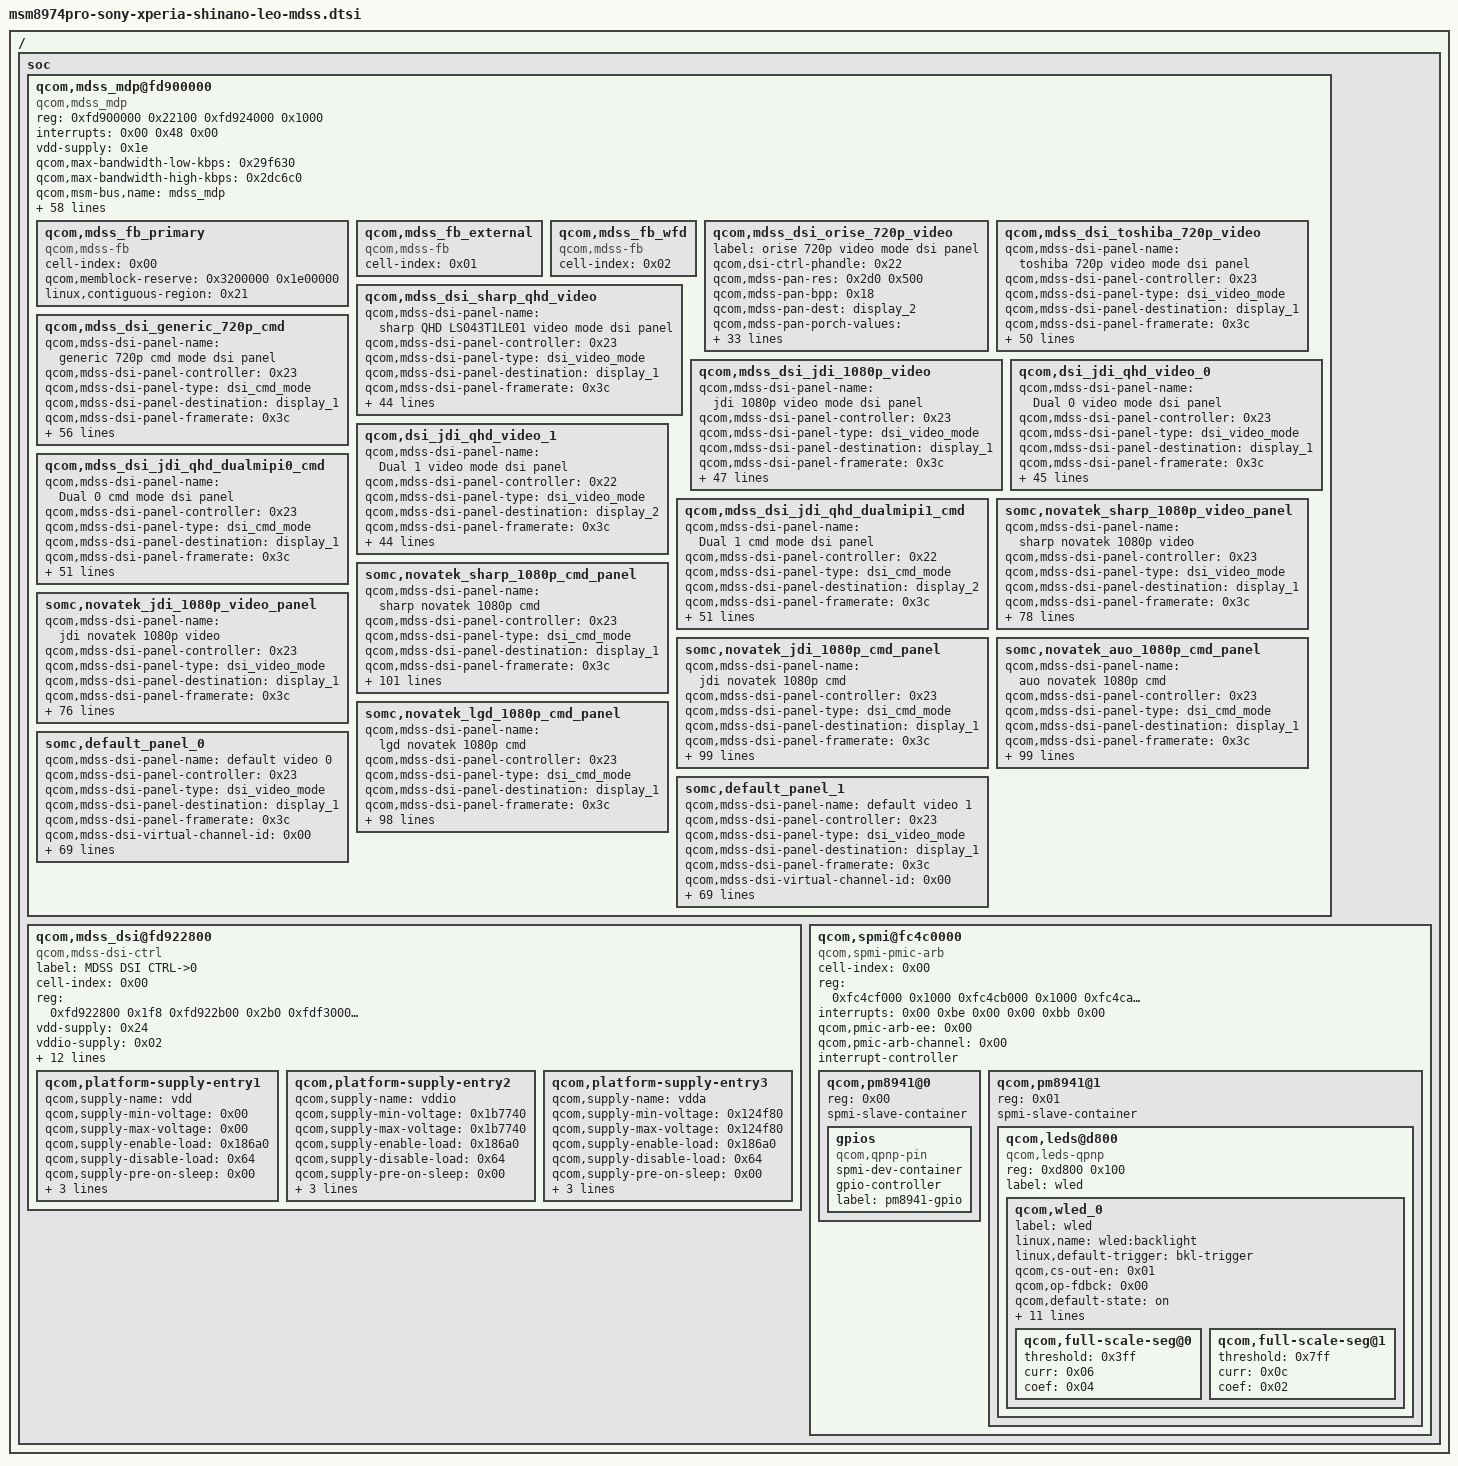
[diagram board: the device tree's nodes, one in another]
/ {
	soc {
		#address-cells = <0x01>;
		#size-cells = <0x01>;
		ranges;

		qcom,mdss_mdp@fd900000 {
			compatible = "qcom,mdss_mdp";
			reg = <0xfd900000 0x22100 0xfd924000 0x1000>;
			reg-names = "mdp_phys\0vbif_phys";
			interrupts = <0x00 0x48 0x00>;
			vdd-supply = <0x1e>;
			qcom,max-bandwidth-low-kbps = <0x29f630>;
			qcom,max-bandwidth-high-kbps = <0x2dc6c0>;
			qcom,msm-bus,name = "mdss_mdp";
			qcom,msm-bus,num-cases = <0x03>;
			qcom,msm-bus,num-paths = <0x01>;
			qcom,msm-bus,vectors-KBps = <0x16 0x200 0x00 0x00 0x16 0x200 0x00 0x61a800 0x16 0x200 0x00 0x61a800>;
			qcom,mdss-ab-factor = <0x02 0x01>;
			qcom,mdss-ib-factor = <0x13 0x0a>;
			qcom,mdss-clk-factor = <0x05 0x04>;
			qcom,mdss-ib-factor-overlap = <0x07 0x04>;
			qcom,max-clk-rate = <0x1312d000>;
			qcom,mdss-pipe-vig-off = <0x1200 0x1600 0x1a00>;
			qcom,mdss-pipe-rgb-off = <0x1e00 0x2200 0x2600>;
			qcom,mdss-pipe-dma-off = <0x2a00 0x2e00>;
			qcom,mdss-pipe-vig-fetch-id = <0x01 0x04 0x07>;
			qcom,mdss-pipe-rgb-fetch-id = <0x10 0x11 0x12>;
			qcom,mdss-pipe-dma-fetch-id = <0x0a 0x0d>;
			qcom,mdss-pipe-vig-xin-id = <0x00 0x04 0x08>;
			qcom,mdss-pipe-rgb-xin-id = <0x01 0x05 0x09>;
			qcom,mdss-pipe-dma-xin-id = <0x02 0x0a>;
			qcom,mdss-pipe-vig-clk-ctrl-offsets = <0x3ac 0x00 0x00 0x3b4 0x00 0x00 0x3bc 0x00 0x00>;
			qcom,mdss-pipe-rgb-clk-ctrl-offsets = <0x3ac 0x04 0x08 0x3b4 0x04 0x08 0x3bc 0x04 0x08>;
			qcom,mdss-pipe-dma-clk-ctrl-offsets = <0x3ac 0x08 0x0c 0x3b4 0x08 0x0c>;
			qcom,mdss-smp-data = <0x16 0x1000>;
			qcom,mdss-ctl-off = <0x600 0x700 0x800 0x900 0xa00>;
			qcom,mdss-mixer-intf-off = <0x3200 0x3600 0x3a00>;
			qcom,mdss-mixer-wb-off = <0x3e00 0x4200>;
			qcom,mdss-dspp-off = <0x4600 0x4a00 0x4e00>;
			qcom,mdss-wb-off = <0x11100 0x11500 0x11900 0x11d00 0x12100>;
			qcom,mdss-intf-off = <0x12500 0x12700 0x12900 0x12b00>;
			qcom,mdss-has-wfd-blk;
			qcom,vbif-settings = <0x04 0x01>;
			qcom,mdp-settings = <0x2e0 0xe9 0x2e4 0x55 0x3ac 0xc0000ccc 0x3b4 0xc0000ccc 0x3bc 0xcccccc 0x4a8 0xcccc0c0 0x4b0 0xccccc0c0 0x4b8 0xccccc000>;
			qcom,mdss-prefill-outstanding-buffer-bytes = <0x400>;
			qcom,mdss-prefill-y-buffer-bytes = <0x1000>;
			qcom,mdss-prefill-scaler-buffer-lines-bilinear = <0x02>;
			qcom,mdss-prefill-scaler-buffer-lines-caf = <0x04>;
			qcom,mdss-prefill-post-scaler-buffer-pixels = <0x00>;
			qcom,mdss-prefill-pingpong-buffer-pixels = <0x1000>;
			qcom,mdss-prefill-fbc-lines = <0x02>;
			qcom,mdss-pingpong-off = <0x12d00 0x12e00 0x12f00>;
			qcom,mdss-has-bwc;
			qcom,mdss-has-decimation;
			qcom,mdss-ad-off = <0x13100 0x13300>;
			vdd-cx-supply = <0x1f>;
			qcom,mdss-pref-prim-intf = "dsi";
			batfet-supply = <0x20>;
			linux,phandle = <0x27>;
			phandle = <0x27>;

			qcom,mdss_fb_primary {
				cell-index = <0x00>;
				compatible = "qcom,mdss-fb";
				qcom,memblock-reserve = <0x3200000 0x1e00000>;
				linux,contiguous-region = <0x21>;
				linux,phandle = <0x26>;
				phandle = <0x26>;
			};

			qcom,mdss_fb_external {
				cell-index = <0x01>;
				compatible = "qcom,mdss-fb";
				linux,phandle = <0x2d>;
				phandle = <0x2d>;
			};

			qcom,mdss_fb_wfd {
				cell-index = <0x02>;
				compatible = "qcom,mdss-fb";
				linux,phandle = <0x2e>;
				phandle = <0x2e>;
			};

			qcom,mdss_dsi_orise_720p_video {
				label = "orise 720p video mode dsi panel";
				qcom,dsi-ctrl-phandle = <0x22>;
				qcom,mdss-pan-res = <0x2d0 0x500>;
				qcom,mdss-pan-bpp = <0x18>;
				qcom,mdss-pan-dest = "display_2";
				qcom,mdss-pan-porch-values = <0x20 0x0c 0x90 0x03 0x04 0x09>;
				qcom,mdss-pan-underflow-clr = <0xff>;
				qcom,mdss-pan-bl-levels = <0x01 0xff>;
				qcom,mdss-pan-dsi-mode = <0x00>;
				qcom,mdss-pan-dsi-h-pulse-mode = <0x00>;
				qcom,mdss-pan-dsi-h-power-stop = <0x00 0x00 0x00>;
				qcom,mdss-pan-dsi-bllp-power-stop = <0x01 0x01>;
				qcom,mdss-pan-dsi-traffic-mode = <0x01>;
				qcom,mdss-pan-dsi-dst-format = <0x03>;
				qcom,mdss-pan-dsi-vc = <0x00>;
				qcom,mdss-pan-dsi-rgb-swap = <0x00>;
				qcom,mdss-pan-dsi-data-lanes = <0x01 0x01 0x01 0x01>;
				qcom,mdss-pan-dsi-dlane-swap = <0x00>;
				qcom,mdss-pan-dsi-t-clk = <0x1b 0x04>;
				qcom,mdss-pan-dsi-stream = <0x00>;
				qcom,mdss-pan-dsi-mdp-tr = <0x00>;
				qcom,mdss-pan-dsi-dma-tr = <0x04>;
				qcom,mdss-pan-dsi-framerate = <0x3c>;
				qcom,panel-phy-regulatorSettings = [03 01 01 00 20 00 01];
				qcom,panel-phy-timingSettings = <0x69291f00 0x5555192a 0x2a030400>;
				qcom,panel-phy-strengthCtrl = [77 06];
				qcom,panel-phy-bistCtrl = [00 00 b1 ff 00 00];
				qcom,panel-phy-laneConfig = [00 c2 45 00 00 00 00 01 75 00 c2 45 00 00 00 00 01 75 00 c2 45 00 00 00 00 01 75 00 c2 45 00 00 00 00 01 75 00 02 45 00 00 00 00 01 97];
				qcom,panel-on-cmds = [05 01 00 00 78 00 02 11 00 05 01 00 00 78 00 02 29 00];
				qcom,on-cmds-dsi-state = "DSI_LP_MODE";
				qcom,panel-off-cmds = [05 01 00 00 32 00 02 28 00 05 01 00 00 78 00 02 10 00];
				qcom,off-cmds-dsi-state = "DSI_LP_MODE";
			};

			qcom,mdss_dsi_toshiba_720p_video {
				qcom,mdss-dsi-panel-name = "toshiba 720p video mode dsi panel";
				qcom,mdss-dsi-panel-controller = <0x23>;
				qcom,mdss-dsi-panel-type = "dsi_video_mode";
				qcom,mdss-dsi-panel-destination = "display_1";
				qcom,mdss-dsi-panel-framerate = <0x3c>;
				qcom,mdss-dsi-virtual-channel-id = <0x00>;
				qcom,mdss-dsi-stream = <0x00>;
				qcom,mdss-dsi-panel-width = <0x2d0>;
				qcom,mdss-dsi-panel-height = <0x500>;
				qcom,mdss-dsi-h-front-porch = <0x90>;
				qcom,mdss-dsi-h-back-porch = <0x20>;
				qcom,mdss-dsi-h-pulse-width = <0x0c>;
				qcom,mdss-dsi-h-sync-skew = <0x00>;
				qcom,mdss-dsi-v-back-porch = <0x03>;
				qcom,mdss-dsi-v-front-porch = <0x09>;
				qcom,mdss-dsi-v-pulse-width = <0x04>;
				qcom,mdss-dsi-h-left-border = <0x00>;
				qcom,mdss-dsi-h-right-border = <0x00>;
				qcom,mdss-dsi-v-top-border = <0x00>;
				qcom,mdss-dsi-v-bottom-border = <0x00>;
				qcom,mdss-dsi-bpp = <0x18>;
				qcom,mdss-dsi-underflow-color = <0xff>;
				qcom,mdss-dsi-border-color = <0x00>;
				qcom,mdss-dsi-on-command = [23 01 00 00 0a 00 02 b0 00 23 01 00 00 0a 00 02 b2 00 23 01 00 00 0a 00 02 b3 0c 23 01 00 00 0a 00 02 b4 02 29 01 00 00 00 00 06 c0 40 02 7f c8 08 29 01 00 00 00 00 10 c1 00 a8 00 00 00 00 00 9d 08 27 00 00 00 00 00 29 01 00 00 00 00 06 c2 00 00 09 00 00 23 01 00 00 0a 00 02 c3 04 29 01 00 00 00 00 04 c4 4d 83 00 29 01 00 00 00 00 0b c6 12 00 08 71 00 00 00 80 00 04 23 01 00 00 0a 00 02 c7 22 29 01 00 00 00 00 05 c8 4c 0c 0c 0c 29 01 00 00 00 00 0e c9 00 40 00 16 32 2e 3a 43 3e 3c 45 79 3f 29 01 00 00 00 00 0e ca 00 46 1a 23 21 1c 25 31 2d 49 5f 7f 3f 29 01 00 00 00 00 0e cb 00 4c 20 3a 42 40 47 4b 42 3e 46 7e 3f 29 01 00 00 00 00 0e cc 00 41 19 21 1d 14 18 1f 1d 25 3f 73 3f 29 01 00 00 00 00 0e cd 23 79 5a 5f 57 4c 51 51 45 3f 4b 7f 3f 29 01 00 00 00 00 0e ce 00 40 14 20 1a 0e 0e 13 08 00 05 46 1c 29 01 00 00 00 00 04 d0 6a 64 01 29 01 00 00 00 00 03 d1 77 d4 23 01 00 00 0a 00 02 d3 33 29 01 00 00 00 00 03 d5 0f 0f 29 01 00 00 00 00 07 d8 34 64 23 25 62 32 29 01 00 00 00 00 0c de 10 7b 11 0a 00 00 00 00 00 00 00 29 01 00 00 00 00 09 fd 04 55 53 00 70 ff 10 73 23 01 00 00 0a 00 02 e2 00 05 01 00 00 78 00 02 11 00 05 01 00 00 32 00 02 29 00];
				qcom,mdss-dsi-off-command = [05 01 00 00 32 00 02 28 00 05 01 00 00 78 00 02 10 00];
				qcom,mdss-dsi-on-command-state = "dsi_lp_mode";
				qcom,mdss-dsi-off-command-state = "dsi_hs_mode";
				qcom,mdss-dsi-h-sync-pulse = <0x00>;
				qcom,mdss-dsi-traffic-mode = "non_burst_sync_event";
				qcom,mdss-dsi-bllp-eof-power-mode;
				qcom,mdss-dsi-bllp-power-mode;
				qcom,mdss-dsi-lane-0-state;
				qcom,mdss-dsi-lane-1-state;
				qcom,mdss-dsi-lane-2-state;
				qcom,mdss-dsi-lane-3-state;
				qcom,mdss-dsi-panel-timings = <0xb0231b00 0x94931e25 0x15030400>;
				qcom,mdss-dsi-t-clk-post = <0x04>;
				qcom,mdss-dsi-t-clk-pre = <0x1b>;
				qcom,mdss-dsi-bl-min-level = <0x01>;
				qcom,mdss-dsi-bl-max-level = <0xfff>;
				qcom,mdss-dsi-dma-trigger = "trigger_sw";
				qcom,mdss-dsi-mdp-trigger = "none";
				qcom,mdss-dsi-bl-pmic-control-type = "bl_ctrl_wled";
				qcom,mdss-dsi-pan-enable-dynamic-fps;
				qcom,mdss-dsi-pan-fps-update = "dfps_immediate_porch_mode";
				qcom,mdss-dsi-min-refresh-rate = <0x2d>;
				qcom,mdss-dsi-reset-sequence = <0x01 0x14 0x00 0xc8 0x01 0x14>;
				qcom,cont-splash-enabled;
			};

			qcom,mdss_dsi_sharp_qhd_video {
				qcom,mdss-dsi-panel-name = "sharp QHD LS043T1LE01 video mode dsi panel";
				qcom,mdss-dsi-panel-controller = <0x23>;
				qcom,mdss-dsi-panel-type = "dsi_video_mode";
				qcom,mdss-dsi-panel-destination = "display_1";
				qcom,mdss-dsi-panel-framerate = <0x3c>;
				qcom,mdss-dsi-virtual-channel-id = <0x00>;
				qcom,mdss-dsi-stream = <0x00>;
				qcom,mdss-dsi-panel-width = <0x21c>;
				qcom,mdss-dsi-panel-height = <0x3c0>;
				qcom,mdss-dsi-h-front-porch = <0x30>;
				qcom,mdss-dsi-h-back-porch = <0x50>;
				qcom,mdss-dsi-h-pulse-width = <0x20>;
				qcom,mdss-dsi-h-sync-skew = <0x00>;
				qcom,mdss-dsi-v-back-porch = <0x0f>;
				qcom,mdss-dsi-v-front-porch = <0x03>;
				qcom,mdss-dsi-v-pulse-width = <0x0a>;
				qcom,mdss-dsi-h-left-border = <0x00>;
				qcom,mdss-dsi-h-right-border = <0x00>;
				qcom,mdss-dsi-v-top-border = <0x00>;
				qcom,mdss-dsi-v-bottom-border = <0x00>;
				qcom,mdss-dsi-bpp = <0x18>;
				qcom,mdss-dsi-color-order = "rgb_swap_bgr";
				qcom,mdss-dsi-underflow-color = <0xff>;
				qcom,mdss-dsi-border-color = <0x00>;
				qcom,mdss-dsi-on-command = [05 01 00 00 32 00 02 01 00 05 01 00 00 0a 00 02 11 00 15 01 00 00 0a 00 02 53 2c 15 01 00 00 0a 00 02 51 ff 05 01 00 00 0a 00 02 29 00 15 01 00 00 0a 00 02 ae 03 15 01 00 00 0a 00 02 3a 77];
				qcom,mdss-dsi-off-command = [05 01 00 00 0a 00 02 28 00 05 01 00 00 78 00 02 10 00];
				qcom,mdss-dsi-on-command-state = "dsi_lp_mode";
				qcom,mdss-dsi-off-command-state = "dsi_hs_mode";
				qcom,mdss-dsi-h-sync-pulse = <0x01>;
				qcom,mdss-dsi-traffic-mode = "non_burst_sync_pulse";
				qcom,mdss-dsi-bllp-eof-power-mode;
				qcom,mdss-dsi-bllp-power-mode;
				qcom,mdss-dsi-lane-0-state;
				qcom,mdss-dsi-lane-1-state;
				qcom,mdss-dsi-panel-timings = <0x461d2000 0x393a2121 0x32030400>;
				qcom,mdss-dsi-t-clk-post = <0x04>;
				qcom,mdss-dsi-t-clk-pre = <0x1c>;
				qcom,mdss-dsi-bl-min-level = <0x01>;
				qcom,mdss-dsi-bl-max-level = <0xfff>;
				qcom,mdss-dsi-dma-trigger = "trigger_sw";
				qcom,mdss-dsi-mdp-trigger = "trigger_sw";
				qcom,mdss-dsi-bl-pmic-control-type = "bl_ctrl_wled";
				qcom,mdss-dsi-reset-sequence = <0x01 0x14 0x00 0xc8 0x01 0x14>;
			};

			qcom,mdss_dsi_generic_720p_cmd {
				qcom,mdss-dsi-panel-name = "generic 720p cmd mode dsi panel";
				qcom,mdss-dsi-panel-controller = <0x23>;
				qcom,mdss-dsi-panel-type = "dsi_cmd_mode";
				qcom,mdss-dsi-panel-destination = "display_1";
				qcom,mdss-dsi-panel-framerate = <0x3c>;
				qcom,mdss-dsi-stream = <0x00>;
				qcom,mdss-dsi-panel-width = <0x300>;
				qcom,mdss-dsi-panel-height = <0x500>;
				qcom,mdss-dsi-h-front-porch = <0x1a>;
				qcom,mdss-dsi-h-back-porch = <0x1a>;
				qcom,mdss-dsi-h-pulse-width = <0x1a>;
				qcom,mdss-dsi-h-sync-skew = <0x00>;
				qcom,mdss-dsi-v-back-porch = <0x02>;
				qcom,mdss-dsi-v-front-porch = <0x02>;
				qcom,mdss-dsi-v-pulse-width = <0x02>;
				qcom,mdss-dsi-h-left-border = <0x00>;
				qcom,mdss-dsi-h-right-border = <0x00>;
				qcom,mdss-dsi-v-top-border = <0x00>;
				qcom,mdss-dsi-v-bottom-border = <0x00>;
				qcom,mdss-dsi-bpp = <0x18>;
				qcom,mdss-dsi-underflow-color = <0xff>;
				qcom,mdss-dsi-border-color = <0x00>;
				qcom,mdss-dsi-on-command = [05 01 00 00 78 00 01 11 15 01 00 00 0a 00 02 36 00 05 01 00 00 0a 00 01 29 15 01 00 00 0a 00 02 53 24 15 01 00 00 0a 00 02 35 00];
				qcom,mdss-dsi-off-command = [05 01 00 00 0a 00 01 34 05 01 00 00 78 00 01 10 05 01 00 00 78 00 01 28 15 01 00 00 0a 00 02 53 00];
				qcom,mdss-dsi-on-command-state = "dsi_lp_mode";
				qcom,mdss-dsi-off-command-state = "dsi_hs_mode";
				qcom,mdss-dsi-h-sync-pulse = <0x00>;
				qcom,mdss-dsi-traffic-mode = "non_burst_sync_event";
				qcom,mdss-dsi-bllp-eof-power-mode;
				qcom,mdss-dsi-bllp-power-mode;
				qcom,mdss-dsi-lane-0-state;
				qcom,mdss-dsi-lane-1-state;
				qcom,mdss-dsi-lane-2-state;
				qcom,mdss-dsi-lane-3-state;
				qcom,mdss-dsi-te-pin-select = <0x01>;
				qcom,mdss-dsi-wr-mem-start = <0x2c>;
				qcom,mdss-dsi-wr-mem-continue = <0x3c>;
				qcom,mdss-dsi-te-dcs-command = <0x01>;
				qcom,mdss-dsi-te-check-enable;
				qcom,mdss-dsi-te-using-te-pin;
				qcom,mdss-dsi-panel-timings = <0x6e261b00 0x35342028 0x17030400>;
				qcom,mdss-dsi-t-clk-post = <0x20>;
				qcom,mdss-dsi-t-clk-pre = <0x2a>;
				qcom,mdss-dsi-bl-min-level = <0x01>;
				qcom,mdss-dsi-bl-max-level = <0xff>;
				qcom,mdss-dsi-bl-pmic-pwm-frequency = <0x64>;
				qcom,mdss-dsi-bl-pmic-bank-select = <0x07>;
				qcom,mdss-dsi-dma-trigger = "trigger_sw";
				qcom,mdss-dsi-mdp-trigger = "none";
				qcom,mdss-dsi-bl-pmic-control-type = "bl_ctrl_pwm";
				qcom,mdss-dsi-reset-sequence = <0x01 0x14 0x00 0xc8 0x01 0x14>;
				qcom,panel-roi-alignment = <0x02 0x02 0x02 0x02 0x00 0x00>;
				qcom,partial-update-enabled;
				qcom,cont-splash-enabled;
			};

			qcom,mdss_dsi_jdi_1080p_video {
				qcom,mdss-dsi-panel-name = "jdi 1080p video mode dsi panel";
				qcom,mdss-dsi-panel-controller = <0x23>;
				qcom,mdss-dsi-panel-type = "dsi_video_mode";
				qcom,mdss-dsi-panel-destination = "display_1";
				qcom,mdss-dsi-panel-framerate = <0x3c>;
				qcom,mdss-dsi-virtual-channel-id = <0x00>;
				qcom,mdss-dsi-stream = <0x00>;
				qcom,mdss-dsi-panel-width = <0x438>;
				qcom,mdss-dsi-panel-height = <0x780>;
				qcom,mdss-dsi-h-front-porch = <0x60>;
				qcom,mdss-dsi-h-back-porch = <0x40>;
				qcom,mdss-dsi-h-pulse-width = <0x10>;
				qcom,mdss-dsi-h-sync-skew = <0x00>;
				qcom,mdss-dsi-v-back-porch = <0x10>;
				qcom,mdss-dsi-v-front-porch = <0x04>;
				qcom,mdss-dsi-v-pulse-width = <0x01>;
				qcom,mdss-dsi-h-left-border = <0x00>;
				qcom,mdss-dsi-h-right-border = <0x00>;
				qcom,mdss-dsi-v-top-border = <0x00>;
				qcom,mdss-dsi-v-bottom-border = <0x00>;
				qcom,mdss-dsi-bpp = <0x18>;
				qcom,mdss-dsi-underflow-color = <0xff>;
				qcom,mdss-dsi-border-color = <0x00>;
				qcom,mdss-dsi-on-command = [15 01 00 00 00 00 02 55 00 15 01 00 00 00 00 02 53 2c 15 01 00 00 00 00 02 35 00 05 01 00 00 78 00 02 29 00 05 01 00 00 78 00 02 11 00];
				qcom,mdss-dsi-off-command = [05 01 00 00 02 00 02 28 00 05 01 00 00 79 00 02 10 00];
				qcom,mdss-dsi-on-command-state = "dsi_lp_mode";
				qcom,mdss-dsi-off-command-state = "dsi_hs_mode";
				qcom,mdss-dsi-h-sync-pulse = <0x00>;
				qcom,mdss-dsi-traffic-mode = "burst_mode";
				qcom,mdss-dsi-bllp-eof-power-mode;
				qcom,mdss-dsi-bllp-power-mode;
				qcom,mdss-dsi-lane-0-state;
				qcom,mdss-dsi-lane-1-state;
				qcom,mdss-dsi-lane-2-state;
				qcom,mdss-dsi-lane-3-state;
				qcom,mdss-dsi-panel-timings = <0xe7362400 0x666a2a3a 0x2d030400>;
				qcom,mdss-dsi-t-clk-post = <0x04>;
				qcom,mdss-dsi-t-clk-pre = <0x1b>;
				qcom,mdss-dsi-bl-min-level = <0x01>;
				qcom,mdss-dsi-bl-max-level = <0xfff>;
				qcom,mdss-dsi-dma-trigger = "trigger_sw";
				qcom,mdss-dsi-mdp-trigger = "none";
				qcom,mdss-dsi-bl-pmic-control-type = "bl_ctrl_wled";
				qcom,mdss-dsi-reset-sequence = <0x01 0x14 0x00 0xc8 0x01 0x14>;
				qcom,mdss-pan-physical-width-dimension = <0x3d>;
				qcom,mdss-pan-physical-height-dimension = <0x6e>;
				qcom,cont-splash-enabled;
			};

			qcom,dsi_jdi_qhd_video_0 {
				qcom,mdss-dsi-panel-name = "Dual 0 video mode dsi panel";
				qcom,mdss-dsi-panel-controller = <0x23>;
				qcom,mdss-dsi-panel-type = "dsi_video_mode";
				qcom,mdss-dsi-panel-destination = "display_1";
				qcom,mdss-dsi-panel-framerate = <0x3c>;
				qcom,mdss-dsi-virtual-channel-id = <0x00>;
				qcom,mdss-dsi-stream = <0x00>;
				qcom,mdss-dsi-panel-width = <0x500>;
				qcom,mdss-dsi-panel-height = <0x5a0>;
				qcom,mdss-dsi-h-front-porch = <0x78>;
				qcom,mdss-dsi-h-back-porch = <0x2c>;
				qcom,mdss-dsi-h-pulse-width = <0x10>;
				qcom,mdss-dsi-h-sync-skew = <0x00>;
				qcom,mdss-dsi-v-back-porch = <0x04>;
				qcom,mdss-dsi-v-front-porch = <0x08>;
				qcom,mdss-dsi-v-pulse-width = <0x04>;
				qcom,mdss-dsi-h-left-border = <0x00>;
				qcom,mdss-dsi-h-right-border = <0x00>;
				qcom,mdss-dsi-v-top-border = <0x00>;
				qcom,mdss-dsi-v-bottom-border = <0x00>;
				qcom,mdss-dsi-bpp = <0x18>;
				qcom,mdss-dsi-underflow-color = <0xff>;
				qcom,mdss-dsi-border-color = <0x00>;
				qcom,mdss-dsi-h-sync-pulse = <0x00>;
				qcom,mdss-dsi-traffic-mode = "non_burst_sync_event";
				qcom,mdss-dsi-bllp-eof-power-mode;
				qcom,mdss-dsi-bllp-power-mode;
				qcom,mdss-dsi-panel-broadcast-mode;
				qcom,mdss-dsi-lane-0-state;
				qcom,mdss-dsi-lane-1-state;
				qcom,mdss-dsi-lane-2-state;
				qcom,mdss-dsi-lane-3-state;
				qcom,mdss-dsi-panel-timings = <0xcd322200 0x60642634 0x29030400>;
				qcom,mdss-dsi-t-clk-post = <0x03>;
				qcom,mdss-dsi-t-clk-pre = <0x27>;
				qcom,mdss-dsi-bl-max-level = <0xfff>;
				qcom,mdss-dsi-dma-trigger = "trigger_sw";
				qcom,mdss-dsi-mdp-trigger = "none";
				qcom,mdss-dsi-bl-pmic-control-type = "bl_ctrl_pwm";
				qcom,mdss-dsi-on-command = [05 01 00 00 0a 00 01 00 15 01 00 00 0a 00 02 3a 77 39 01 00 00 0a 00 05 2a 00 00 04 ff 39 01 00 00 0a 00 05 2b 00 00 05 9f 15 01 00 00 0a 00 02 35 00 39 01 00 00 0a 00 03 44 00 00 15 01 00 00 0a 00 02 51 ff 15 01 00 00 0a 00 02 53 24 15 01 00 00 0a 00 02 55 00 05 01 00 00 78 00 01 11 23 01 00 00 0a 00 02 b0 00 29 01 00 00 0a 00 02 b3 14 29 01 00 00 0a 00 14 ce 7d 40 48 56 67 78 88 98 a7 b5 c3 d1 de e9 f2 fa ff 04 00 23 01 00 00 0a 00 02 b0 03 05 01 00 00 10 00 01 29];
				qcom,mdss-dsi-on-command-state = "dsi_lp_mode";
				qcom,mdss-dsi-off-command = [05 01 00 00 32 00 02 28 00 05 01 00 00 78 00 02 10 00];
				qcom,mdss-dsi-off-command-state = "dsi_hs_mode";
				qcom,mdss-dsi-reset-sequence = <0x01 0x14 0x00 0xc8 0x01 0x14>;
			};

			qcom,dsi_jdi_qhd_video_1 {
				qcom,mdss-dsi-panel-name = "Dual 1 video mode dsi panel";
				qcom,mdss-dsi-panel-controller = <0x22>;
				qcom,mdss-dsi-panel-type = "dsi_video_mode";
				qcom,mdss-dsi-panel-destination = "display_2";
				qcom,mdss-dsi-panel-framerate = <0x3c>;
				qcom,mdss-dsi-virtual-channel-id = <0x00>;
				qcom,mdss-dsi-stream = <0x00>;
				qcom,mdss-dsi-panel-width = <0x500>;
				qcom,mdss-dsi-panel-height = <0x5a0>;
				qcom,mdss-dsi-h-front-porch = <0x78>;
				qcom,mdss-dsi-h-back-porch = <0x2c>;
				qcom,mdss-dsi-h-pulse-width = <0x10>;
				qcom,mdss-dsi-h-sync-skew = <0x00>;
				qcom,mdss-dsi-v-back-porch = <0x04>;
				qcom,mdss-dsi-v-front-porch = <0x08>;
				qcom,mdss-dsi-v-pulse-width = <0x04>;
				qcom,mdss-dsi-h-left-border = <0x00>;
				qcom,mdss-dsi-h-right-border = <0x00>;
				qcom,mdss-dsi-v-top-border = <0x00>;
				qcom,mdss-dsi-v-bottom-border = <0x00>;
				qcom,mdss-dsi-bpp = <0x18>;
				qcom,mdss-dsi-underflow-color = <0xff>;
				qcom,mdss-dsi-border-color = <0x00>;
				qcom,mdss-dsi-h-sync-pulse = <0x00>;
				qcom,mdss-dsi-traffic-mode = "non_burst_sync_event";
				qcom,mdss-dsi-bllp-eof-power-mode;
				qcom,mdss-dsi-bllp-power-mode;
				qcom,mdss-dsi-lane-0-state;
				qcom,mdss-dsi-lane-1-state;
				qcom,mdss-dsi-lane-2-state;
				qcom,mdss-dsi-lane-3-state;
				qcom,mdss-dsi-panel-broadcast-mode;
				qcom,mdss-dsi-panel-timings = <0xcd322200 0x60642634 0x29030400>;
				qcom,mdss-dsi-t-clk-post = <0x03>;
				qcom,mdss-dsi-t-clk-pre = <0x27>;
				qcom,mdss-dsi-bl-min-level = <0x01>;
				qcom,mdss-dsi-bl-max-level = <0xfff>;
				qcom,mdss-dsi-dma-trigger = "trigger_sw";
				qcom,mdss-dsi-mdp-trigger = "none";
				qcom,mdss-dsi-on-command = [05 01 00 00 0a 00 01 00 15 01 00 00 0a 00 02 3a 77 39 01 00 00 0a 00 05 2a 00 00 04 ff 39 01 00 00 0a 00 05 2b 00 00 05 9f 15 01 00 00 0a 00 02 35 00 39 01 00 00 0a 00 03 44 00 00 15 01 00 00 0a 00 02 51 ff 15 01 00 00 0a 00 02 53 24 15 01 00 00 0a 00 02 55 00 05 01 00 00 78 00 01 11 23 01 00 00 0a 00 02 b0 00 29 01 00 00 0a 00 02 b3 14 29 01 00 00 0a 00 14 ce 7d 40 48 56 67 78 88 98 a7 b5 c3 d1 de e9 f2 fa ff 04 00 23 01 00 00 0a 00 02 b0 03 05 01 00 00 10 00 01 29];
				qcom,mdss-dsi-on-command-state = "dsi_lp_mode";
				qcom,mdss-dsi-off-command = [05 01 00 00 32 00 02 28 00 05 01 00 00 78 00 02 10 00];
				qcom,mdss-dsi-off-command-state = "dsi_hs_mode";
				qcom,mdss-dsi-reset-sequence = <0x01 0x14 0x00 0xc8 0x01 0x14>;
			};

			qcom,mdss_dsi_jdi_qhd_dualmipi0_cmd {
				qcom,mdss-dsi-panel-name = "Dual 0 cmd mode dsi panel";
				qcom,mdss-dsi-panel-controller = <0x23>;
				qcom,mdss-dsi-panel-type = "dsi_cmd_mode";
				qcom,mdss-dsi-panel-destination = "display_1";
				qcom,mdss-dsi-panel-framerate = <0x3c>;
				qcom,mdss-dsi-virtual-channel-id = <0x00>;
				qcom,mdss-dsi-stream = <0x00>;
				qcom,mdss-dsi-panel-width = <0x500>;
				qcom,mdss-dsi-panel-height = <0x5a0>;
				qcom,mdss-dsi-h-front-porch = <0x78>;
				qcom,mdss-dsi-h-back-porch = <0x2c>;
				qcom,mdss-dsi-h-pulse-width = <0x10>;
				qcom,mdss-dsi-h-sync-skew = <0x00>;
				qcom,mdss-dsi-v-back-porch = <0x04>;
				qcom,mdss-dsi-v-front-porch = <0x08>;
				qcom,mdss-dsi-v-pulse-width = <0x04>;
				qcom,mdss-dsi-h-left-border = <0x00>;
				qcom,mdss-dsi-h-right-border = <0x00>;
				qcom,mdss-dsi-v-top-border = <0x00>;
				qcom,mdss-dsi-v-bottom-border = <0x00>;
				qcom,mdss-dsi-bpp = <0x18>;
				qcom,mdss-dsi-color-order = "rgb_swap_rgb";
				qcom,mdss-dsi-underflow-color = <0xff>;
				qcom,mdss-dsi-border-color = <0x00>;
				qcom,mdss-dsi-h-sync-pulse = <0x00>;
				qcom,mdss-dsi-traffic-mode = "non_burst_sync_event";
				qcom,mdss-dsi-lane-map = "lane_map_0123";
				qcom,mdss-dsi-bllp-eof-power-mode;
				qcom,mdss-dsi-bllp-power-mode;
				qcom,mdss-dsi-panel-broadcast-mode;
				qcom,mdss-dsi-lane-0-state;
				qcom,mdss-dsi-lane-1-state;
				qcom,mdss-dsi-lane-2-state;
				qcom,mdss-dsi-lane-3-state;
				qcom,mdss-dsi-panel-timings = <0xcd322200 0x60642634 0x29030400>;
				qcom,mdss-dsi-reset-sequence = <0x01 0xc8 0x00 0xc8 0x01 0x14>;
				qcom,mdss-dsi-t-clk-post = <0x03>;
				qcom,mdss-dsi-t-clk-pre = <0x27>;
				qcom,mdss-dsi-bl-max-level = <0xfff>;
				qcom,mdss-dsi-dma-trigger = "trigger_sw";
				qcom,mdss-dsi-mdp-trigger = "none";
				qcom,mdss-dsi-te-pin-select = <0x01>;
				qcom,mdss-dsi-te-v-sync-rd-ptr-irq-line = <0x2c>;
				qcom,mdss-dsi-te-v-sync-continues-lines = <0x3c>;
				qcom,mdss-dsi-te-dcs-command = <0x01>;
				qcom,mdss-dsi-te-check-enable;
				qcom,mdss-dsi-te-using-te-pin;
				qcom,mdss-dsi-on-command = <0x29010000 0x2b0 0x3050100 0xa0001 0x150100 0xa0002 0x3a773901 0xa00 0x52a0000 0x4ff3901 0xa00 0x52b0000 0x59f1501 0xa00 0x2350039 0x100000a 0x34400 0x150100 0xa0002 0x51ff1501 0xa00 0x2532415 0x100000a 0x25500 0x5010000 0x78000111 0x5010000 0x10000129>;
				qcom,mdss-dsi-on-command-state = "dsi_lp_mode";
				qcom,mdss-dsi-off-command = [05 01 00 00 32 00 02 28 00 05 01 00 00 78 00 02 10 00];
				qcom,mdss-dsi-off-command-state = "dsi_hs_mode";
			};

			qcom,mdss_dsi_jdi_qhd_dualmipi1_cmd {
				qcom,mdss-dsi-panel-name = "Dual 1 cmd mode dsi panel";
				qcom,mdss-dsi-panel-controller = <0x22>;
				qcom,mdss-dsi-panel-type = "dsi_cmd_mode";
				qcom,mdss-dsi-panel-destination = "display_2";
				qcom,mdss-dsi-panel-framerate = <0x3c>;
				qcom,mdss-dsi-virtual-channel-id = <0x00>;
				qcom,mdss-dsi-stream = <0x00>;
				qcom,mdss-dsi-panel-width = <0x500>;
				qcom,mdss-dsi-panel-height = <0x5a0>;
				qcom,mdss-dsi-h-front-porch = <0x78>;
				qcom,mdss-dsi-h-back-porch = <0x2c>;
				qcom,mdss-dsi-h-pulse-width = <0x10>;
				qcom,mdss-dsi-h-sync-skew = <0x00>;
				qcom,mdss-dsi-v-back-porch = <0x04>;
				qcom,mdss-dsi-v-front-porch = <0x08>;
				qcom,mdss-dsi-v-pulse-width = <0x04>;
				qcom,mdss-dsi-h-left-border = <0x00>;
				qcom,mdss-dsi-h-right-border = <0x00>;
				qcom,mdss-dsi-v-top-border = <0x00>;
				qcom,mdss-dsi-v-bottom-border = <0x00>;
				qcom,mdss-dsi-bpp = <0x18>;
				qcom,mdss-dsi-color-order = "rgb_swap_rgb";
				qcom,mdss-dsi-underflow-color = <0xff>;
				qcom,mdss-dsi-border-color = <0x00>;
				qcom,mdss-dsi-h-sync-pulse = <0x00>;
				qcom,mdss-dsi-traffic-mode = "non_burst_sync_event";
				qcom,mdss-dsi-lane-map = "lane_map_0123";
				qcom,mdss-dsi-bllp-eof-power-mode;
				qcom,mdss-dsi-bllp-power-mode;
				qcom,mdss-dsi-panel-broadcast-mode;
				qcom,mdss-dsi-lane-0-state;
				qcom,mdss-dsi-lane-1-state;
				qcom,mdss-dsi-lane-2-state;
				qcom,mdss-dsi-lane-3-state;
				qcom,mdss-dsi-panel-timings = <0xcd322200 0x60642634 0x29030400>;
				qcom,mdss-dsi-reset-sequence = <0x01 0xc8 0x00 0xc8 0x01 0x14>;
				qcom,mdss-dsi-t-clk-post = <0x03>;
				qcom,mdss-dsi-t-clk-pre = <0x27>;
				qcom,mdss-dsi-bl-max-level = <0xfff>;
				qcom,mdss-dsi-dma-trigger = "trigger_sw";
				qcom,mdss-dsi-mdp-trigger = "none";
				qcom,mdss-dsi-te-pin-select = <0x01>;
				qcom,mdss-dsi-te-v-sync-rd-ptr-irq-line = <0x2c>;
				qcom,mdss-dsi-te-v-sync-continues-lines = <0x3c>;
				qcom,mdss-dsi-te-dcs-command = <0x01>;
				qcom,mdss-dsi-te-check-enable;
				qcom,mdss-dsi-te-using-te-pin;
				qcom,mdss-dsi-on-command = <0x29010000 0x2b0 0x3050100 0xa0001 0x150100 0xa0002 0x3a773901 0xa00 0x52a0000 0x4ff3901 0xa00 0x52b0000 0x59f1501 0xa00 0x2350039 0x100000a 0x34400 0x150100 0xa0002 0x51ff1501 0xa00 0x2532415 0x100000a 0x25500 0x5010000 0x78000111 0x5010000 0x10000129>;
				qcom,mdss-dsi-on-command-state = "dsi_lp_mode";
				qcom,mdss-dsi-off-command = [05 01 00 00 32 00 02 28 00 05 01 00 00 78 00 02 10 00];
				qcom,mdss-dsi-off-command-state = "dsi_hs_mode";
			};

			somc,novatek_sharp_1080p_video_panel {
				qcom,mdss-dsi-panel-name = "sharp novatek 1080p video";
				qcom,mdss-dsi-panel-controller = <0x23>;
				qcom,mdss-dsi-panel-type = "dsi_video_mode";
				qcom,mdss-dsi-panel-destination = "display_1";
				qcom,mdss-dsi-panel-framerate = <0x3c>;
				qcom,mdss-dsi-virtual-channel-id = <0x00>;
				qcom,mdss-dsi-stream = <0x00>;
				qcom,mdss-dsi-panel-width = <0x438>;
				qcom,mdss-dsi-panel-height = <0x780>;
				qcom,mdss-dsi-h-front-porch = <0x88>;
				qcom,mdss-dsi-h-back-porch = <0x14>;
				qcom,mdss-dsi-h-pulse-width = <0x3c>;
				qcom,mdss-dsi-h-sync-skew = <0x00>;
				qcom,mdss-dsi-v-back-porch = <0x03>;
				qcom,mdss-dsi-v-front-porch = <0x04>;
				qcom,mdss-dsi-v-pulse-width = <0x02>;
				qcom,mdss-dsi-h-left-border = <0x00>;
				qcom,mdss-dsi-h-right-border = <0x00>;
				qcom,mdss-dsi-v-top-border = <0x00>;
				qcom,mdss-dsi-v-bottom-border = <0x00>;
				qcom,mdss-dsi-bpp = <0x18>;
				qcom,mdss-dsi-underflow-color = <0x00>;
				qcom,mdss-dsi-border-color = <0x00>;
				somc,mdss-dsi-init-command = [15 01 00 00 00 00 02 bb 03 39 01 00 00 00 00 06 3b 03 05 04 50 88 15 01 00 00 00 00 02 ff 24 15 01 00 00 00 00 02 fb 01 15 01 00 00 00 00 02 c4 9a 15 01 00 00 00 00 02 ff 10];
				qcom,mdss-dsi-on-command = <0x5010000 0x96000111 0x5010000 0x28000129>;
				qcom,mdss-dsi-off-command = [15 01 00 00 00 00 02 ff 10 05 01 00 00 14 00 01 28 05 01 00 00 50 00 01 10];
				qcom,mdss-dsi-on-command-state = "dsi_lp_mode";
				qcom,mdss-dsi-off-command-state = "dsi_hs_mode";
				qcom,mdss-dsi-h-sync-pulse = <0x01>;
				qcom,mdss-dsi-traffic-mode = "non_burst_sync_event";
				qcom,mdss-dsi-bllp-eof-power-mode;
				qcom,mdss-dsi-bllp-power-mode;
				qcom,mdss-dsi-lane-0-state;
				qcom,mdss-dsi-lane-1-state;
				qcom,mdss-dsi-lane-2-state;
				qcom,mdss-dsi-lane-3-state;
				qcom,mdss-dsi-panel-timings = <0xe6382600 0x686e2a3c 0x2c030400>;
				qcom,mdss-dsi-lp11-init;
				qcom,mdss-dsi-t-clk-post = <0x02>;
				qcom,mdss-dsi-t-clk-pre = <0x2b>;
				qcom,mdss-dsi-bl-min-level = <0x01>;
				qcom,mdss-dsi-bl-max-level = <0xfff>;
				qcom,mdss-brightness-max-level = <0xfff>;
				qcom,mdss-dsi-dma-trigger = "trigger_sw";
				qcom,mdss-dsi-mdp-trigger = "none";
				qcom,mdss-dsi-bl-pmic-control-type = "bl_ctrl_wled";
				qcom,mdss-dsi-pan-enable-dynamic-fps;
				qcom,mdss-dsi-pan-fps-update = "dfps_suspend_resume_mode";
				qcom,cont-splash-enabled;
				qcom,mdss-dsi-tx-eot-append;
				somc,driver-ic = <0x00>;
				somc,dric-gpio = <0x05 0x1a 0x00>;
				somc,touch-reset-gpio = <0x05 0x55 0x00>;
				somc,mul-channel-scaling = <0x03>;
				somc,mdss-phy-size-mm = <0x40 0x72>;
				somc,mdss-dsi-lane-config = [00 c2 ef 00 00 00 00 01 ff 00 c2 ef 00 00 00 00 01 ff 00 c2 ef 00 00 00 00 01 ff 00 c2 ef 00 00 00 00 01 ff 00 02 45 00 00 00 00 01 97];
				somc,mdss-dsi-disp-on-in-hs = <0x01>;
				somc,mdss-dsi-wait-time-before-on-cmd = <0x96>;
				somc,lcd-id = <0x01>;
				somc,lcd-id-adc = <0x347d8 0x3e800>;
				somc,disp-en-on-pre = <0xc8>;
				somc,disp-en-on-post = <0x0a>;
				somc,pw-on-rst-seq = <0x01 0x01 0x00 0x01 0x01 0x14>;
				somc,disp-en-off-post = <0xc8>;
				somc,pw-off-rst-seq = <0x00 0x05>;
				somc,pw-down-period = <0x64>;
				somc,mdss-dsi-pre-uv-command = [23 01 00 00 00 00 02 b0 04];
				somc,mdss-dsi-uv-command = <0x6010000 0x1da 0x6010000 0x1db>;
				somc,mdss-dsi-uv-param-type = <0x04>;
				somc,mdss-dsi-pcc-table-size = <0xe1>;
				somc,mdss-dsi-pcc-table = <0x00 0x01 0x38 0x3b 0x38 0x3b 0x5700 0x7000 0x8000 0x00 0x02 0x34 0x37 0x38 0x3b 0x5900 0x6f00 0x8000 0x00 0x03 0x30 0x33 0x38 0x3b 0x5c00 0x6e00 0x8000 0x00 0x04 0x2c 0x2f 0x38 0x3b 0x5d80 0x6c80 0x8000 0x00 0x05 0x28 0x2b 0x38 0x3b 0x6080 0x6c80 0x8000 0x00 0x06 0x24 0x27 0x38 0x3b 0x6380 0x6c80 0x8000 0x00 0x07 0x20 0x23 0x38 0x3b 0x6700 0x6c00 0x8000 0x00 0x08 0x1c 0x1f 0x38 0x3b 0x6980 0x6b00 0x8000 0x00 0x09 0x18 0x1b 0x38 0x3b 0x6d00 0x6a80 0x8000 0x00 0x0a 0x14 0x17 0x38 0x3b 0x7180 0x6900 0x8000 0x00 0x0b 0x10 0x13 0x38 0x3b 0x7800 0x6800 0x8000 0x00 0x0c 0x0c 0x0f 0x38 0x3b 0x7d00 0x6700 0x8000 0x00 0x0d 0x08 0x0b 0x38 0x3b 0x8000 0x6500 0x7d00 0x00 0x0e 0x04 0x07 0x38 0x3b 0x8000 0x6000 0x7700 0x00 0x0f 0x00 0x03 0x38 0x3b 0x8000 0x5900 0x7000 0x00 0x10 0x38 0x3b 0x34 0x37 0x5900 0x7280 0x8000 0x00 0x11 0x34 0x37 0x34 0x37 0x5b00 0x7100 0x8000 0x00 0x12 0x30 0x33 0x34 0x37 0x5e00 0x7180 0x8000 0x00 0x13 0x2c 0x2f 0x34 0x37 0x6080 0x7180 0x8000 0x00 0x14 0x28 0x2b 0x34 0x37 0x6400 0x7000 0x8000 0x00 0x15 0x24 0x27 0x34 0x37 0x6700 0x7000 0x8000 0x00 0x16 0x20 0x23 0x34 0x37 0x6900 0x6f00 0x8000 0x00 0x17 0x1c 0x1f 0x34 0x37 0x6c00 0x6e80 0x8000 0x00 0x18 0x18 0x1b 0x34 0x37 0x7000 0x6d80 0x8000 0x00 0x19 0x14 0x17 0x34 0x37 0x7580 0x6b80 0x8000 0x00 0x1a 0x10 0x13 0x34 0x37 0x7b00 0x6a80 0x8000 0x00 0x1b 0x0c 0x0f 0x34 0x37 0x8000 0x6a80 0x8000 0x00 0x1c 0x08 0x0b 0x34 0x37 0x8000 0x6600 0x7c00 0x00 0x1d 0x04 0x07 0x34 0x37 0x8000 0x6100 0x7400 0x00 0x1e 0x00 0x03 0x34 0x37 0x8000 0x5b00 0x6e00 0x00 0x1f 0x38 0x3b 0x30 0x33 0x5c80 0x7600 0x8000 0x00 0x20 0x34 0x37 0x30 0x33 0x5e00 0x7500 0x8000 0x00 0x21 0x30 0x33 0x30 0x33 0x6100 0x7480 0x8000 0x00 0x22 0x2c 0x2f 0x30 0x33 0x6400 0x7400 0x8000 0x00 0x23 0x28 0x2b 0x30 0x33 0x6500 0x7300 0x8000 0x00 0x24 0x24 0x27 0x30 0x33 0x6880 0x7400 0x8000 0x00 0x25 0x20 0x23 0x30 0x33 0x6b00 0x7200 0x8000 0x00 0x26 0x1c 0x1f 0x30 0x33 0x6e00 0x6f00 0x8000 0x00 0x27 0x18 0x1b 0x30 0x33 0x7300 0x7080 0x8000 0x00 0x28 0x14 0x17 0x30 0x33 0x7700 0x6d80 0x8000 0x00 0x29 0x10 0x13 0x30 0x33 0x7c00 0x6d80 0x8000 0x00 0x2a 0x0c 0x0f 0x30 0x33 0x8000 0x6c00 0x7e00 0x00 0x2b 0x08 0x0b 0x30 0x33 0x8000 0x6700 0x7a00 0x00 0x2c 0x04 0x07 0x30 0x33 0x8000 0x6100 0x7200 0x00 0x2d 0x00 0x03 0x30 0x33 0x8000 0x5b00 0x6c00 0x00 0x2e 0x38 0x3b 0x2c 0x2f 0x5c00 0x7880 0x8000 0x00 0x2f 0x34 0x37 0x2c 0x2f 0x5f00 0x7700 0x8000 0x00 0x30 0x30 0x33 0x2c 0x2f 0x6100 0x7700 0x8000 0x00 0x31 0x2c 0x2f 0x2c 0x2f 0x6500 0x7680 0x8000 0x00 0x32 0x28 0x2b 0x2c 0x2f 0x6700 0x7600 0x8000 0x00 0x33 0x24 0x27 0x2c 0x2f 0x6a00 0x7500 0x8000 0x00 0x34 0x20 0x23 0x2c 0x2f 0x6e00 0x7500 0x8000 0x00 0x35 0x1c 0x1f 0x2c 0x2f 0x7180 0x7400 0x8000 0x00 0x36 0x18 0x1b 0x2c 0x2f 0x7580 0x7300 0x8000 0x00 0x37 0x14 0x17 0x2c 0x2f 0x7b00 0x7080 0x8000 0x00 0x38 0x10 0x13 0x2c 0x2f 0x8000 0x7080 0x7f00 0x00 0x39 0x0c 0x0f 0x2c 0x2f 0x8000 0x6b00 0x7a00 0x00 0x3a 0x08 0x0b 0x2c 0x2f 0x8000 0x6500 0x7400 0x00 0x3b 0x04 0x07 0x2c 0x2f 0x8000 0x6000 0x6d00 0x00 0x3c 0x00 0x03 0x2c 0x2f 0x8000 0x5a00 0x6800 0x00 0x3d 0x38 0x3b 0x28 0x2b 0x6000 0x7c00 0x8000 0x00 0x3e 0x34 0x37 0x28 0x2b 0x6200 0x7b00 0x8000 0x00 0x3f 0x30 0x33 0x28 0x2b 0x6600 0x7b00 0x8000 0x00 0x40 0x2c 0x2f 0x28 0x2b 0x6900 0x7c00 0x8000 0x00 0x41 0x28 0x2b 0x28 0x2b 0x6b80 0x7900 0x8000 0x00 0x42 0x24 0x27 0x28 0x2b 0x6e00 0x7900 0x8000 0x00 0x43 0x20 0x23 0x28 0x2b 0x7100 0x7780 0x8000 0x00 0x44 0x1c 0x1f 0x28 0x2b 0x7500 0x7700 0x8000 0x00 0x45 0x18 0x1b 0x28 0x2b 0x7a00 0x7600 0x8000 0x00 0x46 0x14 0x17 0x28 0x2b 0x8000 0x7500 0x8000 0x00 0x47 0x10 0x13 0x28 0x2b 0x8000 0x7000 0x7c00 0x00 0x48 0x0c 0x0f 0x28 0x2b 0x8000 0x6b00 0x7800 0x00 0x49 0x08 0x0b 0x28 0x2b 0x8000 0x6600 0x7200 0x00 0x4a 0x04 0x07 0x28 0x2b 0x8000 0x6000 0x6c00 0x00 0x4b 0x00 0x03 0x28 0x2b 0x8000 0x5900 0x6500 0x00 0x4c 0x38 0x3b 0x24 0x27 0x6200 0x8000 0x8000 0x00 0x4d 0x34 0x37 0x24 0x27 0x6500 0x7f00 0x8000 0x00 0x4e 0x30 0x33 0x24 0x27 0x6800 0x7f00 0x8000 0x00 0x4f 0x2c 0x2f 0x24 0x27 0x6b00 0x7e00 0x8000 0x00 0x50 0x28 0x2b 0x24 0x27 0x6e00 0x7c80 0x8000 0x00 0x51 0x24 0x27 0x24 0x27 0x7200 0x7d00 0x8000 0x00 0x52 0x20 0x23 0x24 0x27 0x7500 0x7a00 0x8000 0x00 0x53 0x1c 0x1f 0x24 0x27 0x7900 0x7a00 0x8000 0x00 0x54 0x18 0x1b 0x24 0x27 0x7e00 0x7a00 0x8000 0x00 0x55 0x14 0x17 0x24 0x27 0x8000 0x7300 0x7c00 0x00 0x56 0x10 0x13 0x24 0x27 0x8000 0x6e00 0x7800 0x00 0x57 0x0c 0x0f 0x24 0x27 0x8000 0x6900 0x7300 0x00 0x58 0x08 0x0b 0x24 0x27 0x8000 0x6400 0x6d00 0x00 0x59 0x04 0x07 0x24 0x27 0x8000 0x5e00 0x6800 0x00 0x5a 0x00 0x03 0x24 0x27 0x8000 0x5900 0x6300 0x00 0x5b 0x38 0x3b 0x20 0x23 0x6200 0x8000 0x7d00 0x00 0x5c 0x34 0x37 0x20 0x23 0x6600 0x8000 0x7e00 0x00 0x5d 0x30 0x33 0x20 0x23 0x6a00 0x8000 0x7f00 0x00 0x5e 0x2c 0x2f 0x20 0x23 0x6d00 0x8000 0x7f00 0x00 0x5f 0x28 0x2b 0x20 0x23 0x7100 0x8000 0x8000 0x00 0x60 0x24 0x27 0x20 0x23 0x7400 0x7f00 0x8000 0x00 0x61 0x20 0x23 0x20 0x23 0x7700 0x7e80 0x8000 0x00 0x62 0x1c 0x1f 0x20 0x23 0x7b00 0x7d00 0x8000 0x00 0x63 0x18 0x1b 0x20 0x23 0x7f00 0x7c00 0x8000 0x00 0x64 0x14 0x17 0x20 0x23 0x8000 0x7500 0x7b00 0x00 0x65 0x10 0x13 0x20 0x23 0x8000 0x7000 0x7600 0x00 0x66 0x0c 0x0f 0x20 0x23 0x8000 0x6a00 0x7100 0x00 0x67 0x08 0x0b 0x20 0x23 0x8000 0x6400 0x6b00 0x00 0x68 0x04 0x07 0x20 0x23 0x8000 0x5e00 0x6600 0x00 0x69 0x00 0x03 0x20 0x23 0x8000 0x5800 0x6000 0x00 0x6a 0x38 0x3b 0x1c 0x1f 0x6300 0x8000 0x7a00 0x00 0x6b 0x34 0x37 0x1c 0x1f 0x6600 0x8000 0x7b00 0x00 0x6c 0x30 0x33 0x1c 0x1f 0x6a00 0x8000 0x7c00 0x00 0x6d 0x2c 0x2f 0x1c 0x1f 0x6e00 0x8000 0x7d00 0x00 0x6e 0x28 0x2b 0x1c 0x1f 0x7200 0x8000 0x7e00 0x00 0x6f 0x24 0x27 0x1c 0x1f 0x7600 0x8000 0x7e00 0x00 0x70 0x20 0x23 0x1c 0x1f 0x7a00 0x8000 0x7f00 0x00 0x71 0x18 0x1b 0x1c 0x1f 0x8000 0x7c00 0x7c00 0x00 0x72 0x14 0x17 0x1c 0x1f 0x8000 0x7400 0x7780 0x00 0x73 0x10 0x13 0x1c 0x1f 0x8000 0x6f00 0x7300 0x00 0x74 0x0c 0x0f 0x1c 0x1f 0x8000 0x6900 0x6e00 0x00 0x75 0x08 0x0b 0x1c 0x1f 0x8000 0x6300 0x6800 0x00 0x76 0x04 0x07 0x1c 0x1f 0x8000 0x5d00 0x6280 0x00 0x77 0x00 0x03 0x1c 0x1f 0x8000 0x5800 0x5d00 0x00 0x78 0x38 0x3b 0x18 0x1b 0x6300 0x8000 0x7800 0x00 0x79 0x34 0x37 0x18 0x1b 0x6700 0x8000 0x7900 0x00 0x7a 0x30 0x33 0x18 0x1b 0x6a00 0x8000 0x7900 0x00 0x7b 0x2c 0x2f 0x18 0x1b 0x6e00 0x8000 0x7b00 0x00 0x7c 0x28 0x2b 0x18 0x1b 0x7180 0x8000 0x7c00 0x00 0x7d 0x24 0x27 0x18 0x1b 0x7500 0x8000 0x7b00 0x00 0x7e 0x20 0x23 0x18 0x1b 0x7a00 0x8000 0x7c80 0x00 0x7f 0x1c 0x1f 0x18 0x1b 0x8000 0x8000 0x7e00 0x00 0x80 0x18 0x1b 0x18 0x1b 0x8000 0x7a00 0x7900 0x00 0x81 0x14 0x17 0x18 0x1b 0x8000 0x7400 0x7500 0x00 0x82 0x10 0x13 0x18 0x1b 0x8000 0x6e00 0x6f00 0x00 0x83 0x0c 0x0f 0x18 0x1b 0x8000 0x6900 0x6b00 0x00 0x84 0x08 0x0b 0x18 0x1b 0x8000 0x6200 0x6500 0x00 0x85 0x04 0x07 0x18 0x1b 0x8000 0x5d00 0x6000 0x00 0x86 0x00 0x03 0x18 0x1b 0x8000 0x5700 0x5b00 0x00 0x87 0x38 0x3b 0x14 0x17 0x6300 0x8000 0x7580 0x00 0x88 0x34 0x37 0x14 0x17 0x6700 0x8000 0x7680 0x00 0x89 0x30 0x33 0x14 0x17 0x6a00 0x8000 0x7780 0x00 0x8a 0x2c 0x2f 0x14 0x17 0x6d00 0x8000 0x7800 0x00 0x8b 0x28 0x2b 0x14 0x17 0x7100 0x8000 0x7800 0x00 0x8c 0x24 0x27 0x14 0x17 0x7500 0x8000 0x7980 0x00 0x8d 0x20 0x23 0x14 0x17 0x7a00 0x8000 0x7a00 0x00 0x8e 0x1c 0x1f 0x14 0x17 0x7f00 0x8000 0x7a80 0x00 0x8f 0x18 0x1b 0x14 0x17 0x8000 0x7b00 0x7700 0x00 0x90 0x14 0x17 0x14 0x17 0x8000 0x7300 0x7100 0x00 0x91 0x10 0x13 0x14 0x17 0x8000 0x6d00 0x6d00 0x00 0x92 0x0c 0x0f 0x14 0x17 0x8000 0x6800 0x6900 0x00 0x93 0x08 0x0b 0x14 0x17 0x8000 0x6200 0x6300 0x00 0x94 0x04 0x07 0x14 0x17 0x8000 0x5c00 0x5d00 0x00 0x95 0x00 0x03 0x14 0x17 0x8000 0x5600 0x5900 0x00 0x96 0x38 0x3b 0x10 0x13 0x6300 0x8000 0x7300 0x00 0x97 0x34 0x37 0x10 0x13 0x6600 0x8000 0x7400 0x00 0x98 0x30 0x33 0x10 0x13 0x6a00 0x8000 0x7500 0x00 0x99 0x2c 0x2f 0x10 0x13 0x6e00 0x8000 0x7600 0x00 0x9a 0x28 0x2b 0x10 0x13 0x7100 0x8000 0x7600 0x00 0x9b 0x24 0x27 0x10 0x13 0x7500 0x8000 0x7700 0x00 0x9c 0x20 0x23 0x10 0x13 0x7980 0x8000 0x7800 0x00 0x9d 0x1c 0x1f 0x10 0x13 0x7f00 0x8000 0x7800 0x00 0x9e 0x18 0x1b 0x10 0x13 0x8000 0x7b00 0x7500 0x00 0x9f 0x14 0x17 0x10 0x13 0x8000 0x7300 0x6f00 0x00 0xa0 0x10 0x13 0x10 0x13 0x8000 0x6d00 0x6b00 0x00 0xa1 0x0c 0x0f 0x10 0x13 0x8000 0x6800 0x6600 0x00 0xa2 0x08 0x0b 0x10 0x13 0x8000 0x6200 0x6000 0x00 0xa3 0x04 0x07 0x10 0x13 0x8000 0x5b00 0x5b00 0x00 0xa4 0x00 0x03 0x10 0x13 0x8000 0x5600 0x5700 0x00 0xa5 0x38 0x3b 0x0c 0x0f 0x6200 0x8000 0x7000 0x00 0xa6 0x34 0x37 0x0c 0x0f 0x6700 0x8000 0x7100 0x00 0xa7 0x30 0x33 0x0c 0x0f 0x6a00 0x8000 0x7200 0x00 0xa8 0x2c 0x2f 0x0c 0x0f 0x6d00 0x8000 0x7300 0x00 0xa9 0x28 0x2b 0x0c 0x0f 0x7100 0x8000 0x7400 0x00 0xaa 0x24 0x27 0x0c 0x0f 0x7500 0x8000 0x7480 0x00 0xab 0x20 0x23 0x0c 0x0f 0x7900 0x8000 0x7500 0x00 0xac 0x1c 0x1f 0x0c 0x0f 0x7f00 0x8000 0x7600 0x00 0xad 0x18 0x1b 0x0c 0x0f 0x8000 0x7b00 0x7200 0x00 0xae 0x14 0x17 0x0c 0x0f 0x8000 0x7300 0x6d00 0x00 0xaf 0x10 0x13 0x0c 0x0f 0x8000 0x6d00 0x6800 0x00 0xb0 0x0c 0x0f 0x0c 0x0f 0x8000 0x6800 0x6400 0x00 0xb1 0x08 0x0b 0x0c 0x0f 0x8000 0x6100 0x5d00 0x00 0xb2 0x04 0x07 0x0c 0x0f 0x8000 0x5b00 0x5900 0x00 0xb3 0x00 0x03 0x0c 0x0f 0x8000 0x5600 0x5480 0x00 0xb4 0x38 0x3b 0x08 0x0b 0x6200 0x8000 0x6e00 0x00 0xb5 0x34 0x37 0x08 0x0b 0x6600 0x8000 0x6e00 0x00 0xb6 0x30 0x33 0x08 0x0b 0x6900 0x8000 0x6f00 0x00 0xb7 0x2c 0x2f 0x08 0x0b 0x6d00 0x8000 0x7000 0x00 0xb8 0x28 0x2b 0x08 0x0b 0x7100 0x8000 0x7200 0x00 0xb9 0x24 0x27 0x08 0x0b 0x7500 0x8000 0x7200 0x00 0xba 0x20 0x23 0x08 0x0b 0x7a00 0x8000 0x7200 0x00 0xbb 0x1c 0x1f 0x08 0x0b 0x7f00 0x8000 0x7300 0x00 0xbc 0x18 0x1b 0x08 0x0b 0x8000 0x7b00 0x7000 0x00 0xbd 0x14 0x17 0x08 0x0b 0x8000 0x7200 0x6a00 0x00 0xbe 0x10 0x13 0x08 0x0b 0x8000 0x6c00 0x6500 0x00 0xbf 0x0c 0x0f 0x08 0x0b 0x8000 0x6600 0x6000 0x00 0xc0 0x08 0x0b 0x08 0x0b 0x8000 0x6000 0x5b00 0x00 0xc1 0x04 0x07 0x08 0x0b 0x8000 0x5b00 0x5700 0x00 0xc2 0x00 0x03 0x08 0x0b 0x8000 0x5500 0x5100 0x00 0xc3 0x38 0x3b 0x04 0x07 0x6200 0x8000 0x6b00 0x00 0xc4 0x34 0x37 0x04 0x07 0x6500 0x8000 0x6c00 0x00 0xc5 0x30 0x33 0x04 0x07 0x6800 0x8000 0x6d80 0x00 0xc6 0x2c 0x2f 0x04 0x07 0x6c00 0x8000 0x6e00 0x00 0xc7 0x28 0x2b 0x04 0x07 0x7000 0x8000 0x6e00 0x00 0xc8 0x24 0x27 0x04 0x07 0x7400 0x8000 0x6f00 0x00 0xc9 0x20 0x23 0x04 0x07 0x7800 0x8000 0x7000 0x00 0xca 0x1c 0x1f 0x04 0x07 0x7e00 0x8000 0x7000 0x00 0xcb 0x18 0x1b 0x04 0x07 0x8000 0x7a80 0x6b80 0x00 0xcc 0x14 0x17 0x04 0x07 0x8000 0x7400 0x6780 0x00 0xcd 0x10 0x13 0x04 0x07 0x8000 0x6e00 0x6380 0x00 0xce 0x0c 0x0f 0x04 0x07 0x8000 0x6700 0x5e00 0x00 0xcf 0x08 0x0b 0x04 0x07 0x8000 0x6180 0x5980 0x00 0xd0 0x04 0x07 0x04 0x07 0x8000 0x5b00 0x5500 0x00 0xd1 0x00 0x03 0x04 0x07 0x8000 0x5500 0x5100 0x00 0xd2 0x38 0x3b 0x00 0x03 0x6100 0x8000 0x6900 0x00 0xd3 0x34 0x37 0x00 0x03 0x6400 0x8000 0x6a00 0x00 0xd4 0x30 0x33 0x00 0x03 0x6800 0x8000 0x6b00 0x00 0xd5 0x2c 0x2f 0x00 0x03 0x6c00 0x8000 0x6b80 0x00 0xd6 0x28 0x2b 0x00 0x03 0x6f00 0x8000 0x6c00 0x00 0xd7 0x24 0x27 0x00 0x03 0x7300 0x8000 0x6d00 0x00 0xd8 0x20 0x23 0x00 0x03 0x7900 0x8000 0x6d00 0x00 0xd9 0x1c 0x1f 0x00 0x03 0x7f00 0x8000 0x6e00 0x00 0xda 0x18 0x1b 0x00 0x03 0x8000 0x7b00 0x6a80 0x00 0xdb 0x14 0x17 0x00 0x03 0x8000 0x7400 0x6580 0x00 0xdc 0x10 0x13 0x00 0x03 0x8000 0x6d00 0x6180 0x00 0xdd 0x0c 0x0f 0x00 0x03 0x8000 0x6900 0x5e00 0x00 0xde 0x08 0x0b 0x00 0x03 0x8000 0x6200 0x5800 0x00 0xdf 0x04 0x07 0x00 0x03 0x8000 0x5a00 0x5200 0x00 0xe0 0x00 0x03 0x00 0x03 0x8000 0x5400 0x4d00 0xff 0x00 0x00 0x3b 0x00 0x3b 0x8000 0x8000 0x8000>;
			};

			somc,novatek_sharp_1080p_cmd_panel {
				qcom,mdss-dsi-panel-name = "sharp novatek 1080p cmd";
				qcom,mdss-dsi-panel-controller = <0x23>;
				qcom,mdss-dsi-panel-type = "dsi_cmd_mode";
				qcom,mdss-dsi-panel-destination = "display_1";
				qcom,mdss-dsi-panel-framerate = <0x3c>;
				qcom,mdss-dsi-virtual-channel-id = <0x00>;
				qcom,mdss-dsi-stream = <0x00>;
				qcom,mdss-dsi-panel-width = <0x438>;
				qcom,mdss-dsi-panel-height = <0x780>;
				qcom,mdss-dsi-h-front-porch = <0x38>;
				qcom,mdss-dsi-h-back-porch = <0x08>;
				qcom,mdss-dsi-h-pulse-width = <0x08>;
				qcom,mdss-dsi-h-sync-skew = <0x00>;
				qcom,mdss-dsi-v-back-porch = <0x08>;
				qcom,mdss-dsi-v-front-porch = <0xe9>;
				qcom,mdss-dsi-v-pulse-width = <0x02>;
				qcom,mdss-dsi-h-left-border = <0x00>;
				qcom,mdss-dsi-h-right-border = <0x00>;
				qcom,mdss-dsi-v-top-border = <0x00>;
				qcom,mdss-dsi-v-bottom-border = <0x00>;
				qcom,mdss-dsi-bpp = <0x18>;
				qcom,mdss-dsi-underflow-color = <0x00>;
				qcom,mdss-dsi-border-color = <0x00>;
				somc,mdss-dsi-init-command = [15 01 00 00 00 00 02 bb 10 15 01 00 00 00 00 02 ff 24 15 01 00 00 00 00 02 fb 01 15 01 00 00 00 00 02 c4 9a 15 01 00 00 00 00 02 85 05 15 01 00 00 00 00 02 93 02 15 01 00 00 00 00 02 94 08 15 01 00 00 00 00 02 92 95 15 01 00 00 00 00 02 ff 10 15 01 00 00 00 00 02 ff 20 15 01 00 00 00 00 02 fb 01 15 01 00 00 00 00 02 58 82 15 01 00 00 00 00 02 59 02 15 01 00 00 00 00 02 5a 02 15 01 00 00 00 00 02 5b 02 15 01 00 00 00 00 02 5c 83 15 01 00 00 00 00 02 5d 83 15 01 00 00 00 00 02 5e 03 15 01 00 00 00 00 02 5f 03 15 01 00 00 00 00 02 6d 55 15 01 00 00 00 00 02 ff 10 15 01 00 00 00 00 02 ff 24 15 01 00 00 00 00 02 fb 01 15 01 00 00 00 00 02 c4 02 15 01 00 00 00 00 02 ff 10 15 01 00 00 00 00 02 35 00 39 01 00 00 00 00 03 44 03 00 15 01 00 00 00 00 02 ff e0 15 01 00 00 00 00 02 fb 01 15 01 00 00 00 00 02 b5 86 15 01 00 00 00 00 02 b6 77 15 01 00 00 00 00 02 b8 ad 15 01 00 00 00 00 02 ff 20 15 01 00 00 00 00 02 fb 01 15 01 00 00 00 00 02 10 04 15 01 00 00 00 00 02 ff 10 05 01 00 00 1e 00 01 11];
				qcom,mdss-dsi-on-command = <0x5010000 0x28000129>;
				qcom,mdss-dsi-off-command = [15 01 00 00 00 00 02 ff 10 05 01 00 00 14 00 01 28 05 01 00 00 50 00 01 10];
				qcom,mdss-dsi-on-command-state = "dsi_hs_mode";
				qcom,mdss-dsi-off-command-state = "dsi_hs_mode";
				qcom,mdss-dsi-h-sync-pulse = <0x01>;
				qcom,mdss-dsi-traffic-mode = "non_burst_sync_event";
				qcom,mdss-dsi-bllp-eof-power-mode;
				qcom,mdss-dsi-bllp-power-mode;
				qcom,mdss-dsi-lane-0-state;
				qcom,mdss-dsi-lane-1-state;
				qcom,mdss-dsi-lane-2-state;
				qcom,mdss-dsi-lane-3-state;
				qcom,mdss-dsi-te-pin-select = <0x01>;
				qcom,mdss-dsi-wr-mem-start = <0x2c>;
				qcom,mdss-dsi-wr-mem-continue = <0x3c>;
				qcom,mdss-dsi-te-dcs-command = <0x01>;
				qcom,mdss-dsi-te-check-enable;
				qcom,mdss-dsi-te-using-te-pin;
				qcom,mdss-dsi-panel-timings = <0xe6382600 0x686e2a3c 0x2c030400>;
				qcom,mdss-dsi-lp11-init;
				qcom,mdss-dsi-t-clk-post = <0x21>;
				qcom,mdss-dsi-t-clk-pre = <0x2b>;
				qcom,mdss-dsi-bl-min-level = <0x01>;
				qcom,mdss-dsi-bl-max-level = <0xfff>;
				qcom,mdss-brightness-max-level = <0xfff>;
				qcom,mdss-dsi-dma-trigger = "trigger_sw";
				qcom,mdss-dsi-mdp-trigger = "none";
				qcom,mdss-dsi-bl-pmic-control-type = "bl_ctrl_wled";
				qcom,mdss-dsi-pan-enable-dynamic-fps;
				qcom,mdss-dsi-pan-fps-update = "dfps_suspend_resume_mode";
				qcom,cont-splash-enabled;
				qcom,mdss-dsi-tx-eot-append;
				somc,driver-ic = <0x00>;
				somc,dric-gpio = <0x05 0x1a 0x00>;
				somc,touch-reset-gpio = <0x05 0x55 0x00>;
				somc,mul-channel-scaling = <0x03>;
				somc,mdss-phy-size-mm = <0x40 0x72>;
				somc,mdss-dsi-lane-config = [00 c2 ef 00 00 00 00 01 ff 00 c2 ef 00 00 00 00 01 ff 00 c2 ef 00 00 00 00 01 ff 00 c2 ef 00 00 00 00 01 ff 00 02 45 00 00 00 00 01 97];
				somc,mdss-dsi-disp-on-in-hs = <0x00>;
				somc,mdss-dsi-wait-time-before-on-cmd = <0x96>;
				somc,lcd-id = <0x01>;
				somc,lcd-id-adc = <0x00 0xdea8>;
				somc,disp-en-on-pre = <0x0a>;
				somc,disp-en-on-post = <0x14>;
				somc,pw-on-rst-seq = <0x01 0x01 0x00 0x01 0x01 0x14>;
				somc,disp-en-off-post = <0xc8>;
				somc,pw-off-rst-seq = <0x00 0x05>;
				somc,pw-down-period = <0x64>;
				somc,mdss-dsi-pre-uv-command = [23 01 00 00 00 00 02 b0 04];
				somc,mdss-dsi-uv-command = <0x6010000 0x1da 0x6010000 0x1db>;
				somc,mdss-dsi-uv-param-type = <0x04>;
				somc,mdss-dsi-pcc-table-size = <0xe1>;
				somc,mdss-dsi-pcc-table = <0x00 0x01 0x38 0x3b 0x38 0x3b 0x5700 0x7000 0x8000 0x00 0x02 0x34 0x37 0x38 0x3b 0x5900 0x6f00 0x8000 0x00 0x03 0x30 0x33 0x38 0x3b 0x5c00 0x6e00 0x8000 0x00 0x04 0x2c 0x2f 0x38 0x3b 0x5d80 0x6c80 0x8000 0x00 0x05 0x28 0x2b 0x38 0x3b 0x6080 0x6c80 0x8000 0x00 0x06 0x24 0x27 0x38 0x3b 0x6380 0x6c80 0x8000 0x00 0x07 0x20 0x23 0x38 0x3b 0x6700 0x6c00 0x8000 0x00 0x08 0x1c 0x1f 0x38 0x3b 0x6980 0x6b00 0x8000 0x00 0x09 0x18 0x1b 0x38 0x3b 0x6d00 0x6a80 0x8000 0x00 0x0a 0x14 0x17 0x38 0x3b 0x7180 0x6900 0x8000 0x00 0x0b 0x10 0x13 0x38 0x3b 0x7800 0x6800 0x8000 0x00 0x0c 0x0c 0x0f 0x38 0x3b 0x7d00 0x6700 0x8000 0x00 0x0d 0x08 0x0b 0x38 0x3b 0x8000 0x6500 0x7d00 0x00 0x0e 0x04 0x07 0x38 0x3b 0x8000 0x6000 0x7700 0x00 0x0f 0x00 0x03 0x38 0x3b 0x8000 0x5900 0x7000 0x00 0x10 0x38 0x3b 0x34 0x37 0x5900 0x7280 0x8000 0x00 0x11 0x34 0x37 0x34 0x37 0x5b00 0x7100 0x8000 0x00 0x12 0x30 0x33 0x34 0x37 0x5e00 0x7180 0x8000 0x00 0x13 0x2c 0x2f 0x34 0x37 0x6080 0x7180 0x8000 0x00 0x14 0x28 0x2b 0x34 0x37 0x6400 0x7000 0x8000 0x00 0x15 0x24 0x27 0x34 0x37 0x6700 0x7000 0x8000 0x00 0x16 0x20 0x23 0x34 0x37 0x6900 0x6f00 0x8000 0x00 0x17 0x1c 0x1f 0x34 0x37 0x6c00 0x6e80 0x8000 0x00 0x18 0x18 0x1b 0x34 0x37 0x7000 0x6d80 0x8000 0x00 0x19 0x14 0x17 0x34 0x37 0x7580 0x6b80 0x8000 0x00 0x1a 0x10 0x13 0x34 0x37 0x7b00 0x6a80 0x8000 0x00 0x1b 0x0c 0x0f 0x34 0x37 0x8000 0x6a80 0x8000 0x00 0x1c 0x08 0x0b 0x34 0x37 0x8000 0x6600 0x7c00 0x00 0x1d 0x04 0x07 0x34 0x37 0x8000 0x6100 0x7400 0x00 0x1e 0x00 0x03 0x34 0x37 0x8000 0x5b00 0x6e00 0x00 0x1f 0x38 0x3b 0x30 0x33 0x5c80 0x7600 0x8000 0x00 0x20 0x34 0x37 0x30 0x33 0x5e00 0x7500 0x8000 0x00 0x21 0x30 0x33 0x30 0x33 0x6100 0x7480 0x8000 0x00 0x22 0x2c 0x2f 0x30 0x33 0x6400 0x7400 0x8000 0x00 0x23 0x28 0x2b 0x30 0x33 0x6500 0x7300 0x8000 0x00 0x24 0x24 0x27 0x30 0x33 0x6880 0x7400 0x8000 0x00 0x25 0x20 0x23 0x30 0x33 0x6b00 0x7200 0x8000 0x00 0x26 0x1c 0x1f 0x30 0x33 0x6e00 0x6f00 0x8000 0x00 0x27 0x18 0x1b 0x30 0x33 0x7300 0x7080 0x8000 0x00 0x28 0x14 0x17 0x30 0x33 0x7700 0x6d80 0x8000 0x00 0x29 0x10 0x13 0x30 0x33 0x7c00 0x6d80 0x8000 0x00 0x2a 0x0c 0x0f 0x30 0x33 0x8000 0x6c00 0x7e00 0x00 0x2b 0x08 0x0b 0x30 0x33 0x8000 0x6700 0x7a00 0x00 0x2c 0x04 0x07 0x30 0x33 0x8000 0x6100 0x7200 0x00 0x2d 0x00 0x03 0x30 0x33 0x8000 0x5b00 0x6c00 0x00 0x2e 0x38 0x3b 0x2c 0x2f 0x5c00 0x7880 0x8000 0x00 0x2f 0x34 0x37 0x2c 0x2f 0x5f00 0x7700 0x8000 0x00 0x30 0x30 0x33 0x2c 0x2f 0x6100 0x7700 0x8000 0x00 0x31 0x2c 0x2f 0x2c 0x2f 0x6500 0x7680 0x8000 0x00 0x32 0x28 0x2b 0x2c 0x2f 0x6700 0x7600 0x8000 0x00 0x33 0x24 0x27 0x2c 0x2f 0x6a00 0x7500 0x8000 0x00 0x34 0x20 0x23 0x2c 0x2f 0x6e00 0x7500 0x8000 0x00 0x35 0x1c 0x1f 0x2c 0x2f 0x7180 0x7400 0x8000 0x00 0x36 0x18 0x1b 0x2c 0x2f 0x7580 0x7300 0x8000 0x00 0x37 0x14 0x17 0x2c 0x2f 0x7b00 0x7080 0x8000 0x00 0x38 0x10 0x13 0x2c 0x2f 0x8000 0x7080 0x7f00 0x00 0x39 0x0c 0x0f 0x2c 0x2f 0x8000 0x6b00 0x7a00 0x00 0x3a 0x08 0x0b 0x2c 0x2f 0x8000 0x6500 0x7400 0x00 0x3b 0x04 0x07 0x2c 0x2f 0x8000 0x6000 0x6d00 0x00 0x3c 0x00 0x03 0x2c 0x2f 0x8000 0x5a00 0x6800 0x00 0x3d 0x38 0x3b 0x28 0x2b 0x6000 0x7c00 0x8000 0x00 0x3e 0x34 0x37 0x28 0x2b 0x6200 0x7b00 0x8000 0x00 0x3f 0x30 0x33 0x28 0x2b 0x6600 0x7b00 0x8000 0x00 0x40 0x2c 0x2f 0x28 0x2b 0x6900 0x7c00 0x8000 0x00 0x41 0x28 0x2b 0x28 0x2b 0x6b80 0x7900 0x8000 0x00 0x42 0x24 0x27 0x28 0x2b 0x6e00 0x7900 0x8000 0x00 0x43 0x20 0x23 0x28 0x2b 0x7100 0x7780 0x8000 0x00 0x44 0x1c 0x1f 0x28 0x2b 0x7500 0x7700 0x8000 0x00 0x45 0x18 0x1b 0x28 0x2b 0x7a00 0x7600 0x8000 0x00 0x46 0x14 0x17 0x28 0x2b 0x8000 0x7500 0x8000 0x00 0x47 0x10 0x13 0x28 0x2b 0x8000 0x7000 0x7c00 0x00 0x48 0x0c 0x0f 0x28 0x2b 0x8000 0x6b00 0x7800 0x00 0x49 0x08 0x0b 0x28 0x2b 0x8000 0x6600 0x7200 0x00 0x4a 0x04 0x07 0x28 0x2b 0x8000 0x6000 0x6c00 0x00 0x4b 0x00 0x03 0x28 0x2b 0x8000 0x5900 0x6500 0x00 0x4c 0x38 0x3b 0x24 0x27 0x6200 0x8000 0x8000 0x00 0x4d 0x34 0x37 0x24 0x27 0x6500 0x7f00 0x8000 0x00 0x4e 0x30 0x33 0x24 0x27 0x6800 0x7f00 0x8000 0x00 0x4f 0x2c 0x2f 0x24 0x27 0x6b00 0x7e00 0x8000 0x00 0x50 0x28 0x2b 0x24 0x27 0x6e00 0x7c80 0x8000 0x00 0x51 0x24 0x27 0x24 0x27 0x7200 0x7d00 0x8000 0x00 0x52 0x20 0x23 0x24 0x27 0x7500 0x7a00 0x8000 0x00 0x53 0x1c 0x1f 0x24 0x27 0x7900 0x7a00 0x8000 0x00 0x54 0x18 0x1b 0x24 0x27 0x7e00 0x7a00 0x8000 0x00 0x55 0x14 0x17 0x24 0x27 0x8000 0x7300 0x7c00 0x00 0x56 0x10 0x13 0x24 0x27 0x8000 0x6e00 0x7800 0x00 0x57 0x0c 0x0f 0x24 0x27 0x8000 0x6900 0x7300 0x00 0x58 0x08 0x0b 0x24 0x27 0x8000 0x6400 0x6d00 0x00 0x59 0x04 0x07 0x24 0x27 0x8000 0x5e00 0x6800 0x00 0x5a 0x00 0x03 0x24 0x27 0x8000 0x5900 0x6300 0x00 0x5b 0x38 0x3b 0x20 0x23 0x6200 0x8000 0x7d00 0x00 0x5c 0x34 0x37 0x20 0x23 0x6600 0x8000 0x7e00 0x00 0x5d 0x30 0x33 0x20 0x23 0x6a00 0x8000 0x7f00 0x00 0x5e 0x2c 0x2f 0x20 0x23 0x6d00 0x8000 0x7f00 0x00 0x5f 0x28 0x2b 0x20 0x23 0x7100 0x8000 0x8000 0x00 0x60 0x24 0x27 0x20 0x23 0x7400 0x7f00 0x8000 0x00 0x61 0x20 0x23 0x20 0x23 0x7700 0x7e80 0x8000 0x00 0x62 0x1c 0x1f 0x20 0x23 0x7b00 0x7d00 0x8000 0x00 0x63 0x18 0x1b 0x20 0x23 0x7f00 0x7c00 0x8000 0x00 0x64 0x14 0x17 0x20 0x23 0x8000 0x7500 0x7b00 0x00 0x65 0x10 0x13 0x20 0x23 0x8000 0x7000 0x7600 0x00 0x66 0x0c 0x0f 0x20 0x23 0x8000 0x6a00 0x7100 0x00 0x67 0x08 0x0b 0x20 0x23 0x8000 0x6400 0x6b00 0x00 0x68 0x04 0x07 0x20 0x23 0x8000 0x5e00 0x6600 0x00 0x69 0x00 0x03 0x20 0x23 0x8000 0x5800 0x6000 0x00 0x6a 0x38 0x3b 0x1c 0x1f 0x6300 0x8000 0x7a00 0x00 0x6b 0x34 0x37 0x1c 0x1f 0x6600 0x8000 0x7b00 0x00 0x6c 0x30 0x33 0x1c 0x1f 0x6a00 0x8000 0x7c00 0x00 0x6d 0x2c 0x2f 0x1c 0x1f 0x6e00 0x8000 0x7d00 0x00 0x6e 0x28 0x2b 0x1c 0x1f 0x7200 0x8000 0x7e00 0x00 0x6f 0x24 0x27 0x1c 0x1f 0x7600 0x8000 0x7e00 0x00 0x70 0x20 0x23 0x1c 0x1f 0x7a00 0x8000 0x7f00 0x00 0x71 0x18 0x1b 0x1c 0x1f 0x8000 0x7c00 0x7c00 0x00 0x72 0x14 0x17 0x1c 0x1f 0x8000 0x7400 0x7780 0x00 0x73 0x10 0x13 0x1c 0x1f 0x8000 0x6f00 0x7300 0x00 0x74 0x0c 0x0f 0x1c 0x1f 0x8000 0x6900 0x6e00 0x00 0x75 0x08 0x0b 0x1c 0x1f 0x8000 0x6300 0x6800 0x00 0x76 0x04 0x07 0x1c 0x1f 0x8000 0x5d00 0x6280 0x00 0x77 0x00 0x03 0x1c 0x1f 0x8000 0x5800 0x5d00 0x00 0x78 0x38 0x3b 0x18 0x1b 0x6300 0x8000 0x7800 0x00 0x79 0x34 0x37 0x18 0x1b 0x6700 0x8000 0x7900 0x00 0x7a 0x30 0x33 0x18 0x1b 0x6a00 0x8000 0x7900 0x00 0x7b 0x2c 0x2f 0x18 0x1b 0x6e00 0x8000 0x7b00 0x00 0x7c 0x28 0x2b 0x18 0x1b 0x7180 0x8000 0x7c00 0x00 0x7d 0x24 0x27 0x18 0x1b 0x7500 0x8000 0x7b00 0x00 0x7e 0x20 0x23 0x18 0x1b 0x7a00 0x8000 0x7c80 0x00 0x7f 0x1c 0x1f 0x18 0x1b 0x8000 0x8000 0x7e00 0x00 0x80 0x18 0x1b 0x18 0x1b 0x8000 0x7a00 0x7900 0x00 0x81 0x14 0x17 0x18 0x1b 0x8000 0x7400 0x7500 0x00 0x82 0x10 0x13 0x18 0x1b 0x8000 0x6e00 0x6f00 0x00 0x83 0x0c 0x0f 0x18 0x1b 0x8000 0x6900 0x6b00 0x00 0x84 0x08 0x0b 0x18 0x1b 0x8000 0x6200 0x6500 0x00 0x85 0x04 0x07 0x18 0x1b 0x8000 0x5d00 0x6000 0x00 0x86 0x00 0x03 0x18 0x1b 0x8000 0x5700 0x5b00 0x00 0x87 0x38 0x3b 0x14 0x17 0x6300 0x8000 0x7580 0x00 0x88 0x34 0x37 0x14 0x17 0x6700 0x8000 0x7680 0x00 0x89 0x30 0x33 0x14 0x17 0x6a00 0x8000 0x7780 0x00 0x8a 0x2c 0x2f 0x14 0x17 0x6d00 0x8000 0x7800 0x00 0x8b 0x28 0x2b 0x14 0x17 0x7100 0x8000 0x7800 0x00 0x8c 0x24 0x27 0x14 0x17 0x7500 0x8000 0x7980 0x00 0x8d 0x20 0x23 0x14 0x17 0x7a00 0x8000 0x7a00 0x00 0x8e 0x1c 0x1f 0x14 0x17 0x7f00 0x8000 0x7a80 0x00 0x8f 0x18 0x1b 0x14 0x17 0x8000 0x7b00 0x7700 0x00 0x90 0x14 0x17 0x14 0x17 0x8000 0x7300 0x7100 0x00 0x91 0x10 0x13 0x14 0x17 0x8000 0x6d00 0x6d00 0x00 0x92 0x0c 0x0f 0x14 0x17 0x8000 0x6800 0x6900 0x00 0x93 0x08 0x0b 0x14 0x17 0x8000 0x6200 0x6300 0x00 0x94 0x04 0x07 0x14 0x17 0x8000 0x5c00 0x5d00 0x00 0x95 0x00 0x03 0x14 0x17 0x8000 0x5600 0x5900 0x00 0x96 0x38 0x3b 0x10 0x13 0x6300 0x8000 0x7300 0x00 0x97 0x34 0x37 0x10 0x13 0x6600 0x8000 0x7400 0x00 0x98 0x30 0x33 0x10 0x13 0x6a00 0x8000 0x7500 0x00 0x99 0x2c 0x2f 0x10 0x13 0x6e00 0x8000 0x7600 0x00 0x9a 0x28 0x2b 0x10 0x13 0x7100 0x8000 0x7600 0x00 0x9b 0x24 0x27 0x10 0x13 0x7500 0x8000 0x7700 0x00 0x9c 0x20 0x23 0x10 0x13 0x7980 0x8000 0x7800 0x00 0x9d 0x1c 0x1f 0x10 0x13 0x7f00 0x8000 0x7800 0x00 0x9e 0x18 0x1b 0x10 0x13 0x8000 0x7b00 0x7500 0x00 0x9f 0x14 0x17 0x10 0x13 0x8000 0x7300 0x6f00 0x00 0xa0 0x10 0x13 0x10 0x13 0x8000 0x6d00 0x6b00 0x00 0xa1 0x0c 0x0f 0x10 0x13 0x8000 0x6800 0x6600 0x00 0xa2 0x08 0x0b 0x10 0x13 0x8000 0x6200 0x6000 0x00 0xa3 0x04 0x07 0x10 0x13 0x8000 0x5b00 0x5b00 0x00 0xa4 0x00 0x03 0x10 0x13 0x8000 0x5600 0x5700 0x00 0xa5 0x38 0x3b 0x0c 0x0f 0x6200 0x8000 0x7000 0x00 0xa6 0x34 0x37 0x0c 0x0f 0x6700 0x8000 0x7100 0x00 0xa7 0x30 0x33 0x0c 0x0f 0x6a00 0x8000 0x7200 0x00 0xa8 0x2c 0x2f 0x0c 0x0f 0x6d00 0x8000 0x7300 0x00 0xa9 0x28 0x2b 0x0c 0x0f 0x7100 0x8000 0x7400 0x00 0xaa 0x24 0x27 0x0c 0x0f 0x7500 0x8000 0x7480 0x00 0xab 0x20 0x23 0x0c 0x0f 0x7900 0x8000 0x7500 0x00 0xac 0x1c 0x1f 0x0c 0x0f 0x7f00 0x8000 0x7600 0x00 0xad 0x18 0x1b 0x0c 0x0f 0x8000 0x7b00 0x7200 0x00 0xae 0x14 0x17 0x0c 0x0f 0x8000 0x7300 0x6d00 0x00 0xaf 0x10 0x13 0x0c 0x0f 0x8000 0x6d00 0x6800 0x00 0xb0 0x0c 0x0f 0x0c 0x0f 0x8000 0x6800 0x6400 0x00 0xb1 0x08 0x0b 0x0c 0x0f 0x8000 0x6100 0x5d00 0x00 0xb2 0x04 0x07 0x0c 0x0f 0x8000 0x5b00 0x5900 0x00 0xb3 0x00 0x03 0x0c 0x0f 0x8000 0x5600 0x5480 0x00 0xb4 0x38 0x3b 0x08 0x0b 0x6200 0x8000 0x6e00 0x00 0xb5 0x34 0x37 0x08 0x0b 0x6600 0x8000 0x6e00 0x00 0xb6 0x30 0x33 0x08 0x0b 0x6900 0x8000 0x6f00 0x00 0xb7 0x2c 0x2f 0x08 0x0b 0x6d00 0x8000 0x7000 0x00 0xb8 0x28 0x2b 0x08 0x0b 0x7100 0x8000 0x7200 0x00 0xb9 0x24 0x27 0x08 0x0b 0x7500 0x8000 0x7200 0x00 0xba 0x20 0x23 0x08 0x0b 0x7a00 0x8000 0x7200 0x00 0xbb 0x1c 0x1f 0x08 0x0b 0x7f00 0x8000 0x7300 0x00 0xbc 0x18 0x1b 0x08 0x0b 0x8000 0x7b00 0x7000 0x00 0xbd 0x14 0x17 0x08 0x0b 0x8000 0x7200 0x6a00 0x00 0xbe 0x10 0x13 0x08 0x0b 0x8000 0x6c00 0x6500 0x00 0xbf 0x0c 0x0f 0x08 0x0b 0x8000 0x6600 0x6000 0x00 0xc0 0x08 0x0b 0x08 0x0b 0x8000 0x6000 0x5b00 0x00 0xc1 0x04 0x07 0x08 0x0b 0x8000 0x5b00 0x5700 0x00 0xc2 0x00 0x03 0x08 0x0b 0x8000 0x5500 0x5100 0x00 0xc3 0x38 0x3b 0x04 0x07 0x6200 0x8000 0x6b00 0x00 0xc4 0x34 0x37 0x04 0x07 0x6500 0x8000 0x6c00 0x00 0xc5 0x30 0x33 0x04 0x07 0x6800 0x8000 0x6d80 0x00 0xc6 0x2c 0x2f 0x04 0x07 0x6c00 0x8000 0x6e00 0x00 0xc7 0x28 0x2b 0x04 0x07 0x7000 0x8000 0x6e00 0x00 0xc8 0x24 0x27 0x04 0x07 0x7400 0x8000 0x6f00 0x00 0xc9 0x20 0x23 0x04 0x07 0x7800 0x8000 0x7000 0x00 0xca 0x1c 0x1f 0x04 0x07 0x7e00 0x8000 0x7000 0x00 0xcb 0x18 0x1b 0x04 0x07 0x8000 0x7a80 0x6b80 0x00 0xcc 0x14 0x17 0x04 0x07 0x8000 0x7400 0x6780 0x00 0xcd 0x10 0x13 0x04 0x07 0x8000 0x6e00 0x6380 0x00 0xce 0x0c 0x0f 0x04 0x07 0x8000 0x6700 0x5e00 0x00 0xcf 0x08 0x0b 0x04 0x07 0x8000 0x6180 0x5980 0x00 0xd0 0x04 0x07 0x04 0x07 0x8000 0x5b00 0x5500 0x00 0xd1 0x00 0x03 0x04 0x07 0x8000 0x5500 0x5100 0x00 0xd2 0x38 0x3b 0x00 0x03 0x6100 0x8000 0x6900 0x00 0xd3 0x34 0x37 0x00 0x03 0x6400 0x8000 0x6a00 0x00 0xd4 0x30 0x33 0x00 0x03 0x6800 0x8000 0x6b00 0x00 0xd5 0x2c 0x2f 0x00 0x03 0x6c00 0x8000 0x6b80 0x00 0xd6 0x28 0x2b 0x00 0x03 0x6f00 0x8000 0x6c00 0x00 0xd7 0x24 0x27 0x00 0x03 0x7300 0x8000 0x6d00 0x00 0xd8 0x20 0x23 0x00 0x03 0x7900 0x8000 0x6d00 0x00 0xd9 0x1c 0x1f 0x00 0x03 0x7f00 0x8000 0x6e00 0x00 0xda 0x18 0x1b 0x00 0x03 0x8000 0x7b00 0x6a80 0x00 0xdb 0x14 0x17 0x00 0x03 0x8000 0x7400 0x6580 0x00 0xdc 0x10 0x13 0x00 0x03 0x8000 0x6d00 0x6180 0x00 0xdd 0x0c 0x0f 0x00 0x03 0x8000 0x6900 0x5e00 0x00 0xde 0x08 0x0b 0x00 0x03 0x8000 0x6200 0x5800 0x00 0xdf 0x04 0x07 0x00 0x03 0x8000 0x5a00 0x5200 0x00 0xe0 0x00 0x03 0x00 0x03 0x8000 0x5400 0x4d00 0xff 0x00 0x00 0x3b 0x00 0x3b 0x8000 0x8000 0x8000>;
				somc,change-fps-command = [15 01 00 00 00 00 02 ff 24 15 01 00 00 00 00 02 92 95 15 01 00 00 00 00 02 ff 10 39 01 00 00 00 00 03 44 03 00];
				somc,change-fps-default = <0x95>;
				somc,display-clock = <0x1086f50>;
				somc,driver-ic-vbp = <0x08>;
				somc,driver-ic-vfp = <0x02>;
				somc,change-fps-cmds-num = <0x01>;
				somc,change-fps-payload-num = <0x01>;
				somc,change-wait-update = <0x01>;
				somc,change-wait-on = <0x28 0x3c>;
				somc,change-wait-off = <0x50 0x5a>;
				somc,change-wait-cmds-num = <0x00 0x02>;
				somc,fps-threshold = <0xb928>;
				somc,te-c-update = <0x01>;
				somc,te-c-mode-60fps = <0x03 0x00>;
				somc,te-c-mode-45fps = <0x04 0xff>;
				somc,te-c-cmds-num = <0x03>;
				somc,te-c-payload-num = <0x01>;
			};

			somc,novatek_jdi_1080p_video_panel {
				qcom,mdss-dsi-panel-name = "jdi novatek 1080p video";
				qcom,mdss-dsi-panel-controller = <0x23>;
				qcom,mdss-dsi-panel-type = "dsi_video_mode";
				qcom,mdss-dsi-panel-destination = "display_1";
				qcom,mdss-dsi-panel-framerate = <0x3c>;
				qcom,mdss-dsi-virtual-channel-id = <0x00>;
				qcom,mdss-dsi-stream = <0x00>;
				qcom,mdss-dsi-panel-width = <0x438>;
				qcom,mdss-dsi-panel-height = <0x780>;
				qcom,mdss-dsi-h-front-porch = <0x70>;
				qcom,mdss-dsi-h-back-porch = <0x4c>;
				qcom,mdss-dsi-h-pulse-width = <0x04>;
				qcom,mdss-dsi-h-sync-skew = <0x00>;
				qcom,mdss-dsi-v-back-porch = <0x04>;
				qcom,mdss-dsi-v-front-porch = <0x08>;
				qcom,mdss-dsi-v-pulse-width = <0x04>;
				qcom,mdss-dsi-h-left-border = <0x00>;
				qcom,mdss-dsi-h-right-border = <0x00>;
				qcom,mdss-dsi-v-top-border = <0x00>;
				qcom,mdss-dsi-v-bottom-border = <0x00>;
				qcom,mdss-dsi-bpp = <0x18>;
				qcom,mdss-dsi-underflow-color = <0x00>;
				qcom,mdss-dsi-border-color = <0x00>;
				somc,mdss-dsi-init-command = [23 01 00 00 00 00 02 ff 10 05 01 00 00 14 00 01 01 15 01 00 00 00 00 02 bb 03 15 01 00 00 00 00 02 35 00 39 01 00 00 00 00 05 2a 00 00 04 37 39 01 00 00 00 00 05 2b 00 00 07 7f 39 01 00 00 00 00 04 3b 03 08 08];
				qcom,mdss-dsi-on-command = <0x5010000 0x64000111 0x5010000 0x28000129>;
				qcom,mdss-dsi-off-command = <0x5010000 0x14000128 0x5010000 0x50000110>;
				qcom,mdss-dsi-on-command-state = "dsi_lp_mode";
				qcom,mdss-dsi-off-command-state = "dsi_hs_mode";
				qcom,mdss-dsi-h-sync-pulse = <0x01>;
				qcom,mdss-dsi-traffic-mode = "non_burst_sync_event";
				qcom,mdss-dsi-bllp-eof-power-mode;
				qcom,mdss-dsi-bllp-power-mode;
				qcom,mdss-dsi-lane-0-state;
				qcom,mdss-dsi-lane-1-state;
				qcom,mdss-dsi-lane-2-state;
				qcom,mdss-dsi-lane-3-state;
				qcom,mdss-dsi-panel-timings = <0xe6382600 0x686c2a3a 0x2c030400>;
				qcom,mdss-dsi-lp11-init;
				qcom,mdss-dsi-t-clk-post = <0x02>;
				qcom,mdss-dsi-t-clk-pre = <0x2b>;
				qcom,mdss-dsi-bl-min-level = <0x01>;
				qcom,mdss-dsi-bl-max-level = <0xfff>;
				qcom,mdss-brightness-max-level = <0xfff>;
				qcom,mdss-dsi-dma-trigger = "trigger_sw";
				qcom,mdss-dsi-mdp-trigger = "none";
				qcom,mdss-dsi-bl-pmic-control-type = "bl_ctrl_wled";
				qcom,mdss-dsi-pan-enable-dynamic-fps;
				qcom,mdss-dsi-pan-fps-update = "dfps_suspend_resume_mode";
				qcom,cont-splash-enabled;
				qcom,mdss-dsi-tx-eot-append;
				somc,driver-ic = <0x00>;
				somc,dric-gpio = <0x05 0x1a 0x00>;
				somc,touch-reset-gpio = <0x05 0x55 0x00>;
				somc,mul-channel-scaling = <0x03>;
				somc,mdss-phy-size-mm = <0x40 0x72>;
				somc,mdss-dsi-lane-config = [00 c2 ef 00 00 00 00 01 ff 00 c2 ef 00 00 00 00 01 ff 00 c2 ef 00 00 00 00 01 ff 00 c2 ef 00 00 00 00 01 ff 00 02 45 00 00 00 00 01 97];
				somc,mdss-dsi-disp-on-in-hs = <0x01>;
				somc,mdss-dsi-wait-time-before-on-cmd = <0x96>;
				somc,lcd-id = <0x01>;
				somc,lcd-id-adc = <0xc38e8 0xdfe08>;
				somc,disp-en-on-post = <0x0a>;
				somc,pw-on-rst-seq = <0x01 0x0f>;
				somc,disp-en-off-post = <0xc8>;
				somc,pw-off-rst-seq = <0x00 0x00>;
				somc,pw-down-period = <0x64>;
				somc,mdss-dsi-pre-uv-command = [23 01 00 00 00 00 02 b0 04];
				somc,mdss-dsi-uv-command = <0x6010000 0x1da 0x6010000 0x1db>;
				somc,mdss-dsi-uv-param-type = <0x04>;
				somc,mdss-dsi-pcc-table-size = <0xe1>;
				somc,mdss-dsi-pcc-table = <0x00 0x01 0x38 0x3b 0x38 0x3b 0x5700 0x7000 0x8000 0x00 0x02 0x34 0x37 0x38 0x3b 0x5900 0x6f00 0x8000 0x00 0x03 0x30 0x33 0x38 0x3b 0x5c00 0x6e00 0x8000 0x00 0x04 0x2c 0x2f 0x38 0x3b 0x5d80 0x6c80 0x8000 0x00 0x05 0x28 0x2b 0x38 0x3b 0x6080 0x6c80 0x8000 0x00 0x06 0x24 0x27 0x38 0x3b 0x6380 0x6c80 0x8000 0x00 0x07 0x20 0x23 0x38 0x3b 0x6700 0x6c00 0x8000 0x00 0x08 0x1c 0x1f 0x38 0x3b 0x6980 0x6b00 0x8000 0x00 0x09 0x18 0x1b 0x38 0x3b 0x6d00 0x6a80 0x8000 0x00 0x0a 0x14 0x17 0x38 0x3b 0x7180 0x6900 0x8000 0x00 0x0b 0x10 0x13 0x38 0x3b 0x7800 0x6800 0x8000 0x00 0x0c 0x0c 0x0f 0x38 0x3b 0x7d00 0x6700 0x8000 0x00 0x0d 0x08 0x0b 0x38 0x3b 0x8000 0x6500 0x7d00 0x00 0x0e 0x04 0x07 0x38 0x3b 0x8000 0x6000 0x7700 0x00 0x0f 0x00 0x03 0x38 0x3b 0x8000 0x5900 0x7000 0x00 0x10 0x38 0x3b 0x34 0x37 0x5900 0x7280 0x8000 0x00 0x11 0x34 0x37 0x34 0x37 0x5b00 0x7100 0x8000 0x00 0x12 0x30 0x33 0x34 0x37 0x5e00 0x7180 0x8000 0x00 0x13 0x2c 0x2f 0x34 0x37 0x6080 0x7180 0x8000 0x00 0x14 0x28 0x2b 0x34 0x37 0x6400 0x7000 0x8000 0x00 0x15 0x24 0x27 0x34 0x37 0x6700 0x7000 0x8000 0x00 0x16 0x20 0x23 0x34 0x37 0x6900 0x6f00 0x8000 0x00 0x17 0x1c 0x1f 0x34 0x37 0x6c00 0x6e80 0x8000 0x00 0x18 0x18 0x1b 0x34 0x37 0x7000 0x6d80 0x8000 0x00 0x19 0x14 0x17 0x34 0x37 0x7580 0x6b80 0x8000 0x00 0x1a 0x10 0x13 0x34 0x37 0x7b00 0x6a80 0x8000 0x00 0x1b 0x0c 0x0f 0x34 0x37 0x8000 0x6a80 0x8000 0x00 0x1c 0x08 0x0b 0x34 0x37 0x8000 0x6600 0x7c00 0x00 0x1d 0x04 0x07 0x34 0x37 0x8000 0x6100 0x7400 0x00 0x1e 0x00 0x03 0x34 0x37 0x8000 0x5b00 0x6e00 0x00 0x1f 0x38 0x3b 0x30 0x33 0x5c80 0x7600 0x8000 0x00 0x20 0x34 0x37 0x30 0x33 0x5e00 0x7500 0x8000 0x00 0x21 0x30 0x33 0x30 0x33 0x6100 0x7480 0x8000 0x00 0x22 0x2c 0x2f 0x30 0x33 0x6400 0x7400 0x8000 0x00 0x23 0x28 0x2b 0x30 0x33 0x6500 0x7300 0x8000 0x00 0x24 0x24 0x27 0x30 0x33 0x6880 0x7400 0x8000 0x00 0x25 0x20 0x23 0x30 0x33 0x6b00 0x7200 0x8000 0x00 0x26 0x1c 0x1f 0x30 0x33 0x6e00 0x6f00 0x8000 0x00 0x27 0x18 0x1b 0x30 0x33 0x7300 0x7080 0x8000 0x00 0x28 0x14 0x17 0x30 0x33 0x7700 0x6d80 0x8000 0x00 0x29 0x10 0x13 0x30 0x33 0x7c00 0x6d80 0x8000 0x00 0x2a 0x0c 0x0f 0x30 0x33 0x8000 0x6c00 0x7e00 0x00 0x2b 0x08 0x0b 0x30 0x33 0x8000 0x6700 0x7a00 0x00 0x2c 0x04 0x07 0x30 0x33 0x8000 0x6100 0x7200 0x00 0x2d 0x00 0x03 0x30 0x33 0x8000 0x5b00 0x6c00 0x00 0x2e 0x38 0x3b 0x2c 0x2f 0x5c00 0x7880 0x8000 0x00 0x2f 0x34 0x37 0x2c 0x2f 0x5f00 0x7700 0x8000 0x00 0x30 0x30 0x33 0x2c 0x2f 0x6100 0x7700 0x8000 0x00 0x31 0x2c 0x2f 0x2c 0x2f 0x6500 0x7680 0x8000 0x00 0x32 0x28 0x2b 0x2c 0x2f 0x6700 0x7600 0x8000 0x00 0x33 0x24 0x27 0x2c 0x2f 0x6a00 0x7500 0x8000 0x00 0x34 0x20 0x23 0x2c 0x2f 0x6e00 0x7500 0x8000 0x00 0x35 0x1c 0x1f 0x2c 0x2f 0x7180 0x7400 0x8000 0x00 0x36 0x18 0x1b 0x2c 0x2f 0x7580 0x7300 0x8000 0x00 0x37 0x14 0x17 0x2c 0x2f 0x7b00 0x7080 0x8000 0x00 0x38 0x10 0x13 0x2c 0x2f 0x8000 0x7080 0x7f00 0x00 0x39 0x0c 0x0f 0x2c 0x2f 0x8000 0x6b00 0x7a00 0x00 0x3a 0x08 0x0b 0x2c 0x2f 0x8000 0x6500 0x7400 0x00 0x3b 0x04 0x07 0x2c 0x2f 0x8000 0x6000 0x6d00 0x00 0x3c 0x00 0x03 0x2c 0x2f 0x8000 0x5a00 0x6800 0x00 0x3d 0x38 0x3b 0x28 0x2b 0x6000 0x7c00 0x8000 0x00 0x3e 0x34 0x37 0x28 0x2b 0x6200 0x7b00 0x8000 0x00 0x3f 0x30 0x33 0x28 0x2b 0x6600 0x7b00 0x8000 0x00 0x40 0x2c 0x2f 0x28 0x2b 0x6900 0x7c00 0x8000 0x00 0x41 0x28 0x2b 0x28 0x2b 0x6b80 0x7900 0x8000 0x00 0x42 0x24 0x27 0x28 0x2b 0x6e00 0x7900 0x8000 0x00 0x43 0x20 0x23 0x28 0x2b 0x7100 0x7780 0x8000 0x00 0x44 0x1c 0x1f 0x28 0x2b 0x7500 0x7700 0x8000 0x00 0x45 0x18 0x1b 0x28 0x2b 0x7a00 0x7600 0x8000 0x00 0x46 0x14 0x17 0x28 0x2b 0x8000 0x7500 0x8000 0x00 0x47 0x10 0x13 0x28 0x2b 0x8000 0x7000 0x7c00 0x00 0x48 0x0c 0x0f 0x28 0x2b 0x8000 0x6b00 0x7800 0x00 0x49 0x08 0x0b 0x28 0x2b 0x8000 0x6600 0x7200 0x00 0x4a 0x04 0x07 0x28 0x2b 0x8000 0x6000 0x6c00 0x00 0x4b 0x00 0x03 0x28 0x2b 0x8000 0x5900 0x6500 0x00 0x4c 0x38 0x3b 0x24 0x27 0x6200 0x8000 0x8000 0x00 0x4d 0x34 0x37 0x24 0x27 0x6500 0x7f00 0x8000 0x00 0x4e 0x30 0x33 0x24 0x27 0x6800 0x7f00 0x8000 0x00 0x4f 0x2c 0x2f 0x24 0x27 0x6b00 0x7e00 0x8000 0x00 0x50 0x28 0x2b 0x24 0x27 0x6e00 0x7c80 0x8000 0x00 0x51 0x24 0x27 0x24 0x27 0x7200 0x7d00 0x8000 0x00 0x52 0x20 0x23 0x24 0x27 0x7500 0x7a00 0x8000 0x00 0x53 0x1c 0x1f 0x24 0x27 0x7900 0x7a00 0x8000 0x00 0x54 0x18 0x1b 0x24 0x27 0x7e00 0x7a00 0x8000 0x00 0x55 0x14 0x17 0x24 0x27 0x8000 0x7300 0x7c00 0x00 0x56 0x10 0x13 0x24 0x27 0x8000 0x6e00 0x7800 0x00 0x57 0x0c 0x0f 0x24 0x27 0x8000 0x6900 0x7300 0x00 0x58 0x08 0x0b 0x24 0x27 0x8000 0x6400 0x6d00 0x00 0x59 0x04 0x07 0x24 0x27 0x8000 0x5e00 0x6800 0x00 0x5a 0x00 0x03 0x24 0x27 0x8000 0x5900 0x6300 0x00 0x5b 0x38 0x3b 0x20 0x23 0x6200 0x8000 0x7d00 0x00 0x5c 0x34 0x37 0x20 0x23 0x6600 0x8000 0x7e00 0x00 0x5d 0x30 0x33 0x20 0x23 0x6a00 0x8000 0x7f00 0x00 0x5e 0x2c 0x2f 0x20 0x23 0x6d00 0x8000 0x7f00 0x00 0x5f 0x28 0x2b 0x20 0x23 0x7100 0x8000 0x8000 0x00 0x60 0x24 0x27 0x20 0x23 0x7400 0x7f00 0x8000 0x00 0x61 0x20 0x23 0x20 0x23 0x7700 0x7e80 0x8000 0x00 0x62 0x1c 0x1f 0x20 0x23 0x7b00 0x7d00 0x8000 0x00 0x63 0x18 0x1b 0x20 0x23 0x7f00 0x7c00 0x8000 0x00 0x64 0x14 0x17 0x20 0x23 0x8000 0x7500 0x7b00 0x00 0x65 0x10 0x13 0x20 0x23 0x8000 0x7000 0x7600 0x00 0x66 0x0c 0x0f 0x20 0x23 0x8000 0x6a00 0x7100 0x00 0x67 0x08 0x0b 0x20 0x23 0x8000 0x6400 0x6b00 0x00 0x68 0x04 0x07 0x20 0x23 0x8000 0x5e00 0x6600 0x00 0x69 0x00 0x03 0x20 0x23 0x8000 0x5800 0x6000 0x00 0x6a 0x38 0x3b 0x1c 0x1f 0x6300 0x8000 0x7a00 0x00 0x6b 0x34 0x37 0x1c 0x1f 0x6600 0x8000 0x7b00 0x00 0x6c 0x30 0x33 0x1c 0x1f 0x6a00 0x8000 0x7c00 0x00 0x6d 0x2c 0x2f 0x1c 0x1f 0x6e00 0x8000 0x7d00 0x00 0x6e 0x28 0x2b 0x1c 0x1f 0x7200 0x8000 0x7e00 0x00 0x6f 0x24 0x27 0x1c 0x1f 0x7600 0x8000 0x7e00 0x00 0x70 0x20 0x23 0x1c 0x1f 0x7a00 0x8000 0x7f00 0x00 0x71 0x18 0x1b 0x1c 0x1f 0x8000 0x7c00 0x7c00 0x00 0x72 0x14 0x17 0x1c 0x1f 0x8000 0x7400 0x7780 0x00 0x73 0x10 0x13 0x1c 0x1f 0x8000 0x6f00 0x7300 0x00 0x74 0x0c 0x0f 0x1c 0x1f 0x8000 0x6900 0x6e00 0x00 0x75 0x08 0x0b 0x1c 0x1f 0x8000 0x6300 0x6800 0x00 0x76 0x04 0x07 0x1c 0x1f 0x8000 0x5d00 0x6280 0x00 0x77 0x00 0x03 0x1c 0x1f 0x8000 0x5800 0x5d00 0x00 0x78 0x38 0x3b 0x18 0x1b 0x6300 0x8000 0x7800 0x00 0x79 0x34 0x37 0x18 0x1b 0x6700 0x8000 0x7900 0x00 0x7a 0x30 0x33 0x18 0x1b 0x6a00 0x8000 0x7900 0x00 0x7b 0x2c 0x2f 0x18 0x1b 0x6e00 0x8000 0x7b00 0x00 0x7c 0x28 0x2b 0x18 0x1b 0x7180 0x8000 0x7c00 0x00 0x7d 0x24 0x27 0x18 0x1b 0x7500 0x8000 0x7b00 0x00 0x7e 0x20 0x23 0x18 0x1b 0x7a00 0x8000 0x7c80 0x00 0x7f 0x1c 0x1f 0x18 0x1b 0x8000 0x8000 0x7e00 0x00 0x80 0x18 0x1b 0x18 0x1b 0x8000 0x7a00 0x7900 0x00 0x81 0x14 0x17 0x18 0x1b 0x8000 0x7400 0x7500 0x00 0x82 0x10 0x13 0x18 0x1b 0x8000 0x6e00 0x6f00 0x00 0x83 0x0c 0x0f 0x18 0x1b 0x8000 0x6900 0x6b00 0x00 0x84 0x08 0x0b 0x18 0x1b 0x8000 0x6200 0x6500 0x00 0x85 0x04 0x07 0x18 0x1b 0x8000 0x5d00 0x6000 0x00 0x86 0x00 0x03 0x18 0x1b 0x8000 0x5700 0x5b00 0x00 0x87 0x38 0x3b 0x14 0x17 0x6300 0x8000 0x7580 0x00 0x88 0x34 0x37 0x14 0x17 0x6700 0x8000 0x7680 0x00 0x89 0x30 0x33 0x14 0x17 0x6a00 0x8000 0x7780 0x00 0x8a 0x2c 0x2f 0x14 0x17 0x6d00 0x8000 0x7800 0x00 0x8b 0x28 0x2b 0x14 0x17 0x7100 0x8000 0x7800 0x00 0x8c 0x24 0x27 0x14 0x17 0x7500 0x8000 0x7980 0x00 0x8d 0x20 0x23 0x14 0x17 0x7a00 0x8000 0x7a00 0x00 0x8e 0x1c 0x1f 0x14 0x17 0x7f00 0x8000 0x7a80 0x00 0x8f 0x18 0x1b 0x14 0x17 0x8000 0x7b00 0x7700 0x00 0x90 0x14 0x17 0x14 0x17 0x8000 0x7300 0x7100 0x00 0x91 0x10 0x13 0x14 0x17 0x8000 0x6d00 0x6d00 0x00 0x92 0x0c 0x0f 0x14 0x17 0x8000 0x6800 0x6900 0x00 0x93 0x08 0x0b 0x14 0x17 0x8000 0x6200 0x6300 0x00 0x94 0x04 0x07 0x14 0x17 0x8000 0x5c00 0x5d00 0x00 0x95 0x00 0x03 0x14 0x17 0x8000 0x5600 0x5900 0x00 0x96 0x38 0x3b 0x10 0x13 0x6300 0x8000 0x7300 0x00 0x97 0x34 0x37 0x10 0x13 0x6600 0x8000 0x7400 0x00 0x98 0x30 0x33 0x10 0x13 0x6a00 0x8000 0x7500 0x00 0x99 0x2c 0x2f 0x10 0x13 0x6e00 0x8000 0x7600 0x00 0x9a 0x28 0x2b 0x10 0x13 0x7100 0x8000 0x7600 0x00 0x9b 0x24 0x27 0x10 0x13 0x7500 0x8000 0x7700 0x00 0x9c 0x20 0x23 0x10 0x13 0x7980 0x8000 0x7800 0x00 0x9d 0x1c 0x1f 0x10 0x13 0x7f00 0x8000 0x7800 0x00 0x9e 0x18 0x1b 0x10 0x13 0x8000 0x7b00 0x7500 0x00 0x9f 0x14 0x17 0x10 0x13 0x8000 0x7300 0x6f00 0x00 0xa0 0x10 0x13 0x10 0x13 0x8000 0x6d00 0x6b00 0x00 0xa1 0x0c 0x0f 0x10 0x13 0x8000 0x6800 0x6600 0x00 0xa2 0x08 0x0b 0x10 0x13 0x8000 0x6200 0x6000 0x00 0xa3 0x04 0x07 0x10 0x13 0x8000 0x5b00 0x5b00 0x00 0xa4 0x00 0x03 0x10 0x13 0x8000 0x5600 0x5700 0x00 0xa5 0x38 0x3b 0x0c 0x0f 0x6200 0x8000 0x7000 0x00 0xa6 0x34 0x37 0x0c 0x0f 0x6700 0x8000 0x7100 0x00 0xa7 0x30 0x33 0x0c 0x0f 0x6a00 0x8000 0x7200 0x00 0xa8 0x2c 0x2f 0x0c 0x0f 0x6d00 0x8000 0x7300 0x00 0xa9 0x28 0x2b 0x0c 0x0f 0x7100 0x8000 0x7400 0x00 0xaa 0x24 0x27 0x0c 0x0f 0x7500 0x8000 0x7480 0x00 0xab 0x20 0x23 0x0c 0x0f 0x7900 0x8000 0x7500 0x00 0xac 0x1c 0x1f 0x0c 0x0f 0x7f00 0x8000 0x7600 0x00 0xad 0x18 0x1b 0x0c 0x0f 0x8000 0x7b00 0x7200 0x00 0xae 0x14 0x17 0x0c 0x0f 0x8000 0x7300 0x6d00 0x00 0xaf 0x10 0x13 0x0c 0x0f 0x8000 0x6d00 0x6800 0x00 0xb0 0x0c 0x0f 0x0c 0x0f 0x8000 0x6800 0x6400 0x00 0xb1 0x08 0x0b 0x0c 0x0f 0x8000 0x6100 0x5d00 0x00 0xb2 0x04 0x07 0x0c 0x0f 0x8000 0x5b00 0x5900 0x00 0xb3 0x00 0x03 0x0c 0x0f 0x8000 0x5600 0x5480 0x00 0xb4 0x38 0x3b 0x08 0x0b 0x6200 0x8000 0x6e00 0x00 0xb5 0x34 0x37 0x08 0x0b 0x6600 0x8000 0x6e00 0x00 0xb6 0x30 0x33 0x08 0x0b 0x6900 0x8000 0x6f00 0x00 0xb7 0x2c 0x2f 0x08 0x0b 0x6d00 0x8000 0x7000 0x00 0xb8 0x28 0x2b 0x08 0x0b 0x7100 0x8000 0x7200 0x00 0xb9 0x24 0x27 0x08 0x0b 0x7500 0x8000 0x7200 0x00 0xba 0x20 0x23 0x08 0x0b 0x7a00 0x8000 0x7200 0x00 0xbb 0x1c 0x1f 0x08 0x0b 0x7f00 0x8000 0x7300 0x00 0xbc 0x18 0x1b 0x08 0x0b 0x8000 0x7b00 0x7000 0x00 0xbd 0x14 0x17 0x08 0x0b 0x8000 0x7200 0x6a00 0x00 0xbe 0x10 0x13 0x08 0x0b 0x8000 0x6c00 0x6500 0x00 0xbf 0x0c 0x0f 0x08 0x0b 0x8000 0x6600 0x6000 0x00 0xc0 0x08 0x0b 0x08 0x0b 0x8000 0x6000 0x5b00 0x00 0xc1 0x04 0x07 0x08 0x0b 0x8000 0x5b00 0x5700 0x00 0xc2 0x00 0x03 0x08 0x0b 0x8000 0x5500 0x5100 0x00 0xc3 0x38 0x3b 0x04 0x07 0x6200 0x8000 0x6b00 0x00 0xc4 0x34 0x37 0x04 0x07 0x6500 0x8000 0x6c00 0x00 0xc5 0x30 0x33 0x04 0x07 0x6800 0x8000 0x6d80 0x00 0xc6 0x2c 0x2f 0x04 0x07 0x6c00 0x8000 0x6e00 0x00 0xc7 0x28 0x2b 0x04 0x07 0x7000 0x8000 0x6e00 0x00 0xc8 0x24 0x27 0x04 0x07 0x7400 0x8000 0x6f00 0x00 0xc9 0x20 0x23 0x04 0x07 0x7800 0x8000 0x7000 0x00 0xca 0x1c 0x1f 0x04 0x07 0x7e00 0x8000 0x7000 0x00 0xcb 0x18 0x1b 0x04 0x07 0x8000 0x7a80 0x6b80 0x00 0xcc 0x14 0x17 0x04 0x07 0x8000 0x7400 0x6780 0x00 0xcd 0x10 0x13 0x04 0x07 0x8000 0x6e00 0x6380 0x00 0xce 0x0c 0x0f 0x04 0x07 0x8000 0x6700 0x5e00 0x00 0xcf 0x08 0x0b 0x04 0x07 0x8000 0x6180 0x5980 0x00 0xd0 0x04 0x07 0x04 0x07 0x8000 0x5b00 0x5500 0x00 0xd1 0x00 0x03 0x04 0x07 0x8000 0x5500 0x5100 0x00 0xd2 0x38 0x3b 0x00 0x03 0x6100 0x8000 0x6900 0x00 0xd3 0x34 0x37 0x00 0x03 0x6400 0x8000 0x6a00 0x00 0xd4 0x30 0x33 0x00 0x03 0x6800 0x8000 0x6b00 0x00 0xd5 0x2c 0x2f 0x00 0x03 0x6c00 0x8000 0x6b80 0x00 0xd6 0x28 0x2b 0x00 0x03 0x6f00 0x8000 0x6c00 0x00 0xd7 0x24 0x27 0x00 0x03 0x7300 0x8000 0x6d00 0x00 0xd8 0x20 0x23 0x00 0x03 0x7900 0x8000 0x6d00 0x00 0xd9 0x1c 0x1f 0x00 0x03 0x7f00 0x8000 0x6e00 0x00 0xda 0x18 0x1b 0x00 0x03 0x8000 0x7b00 0x6a80 0x00 0xdb 0x14 0x17 0x00 0x03 0x8000 0x7400 0x6580 0x00 0xdc 0x10 0x13 0x00 0x03 0x8000 0x6d00 0x6180 0x00 0xdd 0x0c 0x0f 0x00 0x03 0x8000 0x6900 0x5e00 0x00 0xde 0x08 0x0b 0x00 0x03 0x8000 0x6200 0x5800 0x00 0xdf 0x04 0x07 0x00 0x03 0x8000 0x5a00 0x5200 0x00 0xe0 0x00 0x03 0x00 0x03 0x8000 0x5400 0x4d00 0xff 0x00 0x00 0x3b 0x00 0x3b 0x8000 0x8000 0x8000>;
			};

			somc,novatek_jdi_1080p_cmd_panel {
				qcom,mdss-dsi-panel-name = "jdi novatek 1080p cmd";
				qcom,mdss-dsi-panel-controller = <0x23>;
				qcom,mdss-dsi-panel-type = "dsi_cmd_mode";
				qcom,mdss-dsi-panel-destination = "display_1";
				qcom,mdss-dsi-panel-framerate = <0x3c>;
				qcom,mdss-dsi-virtual-channel-id = <0x00>;
				qcom,mdss-dsi-stream = <0x00>;
				qcom,mdss-dsi-panel-width = <0x438>;
				qcom,mdss-dsi-panel-height = <0x780>;
				qcom,mdss-dsi-h-front-porch = <0x38>;
				qcom,mdss-dsi-h-back-porch = <0x08>;
				qcom,mdss-dsi-h-pulse-width = <0x08>;
				qcom,mdss-dsi-h-sync-skew = <0x00>;
				qcom,mdss-dsi-v-back-porch = <0x08>;
				qcom,mdss-dsi-v-front-porch = <0xe9>;
				qcom,mdss-dsi-v-pulse-width = <0x02>;
				qcom,mdss-dsi-h-left-border = <0x00>;
				qcom,mdss-dsi-h-right-border = <0x00>;
				qcom,mdss-dsi-v-top-border = <0x00>;
				qcom,mdss-dsi-v-bottom-border = <0x00>;
				qcom,mdss-dsi-bpp = <0x18>;
				qcom,mdss-dsi-underflow-color = <0x00>;
				qcom,mdss-dsi-border-color = <0x00>;
				somc,mdss-dsi-init-command = <0x23010000 0x2ff 0x10050100 0x140001 0x1230100 0x02 0xff102301 0x00 0x2fb0115 0x1000000 0x2bb10 0x15010000 0x235 0x150100 0x02 0x44032301 0x00 0x2ffe023 0x1000000 0x2b586 0x23010000 0x2b6 0x77230100 0x02 0xb8ad2301 0x00 0x2fb0123 0x1000000 0x2ff20 0x23010000 0x210 0x4230100 0x02 0xfb012301 0x00 0x2ff2423 0x1000000 0x29295 0x23010000 0x2fb 0x1230100 0x02 0xc4202301 0x00 0x2ff1023 0x1000000 0x2fb01 0x5010000 0x64000111>;
				qcom,mdss-dsi-on-command = <0x5010000 0x129>;
				qcom,mdss-dsi-off-command = [15 01 00 00 00 00 02 ff 10 05 01 00 00 14 00 01 28 05 01 00 00 50 00 01 10];
				qcom,mdss-dsi-on-command-state = "dsi_hs_mode";
				qcom,mdss-dsi-off-command-state = "dsi_hs_mode";
				qcom,mdss-dsi-h-sync-pulse = <0x01>;
				qcom,mdss-dsi-traffic-mode = "non_burst_sync_event";
				qcom,mdss-dsi-bllp-eof-power-mode;
				qcom,mdss-dsi-bllp-power-mode;
				qcom,mdss-dsi-lane-0-state;
				qcom,mdss-dsi-lane-1-state;
				qcom,mdss-dsi-lane-2-state;
				qcom,mdss-dsi-lane-3-state;
				qcom,mdss-dsi-te-pin-select = <0x01>;
				qcom,mdss-dsi-wr-mem-start = <0x2c>;
				qcom,mdss-dsi-wr-mem-continue = <0x3c>;
				qcom,mdss-dsi-te-dcs-command = <0x01>;
				qcom,mdss-dsi-te-check-enable;
				qcom,mdss-dsi-te-using-te-pin;
				qcom,mdss-dsi-panel-timings = <0xe6382600 0x686e2a3c 0x2c030400>;
				qcom,mdss-dsi-lp11-init;
				qcom,mdss-dsi-t-clk-post = <0x21>;
				qcom,mdss-dsi-t-clk-pre = <0x2b>;
				qcom,mdss-dsi-bl-min-level = <0x01>;
				qcom,mdss-dsi-bl-max-level = <0xfff>;
				qcom,mdss-brightness-max-level = <0xfff>;
				qcom,mdss-dsi-dma-trigger = "trigger_sw";
				qcom,mdss-dsi-mdp-trigger = "none";
				qcom,mdss-dsi-bl-pmic-control-type = "bl_ctrl_wled";
				qcom,mdss-dsi-pan-enable-dynamic-fps;
				qcom,mdss-dsi-pan-fps-update = "dfps_suspend_resume_mode";
				qcom,cont-splash-enabled;
				qcom,mdss-dsi-tx-eot-append;
				somc,driver-ic = <0x00>;
				somc,dric-gpio = <0x05 0x1a 0x00>;
				somc,touch-reset-gpio = <0x05 0x55 0x00>;
				somc,mul-channel-scaling = <0x03>;
				somc,mdss-phy-size-mm = <0x40 0x72>;
				somc,mdss-dsi-lane-config = [00 c2 ef 00 00 00 00 01 ff 00 c2 ef 00 00 00 00 01 ff 00 c2 ef 00 00 00 00 01 ff 00 c2 ef 00 00 00 00 01 ff 00 02 45 00 00 00 00 01 97];
				somc,mdss-dsi-disp-on-in-hs = <0x00>;
				somc,mdss-dsi-wait-time-before-on-cmd = <0x96>;
				somc,lcd-id = <0x01>;
				somc,lcd-id-adc = <0x89f08 0x9f6c8>;
				somc,disp-en-on-post = <0x14>;
				somc,pw-on-rst-seq = <0x01 0x0f>;
				somc,disp-en-off-post = <0x46>;
				somc,pw-off-rst-seq = <0x00 0x00>;
				somc,pw-down-period = <0x64>;
				somc,mdss-dsi-pre-uv-command = [23 01 00 00 00 00 02 b0 04];
				somc,mdss-dsi-uv-command = <0x6010000 0x1da 0x6010000 0x1db>;
				somc,mdss-dsi-uv-param-type = <0x04>;
				somc,mdss-dsi-pcc-table-size = <0xe1>;
				somc,mdss-dsi-pcc-table = <0x00 0x01 0x38 0x3b 0x38 0x3b 0x5700 0x7000 0x8000 0x00 0x02 0x34 0x37 0x38 0x3b 0x5900 0x6f00 0x8000 0x00 0x03 0x30 0x33 0x38 0x3b 0x5c00 0x6e00 0x8000 0x00 0x04 0x2c 0x2f 0x38 0x3b 0x5d80 0x6c80 0x8000 0x00 0x05 0x28 0x2b 0x38 0x3b 0x6080 0x6c80 0x8000 0x00 0x06 0x24 0x27 0x38 0x3b 0x6380 0x6c80 0x8000 0x00 0x07 0x20 0x23 0x38 0x3b 0x6700 0x6c00 0x8000 0x00 0x08 0x1c 0x1f 0x38 0x3b 0x6980 0x6b00 0x8000 0x00 0x09 0x18 0x1b 0x38 0x3b 0x6d00 0x6a80 0x8000 0x00 0x0a 0x14 0x17 0x38 0x3b 0x7180 0x6900 0x8000 0x00 0x0b 0x10 0x13 0x38 0x3b 0x7800 0x6800 0x8000 0x00 0x0c 0x0c 0x0f 0x38 0x3b 0x7d00 0x6700 0x8000 0x00 0x0d 0x08 0x0b 0x38 0x3b 0x8000 0x6500 0x7d00 0x00 0x0e 0x04 0x07 0x38 0x3b 0x8000 0x6000 0x7700 0x00 0x0f 0x00 0x03 0x38 0x3b 0x8000 0x5900 0x7000 0x00 0x10 0x38 0x3b 0x34 0x37 0x5900 0x7280 0x8000 0x00 0x11 0x34 0x37 0x34 0x37 0x5b00 0x7100 0x8000 0x00 0x12 0x30 0x33 0x34 0x37 0x5e00 0x7180 0x8000 0x00 0x13 0x2c 0x2f 0x34 0x37 0x6080 0x7180 0x8000 0x00 0x14 0x28 0x2b 0x34 0x37 0x6400 0x7000 0x8000 0x00 0x15 0x24 0x27 0x34 0x37 0x6700 0x7000 0x8000 0x00 0x16 0x20 0x23 0x34 0x37 0x6900 0x6f00 0x8000 0x00 0x17 0x1c 0x1f 0x34 0x37 0x6c00 0x6e80 0x8000 0x00 0x18 0x18 0x1b 0x34 0x37 0x7000 0x6d80 0x8000 0x00 0x19 0x14 0x17 0x34 0x37 0x7580 0x6b80 0x8000 0x00 0x1a 0x10 0x13 0x34 0x37 0x7b00 0x6a80 0x8000 0x00 0x1b 0x0c 0x0f 0x34 0x37 0x8000 0x6a80 0x8000 0x00 0x1c 0x08 0x0b 0x34 0x37 0x8000 0x6600 0x7c00 0x00 0x1d 0x04 0x07 0x34 0x37 0x8000 0x6100 0x7400 0x00 0x1e 0x00 0x03 0x34 0x37 0x8000 0x5b00 0x6e00 0x00 0x1f 0x38 0x3b 0x30 0x33 0x5c80 0x7600 0x8000 0x00 0x20 0x34 0x37 0x30 0x33 0x5e00 0x7500 0x8000 0x00 0x21 0x30 0x33 0x30 0x33 0x6100 0x7480 0x8000 0x00 0x22 0x2c 0x2f 0x30 0x33 0x6400 0x7400 0x8000 0x00 0x23 0x28 0x2b 0x30 0x33 0x6500 0x7300 0x8000 0x00 0x24 0x24 0x27 0x30 0x33 0x6880 0x7400 0x8000 0x00 0x25 0x20 0x23 0x30 0x33 0x6b00 0x7200 0x8000 0x00 0x26 0x1c 0x1f 0x30 0x33 0x6e00 0x6f00 0x8000 0x00 0x27 0x18 0x1b 0x30 0x33 0x7300 0x7080 0x8000 0x00 0x28 0x14 0x17 0x30 0x33 0x7700 0x6d80 0x8000 0x00 0x29 0x10 0x13 0x30 0x33 0x7c00 0x6d80 0x8000 0x00 0x2a 0x0c 0x0f 0x30 0x33 0x8000 0x6c00 0x7e00 0x00 0x2b 0x08 0x0b 0x30 0x33 0x8000 0x6700 0x7a00 0x00 0x2c 0x04 0x07 0x30 0x33 0x8000 0x6100 0x7200 0x00 0x2d 0x00 0x03 0x30 0x33 0x8000 0x5b00 0x6c00 0x00 0x2e 0x38 0x3b 0x2c 0x2f 0x5c00 0x7880 0x8000 0x00 0x2f 0x34 0x37 0x2c 0x2f 0x5f00 0x7700 0x8000 0x00 0x30 0x30 0x33 0x2c 0x2f 0x6100 0x7700 0x8000 0x00 0x31 0x2c 0x2f 0x2c 0x2f 0x6500 0x7680 0x8000 0x00 0x32 0x28 0x2b 0x2c 0x2f 0x6700 0x7600 0x8000 0x00 0x33 0x24 0x27 0x2c 0x2f 0x6a00 0x7500 0x8000 0x00 0x34 0x20 0x23 0x2c 0x2f 0x6e00 0x7500 0x8000 0x00 0x35 0x1c 0x1f 0x2c 0x2f 0x7180 0x7400 0x8000 0x00 0x36 0x18 0x1b 0x2c 0x2f 0x7580 0x7300 0x8000 0x00 0x37 0x14 0x17 0x2c 0x2f 0x7b00 0x7080 0x8000 0x00 0x38 0x10 0x13 0x2c 0x2f 0x8000 0x7080 0x7f00 0x00 0x39 0x0c 0x0f 0x2c 0x2f 0x8000 0x6b00 0x7a00 0x00 0x3a 0x08 0x0b 0x2c 0x2f 0x8000 0x6500 0x7400 0x00 0x3b 0x04 0x07 0x2c 0x2f 0x8000 0x6000 0x6d00 0x00 0x3c 0x00 0x03 0x2c 0x2f 0x8000 0x5a00 0x6800 0x00 0x3d 0x38 0x3b 0x28 0x2b 0x6000 0x7c00 0x8000 0x00 0x3e 0x34 0x37 0x28 0x2b 0x6200 0x7b00 0x8000 0x00 0x3f 0x30 0x33 0x28 0x2b 0x6600 0x7b00 0x8000 0x00 0x40 0x2c 0x2f 0x28 0x2b 0x6900 0x7c00 0x8000 0x00 0x41 0x28 0x2b 0x28 0x2b 0x6b80 0x7900 0x8000 0x00 0x42 0x24 0x27 0x28 0x2b 0x6e00 0x7900 0x8000 0x00 0x43 0x20 0x23 0x28 0x2b 0x7100 0x7780 0x8000 0x00 0x44 0x1c 0x1f 0x28 0x2b 0x7500 0x7700 0x8000 0x00 0x45 0x18 0x1b 0x28 0x2b 0x7a00 0x7600 0x8000 0x00 0x46 0x14 0x17 0x28 0x2b 0x8000 0x7500 0x8000 0x00 0x47 0x10 0x13 0x28 0x2b 0x8000 0x7000 0x7c00 0x00 0x48 0x0c 0x0f 0x28 0x2b 0x8000 0x6b00 0x7800 0x00 0x49 0x08 0x0b 0x28 0x2b 0x8000 0x6600 0x7200 0x00 0x4a 0x04 0x07 0x28 0x2b 0x8000 0x6000 0x6c00 0x00 0x4b 0x00 0x03 0x28 0x2b 0x8000 0x5900 0x6500 0x00 0x4c 0x38 0x3b 0x24 0x27 0x6200 0x8000 0x8000 0x00 0x4d 0x34 0x37 0x24 0x27 0x6500 0x7f00 0x8000 0x00 0x4e 0x30 0x33 0x24 0x27 0x6800 0x7f00 0x8000 0x00 0x4f 0x2c 0x2f 0x24 0x27 0x6b00 0x7e00 0x8000 0x00 0x50 0x28 0x2b 0x24 0x27 0x6e00 0x7c80 0x8000 0x00 0x51 0x24 0x27 0x24 0x27 0x7200 0x7d00 0x8000 0x00 0x52 0x20 0x23 0x24 0x27 0x7500 0x7a00 0x8000 0x00 0x53 0x1c 0x1f 0x24 0x27 0x7900 0x7a00 0x8000 0x00 0x54 0x18 0x1b 0x24 0x27 0x7e00 0x7a00 0x8000 0x00 0x55 0x14 0x17 0x24 0x27 0x8000 0x7300 0x7c00 0x00 0x56 0x10 0x13 0x24 0x27 0x8000 0x6e00 0x7800 0x00 0x57 0x0c 0x0f 0x24 0x27 0x8000 0x6900 0x7300 0x00 0x58 0x08 0x0b 0x24 0x27 0x8000 0x6400 0x6d00 0x00 0x59 0x04 0x07 0x24 0x27 0x8000 0x5e00 0x6800 0x00 0x5a 0x00 0x03 0x24 0x27 0x8000 0x5900 0x6300 0x00 0x5b 0x38 0x3b 0x20 0x23 0x6200 0x8000 0x7d00 0x00 0x5c 0x34 0x37 0x20 0x23 0x6600 0x8000 0x7e00 0x00 0x5d 0x30 0x33 0x20 0x23 0x6a00 0x8000 0x7f00 0x00 0x5e 0x2c 0x2f 0x20 0x23 0x6d00 0x8000 0x7f00 0x00 0x5f 0x28 0x2b 0x20 0x23 0x7100 0x8000 0x8000 0x00 0x60 0x24 0x27 0x20 0x23 0x7400 0x7f00 0x8000 0x00 0x61 0x20 0x23 0x20 0x23 0x7700 0x7e80 0x8000 0x00 0x62 0x1c 0x1f 0x20 0x23 0x7b00 0x7d00 0x8000 0x00 0x63 0x18 0x1b 0x20 0x23 0x7f00 0x7c00 0x8000 0x00 0x64 0x14 0x17 0x20 0x23 0x8000 0x7500 0x7b00 0x00 0x65 0x10 0x13 0x20 0x23 0x8000 0x7000 0x7600 0x00 0x66 0x0c 0x0f 0x20 0x23 0x8000 0x6a00 0x7100 0x00 0x67 0x08 0x0b 0x20 0x23 0x8000 0x6400 0x6b00 0x00 0x68 0x04 0x07 0x20 0x23 0x8000 0x5e00 0x6600 0x00 0x69 0x00 0x03 0x20 0x23 0x8000 0x5800 0x6000 0x00 0x6a 0x38 0x3b 0x1c 0x1f 0x6300 0x8000 0x7a00 0x00 0x6b 0x34 0x37 0x1c 0x1f 0x6600 0x8000 0x7b00 0x00 0x6c 0x30 0x33 0x1c 0x1f 0x6a00 0x8000 0x7c00 0x00 0x6d 0x2c 0x2f 0x1c 0x1f 0x6e00 0x8000 0x7d00 0x00 0x6e 0x28 0x2b 0x1c 0x1f 0x7200 0x8000 0x7e00 0x00 0x6f 0x24 0x27 0x1c 0x1f 0x7600 0x8000 0x7e00 0x00 0x70 0x20 0x23 0x1c 0x1f 0x7a00 0x8000 0x7f00 0x00 0x71 0x18 0x1b 0x1c 0x1f 0x8000 0x7c00 0x7c00 0x00 0x72 0x14 0x17 0x1c 0x1f 0x8000 0x7400 0x7780 0x00 0x73 0x10 0x13 0x1c 0x1f 0x8000 0x6f00 0x7300 0x00 0x74 0x0c 0x0f 0x1c 0x1f 0x8000 0x6900 0x6e00 0x00 0x75 0x08 0x0b 0x1c 0x1f 0x8000 0x6300 0x6800 0x00 0x76 0x04 0x07 0x1c 0x1f 0x8000 0x5d00 0x6280 0x00 0x77 0x00 0x03 0x1c 0x1f 0x8000 0x5800 0x5d00 0x00 0x78 0x38 0x3b 0x18 0x1b 0x6300 0x8000 0x7800 0x00 0x79 0x34 0x37 0x18 0x1b 0x6700 0x8000 0x7900 0x00 0x7a 0x30 0x33 0x18 0x1b 0x6a00 0x8000 0x7900 0x00 0x7b 0x2c 0x2f 0x18 0x1b 0x6e00 0x8000 0x7b00 0x00 0x7c 0x28 0x2b 0x18 0x1b 0x7180 0x8000 0x7c00 0x00 0x7d 0x24 0x27 0x18 0x1b 0x7500 0x8000 0x7b00 0x00 0x7e 0x20 0x23 0x18 0x1b 0x7a00 0x8000 0x7c80 0x00 0x7f 0x1c 0x1f 0x18 0x1b 0x8000 0x8000 0x7e00 0x00 0x80 0x18 0x1b 0x18 0x1b 0x8000 0x7a00 0x7900 0x00 0x81 0x14 0x17 0x18 0x1b 0x8000 0x7400 0x7500 0x00 0x82 0x10 0x13 0x18 0x1b 0x8000 0x6e00 0x6f00 0x00 0x83 0x0c 0x0f 0x18 0x1b 0x8000 0x6900 0x6b00 0x00 0x84 0x08 0x0b 0x18 0x1b 0x8000 0x6200 0x6500 0x00 0x85 0x04 0x07 0x18 0x1b 0x8000 0x5d00 0x6000 0x00 0x86 0x00 0x03 0x18 0x1b 0x8000 0x5700 0x5b00 0x00 0x87 0x38 0x3b 0x14 0x17 0x6300 0x8000 0x7580 0x00 0x88 0x34 0x37 0x14 0x17 0x6700 0x8000 0x7680 0x00 0x89 0x30 0x33 0x14 0x17 0x6a00 0x8000 0x7780 0x00 0x8a 0x2c 0x2f 0x14 0x17 0x6d00 0x8000 0x7800 0x00 0x8b 0x28 0x2b 0x14 0x17 0x7100 0x8000 0x7800 0x00 0x8c 0x24 0x27 0x14 0x17 0x7500 0x8000 0x7980 0x00 0x8d 0x20 0x23 0x14 0x17 0x7a00 0x8000 0x7a00 0x00 0x8e 0x1c 0x1f 0x14 0x17 0x7f00 0x8000 0x7a80 0x00 0x8f 0x18 0x1b 0x14 0x17 0x8000 0x7b00 0x7700 0x00 0x90 0x14 0x17 0x14 0x17 0x8000 0x7300 0x7100 0x00 0x91 0x10 0x13 0x14 0x17 0x8000 0x6d00 0x6d00 0x00 0x92 0x0c 0x0f 0x14 0x17 0x8000 0x6800 0x6900 0x00 0x93 0x08 0x0b 0x14 0x17 0x8000 0x6200 0x6300 0x00 0x94 0x04 0x07 0x14 0x17 0x8000 0x5c00 0x5d00 0x00 0x95 0x00 0x03 0x14 0x17 0x8000 0x5600 0x5900 0x00 0x96 0x38 0x3b 0x10 0x13 0x6300 0x8000 0x7300 0x00 0x97 0x34 0x37 0x10 0x13 0x6600 0x8000 0x7400 0x00 0x98 0x30 0x33 0x10 0x13 0x6a00 0x8000 0x7500 0x00 0x99 0x2c 0x2f 0x10 0x13 0x6e00 0x8000 0x7600 0x00 0x9a 0x28 0x2b 0x10 0x13 0x7100 0x8000 0x7600 0x00 0x9b 0x24 0x27 0x10 0x13 0x7500 0x8000 0x7700 0x00 0x9c 0x20 0x23 0x10 0x13 0x7980 0x8000 0x7800 0x00 0x9d 0x1c 0x1f 0x10 0x13 0x7f00 0x8000 0x7800 0x00 0x9e 0x18 0x1b 0x10 0x13 0x8000 0x7b00 0x7500 0x00 0x9f 0x14 0x17 0x10 0x13 0x8000 0x7300 0x6f00 0x00 0xa0 0x10 0x13 0x10 0x13 0x8000 0x6d00 0x6b00 0x00 0xa1 0x0c 0x0f 0x10 0x13 0x8000 0x6800 0x6600 0x00 0xa2 0x08 0x0b 0x10 0x13 0x8000 0x6200 0x6000 0x00 0xa3 0x04 0x07 0x10 0x13 0x8000 0x5b00 0x5b00 0x00 0xa4 0x00 0x03 0x10 0x13 0x8000 0x5600 0x5700 0x00 0xa5 0x38 0x3b 0x0c 0x0f 0x6200 0x8000 0x7000 0x00 0xa6 0x34 0x37 0x0c 0x0f 0x6700 0x8000 0x7100 0x00 0xa7 0x30 0x33 0x0c 0x0f 0x6a00 0x8000 0x7200 0x00 0xa8 0x2c 0x2f 0x0c 0x0f 0x6d00 0x8000 0x7300 0x00 0xa9 0x28 0x2b 0x0c 0x0f 0x7100 0x8000 0x7400 0x00 0xaa 0x24 0x27 0x0c 0x0f 0x7500 0x8000 0x7480 0x00 0xab 0x20 0x23 0x0c 0x0f 0x7900 0x8000 0x7500 0x00 0xac 0x1c 0x1f 0x0c 0x0f 0x7f00 0x8000 0x7600 0x00 0xad 0x18 0x1b 0x0c 0x0f 0x8000 0x7b00 0x7200 0x00 0xae 0x14 0x17 0x0c 0x0f 0x8000 0x7300 0x6d00 0x00 0xaf 0x10 0x13 0x0c 0x0f 0x8000 0x6d00 0x6800 0x00 0xb0 0x0c 0x0f 0x0c 0x0f 0x8000 0x6800 0x6400 0x00 0xb1 0x08 0x0b 0x0c 0x0f 0x8000 0x6100 0x5d00 0x00 0xb2 0x04 0x07 0x0c 0x0f 0x8000 0x5b00 0x5900 0x00 0xb3 0x00 0x03 0x0c 0x0f 0x8000 0x5600 0x5480 0x00 0xb4 0x38 0x3b 0x08 0x0b 0x6200 0x8000 0x6e00 0x00 0xb5 0x34 0x37 0x08 0x0b 0x6600 0x8000 0x6e00 0x00 0xb6 0x30 0x33 0x08 0x0b 0x6900 0x8000 0x6f00 0x00 0xb7 0x2c 0x2f 0x08 0x0b 0x6d00 0x8000 0x7000 0x00 0xb8 0x28 0x2b 0x08 0x0b 0x7100 0x8000 0x7200 0x00 0xb9 0x24 0x27 0x08 0x0b 0x7500 0x8000 0x7200 0x00 0xba 0x20 0x23 0x08 0x0b 0x7a00 0x8000 0x7200 0x00 0xbb 0x1c 0x1f 0x08 0x0b 0x7f00 0x8000 0x7300 0x00 0xbc 0x18 0x1b 0x08 0x0b 0x8000 0x7b00 0x7000 0x00 0xbd 0x14 0x17 0x08 0x0b 0x8000 0x7200 0x6a00 0x00 0xbe 0x10 0x13 0x08 0x0b 0x8000 0x6c00 0x6500 0x00 0xbf 0x0c 0x0f 0x08 0x0b 0x8000 0x6600 0x6000 0x00 0xc0 0x08 0x0b 0x08 0x0b 0x8000 0x6000 0x5b00 0x00 0xc1 0x04 0x07 0x08 0x0b 0x8000 0x5b00 0x5700 0x00 0xc2 0x00 0x03 0x08 0x0b 0x8000 0x5500 0x5100 0x00 0xc3 0x38 0x3b 0x04 0x07 0x6200 0x8000 0x6b00 0x00 0xc4 0x34 0x37 0x04 0x07 0x6500 0x8000 0x6c00 0x00 0xc5 0x30 0x33 0x04 0x07 0x6800 0x8000 0x6d80 0x00 0xc6 0x2c 0x2f 0x04 0x07 0x6c00 0x8000 0x6e00 0x00 0xc7 0x28 0x2b 0x04 0x07 0x7000 0x8000 0x6e00 0x00 0xc8 0x24 0x27 0x04 0x07 0x7400 0x8000 0x6f00 0x00 0xc9 0x20 0x23 0x04 0x07 0x7800 0x8000 0x7000 0x00 0xca 0x1c 0x1f 0x04 0x07 0x7e00 0x8000 0x7000 0x00 0xcb 0x18 0x1b 0x04 0x07 0x8000 0x7a80 0x6b80 0x00 0xcc 0x14 0x17 0x04 0x07 0x8000 0x7400 0x6780 0x00 0xcd 0x10 0x13 0x04 0x07 0x8000 0x6e00 0x6380 0x00 0xce 0x0c 0x0f 0x04 0x07 0x8000 0x6700 0x5e00 0x00 0xcf 0x08 0x0b 0x04 0x07 0x8000 0x6180 0x5980 0x00 0xd0 0x04 0x07 0x04 0x07 0x8000 0x5b00 0x5500 0x00 0xd1 0x00 0x03 0x04 0x07 0x8000 0x5500 0x5100 0x00 0xd2 0x38 0x3b 0x00 0x03 0x6100 0x8000 0x6900 0x00 0xd3 0x34 0x37 0x00 0x03 0x6400 0x8000 0x6a00 0x00 0xd4 0x30 0x33 0x00 0x03 0x6800 0x8000 0x6b00 0x00 0xd5 0x2c 0x2f 0x00 0x03 0x6c00 0x8000 0x6b80 0x00 0xd6 0x28 0x2b 0x00 0x03 0x6f00 0x8000 0x6c00 0x00 0xd7 0x24 0x27 0x00 0x03 0x7300 0x8000 0x6d00 0x00 0xd8 0x20 0x23 0x00 0x03 0x7900 0x8000 0x6d00 0x00 0xd9 0x1c 0x1f 0x00 0x03 0x7f00 0x8000 0x6e00 0x00 0xda 0x18 0x1b 0x00 0x03 0x8000 0x7b00 0x6a80 0x00 0xdb 0x14 0x17 0x00 0x03 0x8000 0x7400 0x6580 0x00 0xdc 0x10 0x13 0x00 0x03 0x8000 0x6d00 0x6180 0x00 0xdd 0x0c 0x0f 0x00 0x03 0x8000 0x6900 0x5e00 0x00 0xde 0x08 0x0b 0x00 0x03 0x8000 0x6200 0x5800 0x00 0xdf 0x04 0x07 0x00 0x03 0x8000 0x5a00 0x5200 0x00 0xe0 0x00 0x03 0x00 0x03 0x8000 0x5400 0x4d00 0xff 0x00 0x00 0x3b 0x00 0x3b 0x8000 0x8000 0x8000>;
				somc,change-fps-command = <0x15010000 0x2ff 0x24150100 0x02 0x92951501 0x00 0x2ff1015 0x1000000 0x24403>;
				somc,change-fps-default = <0x95>;
				somc,display-clock = <0x1086f50>;
				somc,driver-ic-vbp = <0x08>;
				somc,driver-ic-vfp = <0x08>;
				somc,change-fps-cmds-num = <0x01>;
				somc,change-fps-payload-num = <0x01>;
				somc,change-wait-update = <0x00>;
				somc,change-wait-on = <0x00 0x00>;
				somc,change-wait-off = <0x00 0x00>;
				somc,change-wait-cmds-num = <0x00 0x00>;
				somc,fps-threshold = <0xb928>;
				somc,te-c-update = <0x01>;
				somc,te-c-mode-60fps = <0x03 0x00>;
				somc,te-c-mode-45fps = <0x05 0x00>;
				somc,te-c-cmds-num = <0x03>;
				somc,te-c-payload-num = <0x01>;
			};

			somc,novatek_auo_1080p_cmd_panel {
				qcom,mdss-dsi-panel-name = "auo novatek 1080p cmd";
				qcom,mdss-dsi-panel-controller = <0x23>;
				qcom,mdss-dsi-panel-type = "dsi_cmd_mode";
				qcom,mdss-dsi-panel-destination = "display_1";
				qcom,mdss-dsi-panel-framerate = <0x3c>;
				qcom,mdss-dsi-virtual-channel-id = <0x00>;
				qcom,mdss-dsi-stream = <0x00>;
				qcom,mdss-dsi-panel-width = <0x438>;
				qcom,mdss-dsi-panel-height = <0x780>;
				qcom,mdss-dsi-h-front-porch = <0x38>;
				qcom,mdss-dsi-h-back-porch = <0x08>;
				qcom,mdss-dsi-h-pulse-width = <0x08>;
				qcom,mdss-dsi-h-sync-skew = <0x00>;
				qcom,mdss-dsi-v-back-porch = <0x08>;
				qcom,mdss-dsi-v-front-porch = <0xe9>;
				qcom,mdss-dsi-v-pulse-width = <0x02>;
				qcom,mdss-dsi-h-left-border = <0x00>;
				qcom,mdss-dsi-h-right-border = <0x00>;
				qcom,mdss-dsi-v-top-border = <0x00>;
				qcom,mdss-dsi-v-bottom-border = <0x00>;
				qcom,mdss-dsi-bpp = <0x18>;
				qcom,mdss-dsi-underflow-color = <0x00>;
				qcom,mdss-dsi-border-color = <0x00>;
				somc,mdss-dsi-init-command = [15 01 00 00 00 00 02 ff e0 15 01 00 00 00 00 02 fb 01 15 01 00 00 00 00 02 b5 86 15 01 00 00 00 00 02 b6 77 15 01 00 00 00 00 02 b8 ad 15 01 00 00 00 00 02 ff 20 15 01 00 00 00 00 02 fb 01 15 01 00 00 00 00 02 10 04 15 01 00 00 00 00 02 ff 24 15 01 00 00 00 00 02 fb 01 15 01 00 00 00 00 02 c6 00 15 01 00 00 00 00 02 c5 32 15 01 00 00 00 00 02 92 92 15 01 00 00 00 00 02 ff 10 15 01 00 00 00 00 02 35 00 39 01 00 00 00 00 03 44 03 00 39 01 00 00 00 00 04 3b 03 30 06 15 01 00 00 01 00 02 bb 10 05 01 00 00 1e 00 01 11];
				qcom,mdss-dsi-on-command = <0x5010000 0x28000129>;
				qcom,mdss-dsi-off-command = [15 01 00 00 00 00 02 ff 10 05 01 00 00 00 00 01 28 05 01 00 00 64 00 01 10];
				qcom,mdss-dsi-on-command-state = "dsi_hs_mode";
				qcom,mdss-dsi-off-command-state = "dsi_hs_mode";
				qcom,mdss-dsi-h-sync-pulse = <0x01>;
				qcom,mdss-dsi-traffic-mode = "non_burst_sync_event";
				qcom,mdss-dsi-bllp-eof-power-mode;
				qcom,mdss-dsi-bllp-power-mode;
				qcom,mdss-dsi-lane-0-state;
				qcom,mdss-dsi-lane-1-state;
				qcom,mdss-dsi-lane-2-state;
				qcom,mdss-dsi-lane-3-state;
				qcom,mdss-dsi-te-pin-select = <0x01>;
				qcom,mdss-dsi-wr-mem-start = <0x2c>;
				qcom,mdss-dsi-wr-mem-continue = <0x3c>;
				qcom,mdss-dsi-te-dcs-command = <0x01>;
				qcom,mdss-dsi-te-check-enable;
				qcom,mdss-dsi-te-using-te-pin;
				qcom,mdss-dsi-panel-timings = <0xe6382600 0x686e2a3c 0x2c030400>;
				qcom,mdss-dsi-lp11-init;
				qcom,mdss-dsi-t-clk-post = <0x21>;
				qcom,mdss-dsi-t-clk-pre = <0x2b>;
				qcom,mdss-dsi-bl-min-level = <0x01>;
				qcom,mdss-dsi-bl-max-level = <0xfff>;
				qcom,mdss-brightness-max-level = <0xfff>;
				qcom,mdss-dsi-dma-trigger = "trigger_sw";
				qcom,mdss-dsi-mdp-trigger = "none";
				qcom,mdss-dsi-bl-pmic-control-type = "bl_ctrl_wled";
				qcom,mdss-dsi-pan-enable-dynamic-fps;
				qcom,mdss-dsi-pan-fps-update = "dfps_suspend_resume_mode";
				qcom,cont-splash-enabled;
				qcom,mdss-dsi-tx-eot-append;
				somc,driver-ic = <0x00>;
				somc,dric-gpio = <0x05 0x1a 0x00>;
				somc,touch-reset-gpio = <0x05 0x55 0x00>;
				somc,mul-channel-scaling = <0x03>;
				somc,mdss-phy-size-mm = <0x40 0x72>;
				somc,mdss-dsi-lane-config = [00 c2 ef 00 00 00 00 01 ff 00 c2 ef 00 00 00 00 01 ff 00 c2 ef 00 00 00 00 01 ff 00 c2 ef 00 00 00 00 01 ff 00 02 45 00 00 00 00 01 97];
				somc,mdss-dsi-disp-on-in-hs = <0x00>;
				somc,mdss-dsi-wait-time-before-on-cmd = <0x64>;
				somc,lcd-id = <0x01>;
				somc,lcd-id-adc = <0x12dc20 0x154938>;
				somc,disp-en-on-post = <0x14>;
				somc,pw-on-rst-seq = <0x01 0x0a>;
				somc,disp-en-off-post = <0x46>;
				somc,pw-off-rst-seq = <0x00 0x00>;
				somc,pw-down-period = <0x64>;
				somc,mdss-dsi-pre-uv-command = [23 01 00 00 00 00 02 b0 04];
				somc,mdss-dsi-uv-command = <0x6010000 0x1da 0x6010000 0x1db>;
				somc,mdss-dsi-uv-param-type = <0x04>;
				somc,mdss-dsi-pcc-table-size = <0xe1>;
				somc,mdss-dsi-pcc-table = <0x00 0x01 0x38 0x3b 0x38 0x3b 0x5700 0x7000 0x8000 0x00 0x02 0x34 0x37 0x38 0x3b 0x5900 0x6f00 0x8000 0x00 0x03 0x30 0x33 0x38 0x3b 0x5c00 0x6e00 0x8000 0x00 0x04 0x2c 0x2f 0x38 0x3b 0x5d80 0x6c80 0x8000 0x00 0x05 0x28 0x2b 0x38 0x3b 0x6080 0x6c80 0x8000 0x00 0x06 0x24 0x27 0x38 0x3b 0x6380 0x6c80 0x8000 0x00 0x07 0x20 0x23 0x38 0x3b 0x6700 0x6c00 0x8000 0x00 0x08 0x1c 0x1f 0x38 0x3b 0x6980 0x6b00 0x8000 0x00 0x09 0x18 0x1b 0x38 0x3b 0x6d00 0x6a80 0x8000 0x00 0x0a 0x14 0x17 0x38 0x3b 0x7180 0x6900 0x8000 0x00 0x0b 0x10 0x13 0x38 0x3b 0x7800 0x6800 0x8000 0x00 0x0c 0x0c 0x0f 0x38 0x3b 0x7d00 0x6700 0x8000 0x00 0x0d 0x08 0x0b 0x38 0x3b 0x8000 0x6500 0x7d00 0x00 0x0e 0x04 0x07 0x38 0x3b 0x8000 0x6000 0x7700 0x00 0x0f 0x00 0x03 0x38 0x3b 0x8000 0x5900 0x7000 0x00 0x10 0x38 0x3b 0x34 0x37 0x5900 0x7280 0x8000 0x00 0x11 0x34 0x37 0x34 0x37 0x5b00 0x7100 0x8000 0x00 0x12 0x30 0x33 0x34 0x37 0x5e00 0x7180 0x8000 0x00 0x13 0x2c 0x2f 0x34 0x37 0x6080 0x7180 0x8000 0x00 0x14 0x28 0x2b 0x34 0x37 0x6400 0x7000 0x8000 0x00 0x15 0x24 0x27 0x34 0x37 0x6700 0x7000 0x8000 0x00 0x16 0x20 0x23 0x34 0x37 0x6900 0x6f00 0x8000 0x00 0x17 0x1c 0x1f 0x34 0x37 0x6c00 0x6e80 0x8000 0x00 0x18 0x18 0x1b 0x34 0x37 0x7000 0x6d80 0x8000 0x00 0x19 0x14 0x17 0x34 0x37 0x7580 0x6b80 0x8000 0x00 0x1a 0x10 0x13 0x34 0x37 0x7b00 0x6a80 0x8000 0x00 0x1b 0x0c 0x0f 0x34 0x37 0x8000 0x6a80 0x8000 0x00 0x1c 0x08 0x0b 0x34 0x37 0x8000 0x6600 0x7c00 0x00 0x1d 0x04 0x07 0x34 0x37 0x8000 0x6100 0x7400 0x00 0x1e 0x00 0x03 0x34 0x37 0x8000 0x5b00 0x6e00 0x00 0x1f 0x38 0x3b 0x30 0x33 0x5c80 0x7600 0x8000 0x00 0x20 0x34 0x37 0x30 0x33 0x5e00 0x7500 0x8000 0x00 0x21 0x30 0x33 0x30 0x33 0x6100 0x7480 0x8000 0x00 0x22 0x2c 0x2f 0x30 0x33 0x6400 0x7400 0x8000 0x00 0x23 0x28 0x2b 0x30 0x33 0x6500 0x7300 0x8000 0x00 0x24 0x24 0x27 0x30 0x33 0x6880 0x7400 0x8000 0x00 0x25 0x20 0x23 0x30 0x33 0x6b00 0x7200 0x8000 0x00 0x26 0x1c 0x1f 0x30 0x33 0x6e00 0x6f00 0x8000 0x00 0x27 0x18 0x1b 0x30 0x33 0x7300 0x7080 0x8000 0x00 0x28 0x14 0x17 0x30 0x33 0x7700 0x6d80 0x8000 0x00 0x29 0x10 0x13 0x30 0x33 0x7c00 0x6d80 0x8000 0x00 0x2a 0x0c 0x0f 0x30 0x33 0x8000 0x6c00 0x7e00 0x00 0x2b 0x08 0x0b 0x30 0x33 0x8000 0x6700 0x7a00 0x00 0x2c 0x04 0x07 0x30 0x33 0x8000 0x6100 0x7200 0x00 0x2d 0x00 0x03 0x30 0x33 0x8000 0x5b00 0x6c00 0x00 0x2e 0x38 0x3b 0x2c 0x2f 0x5c00 0x7880 0x8000 0x00 0x2f 0x34 0x37 0x2c 0x2f 0x5f00 0x7700 0x8000 0x00 0x30 0x30 0x33 0x2c 0x2f 0x6100 0x7700 0x8000 0x00 0x31 0x2c 0x2f 0x2c 0x2f 0x6500 0x7680 0x8000 0x00 0x32 0x28 0x2b 0x2c 0x2f 0x6700 0x7600 0x8000 0x00 0x33 0x24 0x27 0x2c 0x2f 0x6a00 0x7500 0x8000 0x00 0x34 0x20 0x23 0x2c 0x2f 0x6e00 0x7500 0x8000 0x00 0x35 0x1c 0x1f 0x2c 0x2f 0x7180 0x7400 0x8000 0x00 0x36 0x18 0x1b 0x2c 0x2f 0x7580 0x7300 0x8000 0x00 0x37 0x14 0x17 0x2c 0x2f 0x7b00 0x7080 0x8000 0x00 0x38 0x10 0x13 0x2c 0x2f 0x8000 0x7080 0x7f00 0x00 0x39 0x0c 0x0f 0x2c 0x2f 0x8000 0x6b00 0x7a00 0x00 0x3a 0x08 0x0b 0x2c 0x2f 0x8000 0x6500 0x7400 0x00 0x3b 0x04 0x07 0x2c 0x2f 0x8000 0x6000 0x6d00 0x00 0x3c 0x00 0x03 0x2c 0x2f 0x8000 0x5a00 0x6800 0x00 0x3d 0x38 0x3b 0x28 0x2b 0x6000 0x7c00 0x8000 0x00 0x3e 0x34 0x37 0x28 0x2b 0x6200 0x7b00 0x8000 0x00 0x3f 0x30 0x33 0x28 0x2b 0x6600 0x7b00 0x8000 0x00 0x40 0x2c 0x2f 0x28 0x2b 0x6900 0x7c00 0x8000 0x00 0x41 0x28 0x2b 0x28 0x2b 0x6b80 0x7900 0x8000 0x00 0x42 0x24 0x27 0x28 0x2b 0x6e00 0x7900 0x8000 0x00 0x43 0x20 0x23 0x28 0x2b 0x7100 0x7780 0x8000 0x00 0x44 0x1c 0x1f 0x28 0x2b 0x7500 0x7700 0x8000 0x00 0x45 0x18 0x1b 0x28 0x2b 0x7a00 0x7600 0x8000 0x00 0x46 0x14 0x17 0x28 0x2b 0x8000 0x7500 0x8000 0x00 0x47 0x10 0x13 0x28 0x2b 0x8000 0x7000 0x7c00 0x00 0x48 0x0c 0x0f 0x28 0x2b 0x8000 0x6b00 0x7800 0x00 0x49 0x08 0x0b 0x28 0x2b 0x8000 0x6600 0x7200 0x00 0x4a 0x04 0x07 0x28 0x2b 0x8000 0x6000 0x6c00 0x00 0x4b 0x00 0x03 0x28 0x2b 0x8000 0x5900 0x6500 0x00 0x4c 0x38 0x3b 0x24 0x27 0x6200 0x8000 0x8000 0x00 0x4d 0x34 0x37 0x24 0x27 0x6500 0x7f00 0x8000 0x00 0x4e 0x30 0x33 0x24 0x27 0x6800 0x7f00 0x8000 0x00 0x4f 0x2c 0x2f 0x24 0x27 0x6b00 0x7e00 0x8000 0x00 0x50 0x28 0x2b 0x24 0x27 0x6e00 0x7c80 0x8000 0x00 0x51 0x24 0x27 0x24 0x27 0x7200 0x7d00 0x8000 0x00 0x52 0x20 0x23 0x24 0x27 0x7500 0x7a00 0x8000 0x00 0x53 0x1c 0x1f 0x24 0x27 0x7900 0x7a00 0x8000 0x00 0x54 0x18 0x1b 0x24 0x27 0x7e00 0x7a00 0x8000 0x00 0x55 0x14 0x17 0x24 0x27 0x8000 0x7300 0x7c00 0x00 0x56 0x10 0x13 0x24 0x27 0x8000 0x6e00 0x7800 0x00 0x57 0x0c 0x0f 0x24 0x27 0x8000 0x6900 0x7300 0x00 0x58 0x08 0x0b 0x24 0x27 0x8000 0x6400 0x6d00 0x00 0x59 0x04 0x07 0x24 0x27 0x8000 0x5e00 0x6800 0x00 0x5a 0x00 0x03 0x24 0x27 0x8000 0x5900 0x6300 0x00 0x5b 0x38 0x3b 0x20 0x23 0x6200 0x8000 0x7d00 0x00 0x5c 0x34 0x37 0x20 0x23 0x6600 0x8000 0x7e00 0x00 0x5d 0x30 0x33 0x20 0x23 0x6a00 0x8000 0x7f00 0x00 0x5e 0x2c 0x2f 0x20 0x23 0x6d00 0x8000 0x7f00 0x00 0x5f 0x28 0x2b 0x20 0x23 0x7100 0x8000 0x8000 0x00 0x60 0x24 0x27 0x20 0x23 0x7400 0x7f00 0x8000 0x00 0x61 0x20 0x23 0x20 0x23 0x7700 0x7e80 0x8000 0x00 0x62 0x1c 0x1f 0x20 0x23 0x7b00 0x7d00 0x8000 0x00 0x63 0x18 0x1b 0x20 0x23 0x7f00 0x7c00 0x8000 0x00 0x64 0x14 0x17 0x20 0x23 0x8000 0x7500 0x7b00 0x00 0x65 0x10 0x13 0x20 0x23 0x8000 0x7000 0x7600 0x00 0x66 0x0c 0x0f 0x20 0x23 0x8000 0x6a00 0x7100 0x00 0x67 0x08 0x0b 0x20 0x23 0x8000 0x6400 0x6b00 0x00 0x68 0x04 0x07 0x20 0x23 0x8000 0x5e00 0x6600 0x00 0x69 0x00 0x03 0x20 0x23 0x8000 0x5800 0x6000 0x00 0x6a 0x38 0x3b 0x1c 0x1f 0x6300 0x8000 0x7a00 0x00 0x6b 0x34 0x37 0x1c 0x1f 0x6600 0x8000 0x7b00 0x00 0x6c 0x30 0x33 0x1c 0x1f 0x6a00 0x8000 0x7c00 0x00 0x6d 0x2c 0x2f 0x1c 0x1f 0x6e00 0x8000 0x7d00 0x00 0x6e 0x28 0x2b 0x1c 0x1f 0x7200 0x8000 0x7e00 0x00 0x6f 0x24 0x27 0x1c 0x1f 0x7600 0x8000 0x7e00 0x00 0x70 0x20 0x23 0x1c 0x1f 0x7a00 0x8000 0x7f00 0x00 0x71 0x18 0x1b 0x1c 0x1f 0x8000 0x7c00 0x7c00 0x00 0x72 0x14 0x17 0x1c 0x1f 0x8000 0x7400 0x7780 0x00 0x73 0x10 0x13 0x1c 0x1f 0x8000 0x6f00 0x7300 0x00 0x74 0x0c 0x0f 0x1c 0x1f 0x8000 0x6900 0x6e00 0x00 0x75 0x08 0x0b 0x1c 0x1f 0x8000 0x6300 0x6800 0x00 0x76 0x04 0x07 0x1c 0x1f 0x8000 0x5d00 0x6280 0x00 0x77 0x00 0x03 0x1c 0x1f 0x8000 0x5800 0x5d00 0x00 0x78 0x38 0x3b 0x18 0x1b 0x6300 0x8000 0x7800 0x00 0x79 0x34 0x37 0x18 0x1b 0x6700 0x8000 0x7900 0x00 0x7a 0x30 0x33 0x18 0x1b 0x6a00 0x8000 0x7900 0x00 0x7b 0x2c 0x2f 0x18 0x1b 0x6e00 0x8000 0x7b00 0x00 0x7c 0x28 0x2b 0x18 0x1b 0x7180 0x8000 0x7c00 0x00 0x7d 0x24 0x27 0x18 0x1b 0x7500 0x8000 0x7b00 0x00 0x7e 0x20 0x23 0x18 0x1b 0x7a00 0x8000 0x7c80 0x00 0x7f 0x1c 0x1f 0x18 0x1b 0x8000 0x8000 0x7e00 0x00 0x80 0x18 0x1b 0x18 0x1b 0x8000 0x7a00 0x7900 0x00 0x81 0x14 0x17 0x18 0x1b 0x8000 0x7400 0x7500 0x00 0x82 0x10 0x13 0x18 0x1b 0x8000 0x6e00 0x6f00 0x00 0x83 0x0c 0x0f 0x18 0x1b 0x8000 0x6900 0x6b00 0x00 0x84 0x08 0x0b 0x18 0x1b 0x8000 0x6200 0x6500 0x00 0x85 0x04 0x07 0x18 0x1b 0x8000 0x5d00 0x6000 0x00 0x86 0x00 0x03 0x18 0x1b 0x8000 0x5700 0x5b00 0x00 0x87 0x38 0x3b 0x14 0x17 0x6300 0x8000 0x7580 0x00 0x88 0x34 0x37 0x14 0x17 0x6700 0x8000 0x7680 0x00 0x89 0x30 0x33 0x14 0x17 0x6a00 0x8000 0x7780 0x00 0x8a 0x2c 0x2f 0x14 0x17 0x6d00 0x8000 0x7800 0x00 0x8b 0x28 0x2b 0x14 0x17 0x7100 0x8000 0x7800 0x00 0x8c 0x24 0x27 0x14 0x17 0x7500 0x8000 0x7980 0x00 0x8d 0x20 0x23 0x14 0x17 0x7a00 0x8000 0x7a00 0x00 0x8e 0x1c 0x1f 0x14 0x17 0x7f00 0x8000 0x7a80 0x00 0x8f 0x18 0x1b 0x14 0x17 0x8000 0x7b00 0x7700 0x00 0x90 0x14 0x17 0x14 0x17 0x8000 0x7300 0x7100 0x00 0x91 0x10 0x13 0x14 0x17 0x8000 0x6d00 0x6d00 0x00 0x92 0x0c 0x0f 0x14 0x17 0x8000 0x6800 0x6900 0x00 0x93 0x08 0x0b 0x14 0x17 0x8000 0x6200 0x6300 0x00 0x94 0x04 0x07 0x14 0x17 0x8000 0x5c00 0x5d00 0x00 0x95 0x00 0x03 0x14 0x17 0x8000 0x5600 0x5900 0x00 0x96 0x38 0x3b 0x10 0x13 0x6300 0x8000 0x7300 0x00 0x97 0x34 0x37 0x10 0x13 0x6600 0x8000 0x7400 0x00 0x98 0x30 0x33 0x10 0x13 0x6a00 0x8000 0x7500 0x00 0x99 0x2c 0x2f 0x10 0x13 0x6e00 0x8000 0x7600 0x00 0x9a 0x28 0x2b 0x10 0x13 0x7100 0x8000 0x7600 0x00 0x9b 0x24 0x27 0x10 0x13 0x7500 0x8000 0x7700 0x00 0x9c 0x20 0x23 0x10 0x13 0x7980 0x8000 0x7800 0x00 0x9d 0x1c 0x1f 0x10 0x13 0x7f00 0x8000 0x7800 0x00 0x9e 0x18 0x1b 0x10 0x13 0x8000 0x7b00 0x7500 0x00 0x9f 0x14 0x17 0x10 0x13 0x8000 0x7300 0x6f00 0x00 0xa0 0x10 0x13 0x10 0x13 0x8000 0x6d00 0x6b00 0x00 0xa1 0x0c 0x0f 0x10 0x13 0x8000 0x6800 0x6600 0x00 0xa2 0x08 0x0b 0x10 0x13 0x8000 0x6200 0x6000 0x00 0xa3 0x04 0x07 0x10 0x13 0x8000 0x5b00 0x5b00 0x00 0xa4 0x00 0x03 0x10 0x13 0x8000 0x5600 0x5700 0x00 0xa5 0x38 0x3b 0x0c 0x0f 0x6200 0x8000 0x7000 0x00 0xa6 0x34 0x37 0x0c 0x0f 0x6700 0x8000 0x7100 0x00 0xa7 0x30 0x33 0x0c 0x0f 0x6a00 0x8000 0x7200 0x00 0xa8 0x2c 0x2f 0x0c 0x0f 0x6d00 0x8000 0x7300 0x00 0xa9 0x28 0x2b 0x0c 0x0f 0x7100 0x8000 0x7400 0x00 0xaa 0x24 0x27 0x0c 0x0f 0x7500 0x8000 0x7480 0x00 0xab 0x20 0x23 0x0c 0x0f 0x7900 0x8000 0x7500 0x00 0xac 0x1c 0x1f 0x0c 0x0f 0x7f00 0x8000 0x7600 0x00 0xad 0x18 0x1b 0x0c 0x0f 0x8000 0x7b00 0x7200 0x00 0xae 0x14 0x17 0x0c 0x0f 0x8000 0x7300 0x6d00 0x00 0xaf 0x10 0x13 0x0c 0x0f 0x8000 0x6d00 0x6800 0x00 0xb0 0x0c 0x0f 0x0c 0x0f 0x8000 0x6800 0x6400 0x00 0xb1 0x08 0x0b 0x0c 0x0f 0x8000 0x6100 0x5d00 0x00 0xb2 0x04 0x07 0x0c 0x0f 0x8000 0x5b00 0x5900 0x00 0xb3 0x00 0x03 0x0c 0x0f 0x8000 0x5600 0x5480 0x00 0xb4 0x38 0x3b 0x08 0x0b 0x6200 0x8000 0x6e00 0x00 0xb5 0x34 0x37 0x08 0x0b 0x6600 0x8000 0x6e00 0x00 0xb6 0x30 0x33 0x08 0x0b 0x6900 0x8000 0x6f00 0x00 0xb7 0x2c 0x2f 0x08 0x0b 0x6d00 0x8000 0x7000 0x00 0xb8 0x28 0x2b 0x08 0x0b 0x7100 0x8000 0x7200 0x00 0xb9 0x24 0x27 0x08 0x0b 0x7500 0x8000 0x7200 0x00 0xba 0x20 0x23 0x08 0x0b 0x7a00 0x8000 0x7200 0x00 0xbb 0x1c 0x1f 0x08 0x0b 0x7f00 0x8000 0x7300 0x00 0xbc 0x18 0x1b 0x08 0x0b 0x8000 0x7b00 0x7000 0x00 0xbd 0x14 0x17 0x08 0x0b 0x8000 0x7200 0x6a00 0x00 0xbe 0x10 0x13 0x08 0x0b 0x8000 0x6c00 0x6500 0x00 0xbf 0x0c 0x0f 0x08 0x0b 0x8000 0x6600 0x6000 0x00 0xc0 0x08 0x0b 0x08 0x0b 0x8000 0x6000 0x5b00 0x00 0xc1 0x04 0x07 0x08 0x0b 0x8000 0x5b00 0x5700 0x00 0xc2 0x00 0x03 0x08 0x0b 0x8000 0x5500 0x5100 0x00 0xc3 0x38 0x3b 0x04 0x07 0x6200 0x8000 0x6b00 0x00 0xc4 0x34 0x37 0x04 0x07 0x6500 0x8000 0x6c00 0x00 0xc5 0x30 0x33 0x04 0x07 0x6800 0x8000 0x6d80 0x00 0xc6 0x2c 0x2f 0x04 0x07 0x6c00 0x8000 0x6e00 0x00 0xc7 0x28 0x2b 0x04 0x07 0x7000 0x8000 0x6e00 0x00 0xc8 0x24 0x27 0x04 0x07 0x7400 0x8000 0x6f00 0x00 0xc9 0x20 0x23 0x04 0x07 0x7800 0x8000 0x7000 0x00 0xca 0x1c 0x1f 0x04 0x07 0x7e00 0x8000 0x7000 0x00 0xcb 0x18 0x1b 0x04 0x07 0x8000 0x7a80 0x6b80 0x00 0xcc 0x14 0x17 0x04 0x07 0x8000 0x7400 0x6780 0x00 0xcd 0x10 0x13 0x04 0x07 0x8000 0x6e00 0x6380 0x00 0xce 0x0c 0x0f 0x04 0x07 0x8000 0x6700 0x5e00 0x00 0xcf 0x08 0x0b 0x04 0x07 0x8000 0x6180 0x5980 0x00 0xd0 0x04 0x07 0x04 0x07 0x8000 0x5b00 0x5500 0x00 0xd1 0x00 0x03 0x04 0x07 0x8000 0x5500 0x5100 0x00 0xd2 0x38 0x3b 0x00 0x03 0x6100 0x8000 0x6900 0x00 0xd3 0x34 0x37 0x00 0x03 0x6400 0x8000 0x6a00 0x00 0xd4 0x30 0x33 0x00 0x03 0x6800 0x8000 0x6b00 0x00 0xd5 0x2c 0x2f 0x00 0x03 0x6c00 0x8000 0x6b80 0x00 0xd6 0x28 0x2b 0x00 0x03 0x6f00 0x8000 0x6c00 0x00 0xd7 0x24 0x27 0x00 0x03 0x7300 0x8000 0x6d00 0x00 0xd8 0x20 0x23 0x00 0x03 0x7900 0x8000 0x6d00 0x00 0xd9 0x1c 0x1f 0x00 0x03 0x7f00 0x8000 0x6e00 0x00 0xda 0x18 0x1b 0x00 0x03 0x8000 0x7b00 0x6a80 0x00 0xdb 0x14 0x17 0x00 0x03 0x8000 0x7400 0x6580 0x00 0xdc 0x10 0x13 0x00 0x03 0x8000 0x6d00 0x6180 0x00 0xdd 0x0c 0x0f 0x00 0x03 0x8000 0x6900 0x5e00 0x00 0xde 0x08 0x0b 0x00 0x03 0x8000 0x6200 0x5800 0x00 0xdf 0x04 0x07 0x00 0x03 0x8000 0x5a00 0x5200 0x00 0xe0 0x00 0x03 0x00 0x03 0x8000 0x5400 0x4d00 0xff 0x00 0x00 0x3b 0x00 0x3b 0x8000 0x8000 0x8000>;
				somc,change-fps-command = [15 01 00 00 00 00 02 ff 24 15 01 00 00 00 00 02 92 92 15 01 00 00 00 00 02 ff 10 39 01 00 00 00 00 03 44 03 00];
				somc,change-fps-default = <0x92>;
				somc,display-clock = <0x1086f50>;
				somc,driver-ic-vbp = <0x30>;
				somc,driver-ic-vfp = <0x06>;
				somc,change-fps-cmds-num = <0x01>;
				somc,change-fps-payload-num = <0x01>;
				somc,change-wait-update = <0x00>;
				somc,change-wait-on = <0x00 0x00>;
				somc,change-wait-off = <0x00 0x00>;
				somc,change-wait-cmds-num = <0x00 0x00>;
				somc,fps-threshold = <0xb928>;
				somc,te-c-update = <0x01>;
				somc,te-c-mode-60fps = <0x03 0x00>;
				somc,te-c-mode-45fps = <0x04 0xff>;
				somc,te-c-cmds-num = <0x03>;
				somc,te-c-payload-num = <0x01>;
			};

			somc,novatek_lgd_1080p_cmd_panel {
				qcom,mdss-dsi-panel-name = "lgd novatek 1080p cmd";
				qcom,mdss-dsi-panel-controller = <0x23>;
				qcom,mdss-dsi-panel-type = "dsi_cmd_mode";
				qcom,mdss-dsi-panel-destination = "display_1";
				qcom,mdss-dsi-panel-framerate = <0x3c>;
				qcom,mdss-dsi-virtual-channel-id = <0x00>;
				qcom,mdss-dsi-stream = <0x00>;
				qcom,mdss-dsi-panel-width = <0x438>;
				qcom,mdss-dsi-panel-height = <0x780>;
				qcom,mdss-dsi-h-front-porch = <0x38>;
				qcom,mdss-dsi-h-back-porch = <0x08>;
				qcom,mdss-dsi-h-pulse-width = <0x08>;
				qcom,mdss-dsi-h-sync-skew = <0x00>;
				qcom,mdss-dsi-v-back-porch = <0x08>;
				qcom,mdss-dsi-v-front-porch = <0xe9>;
				qcom,mdss-dsi-v-pulse-width = <0x02>;
				qcom,mdss-dsi-h-left-border = <0x00>;
				qcom,mdss-dsi-h-right-border = <0x00>;
				qcom,mdss-dsi-v-top-border = <0x00>;
				qcom,mdss-dsi-v-bottom-border = <0x00>;
				qcom,mdss-dsi-bpp = <0x18>;
				qcom,mdss-dsi-underflow-color = <0x00>;
				qcom,mdss-dsi-border-color = <0x00>;
				somc,mdss-dsi-init-command = <0x15010000 0x2ff 0x24150100 0x02 0xfb011501 0x00 0x2c60015 0x1000000 0x29294 0x15010000 0x2ff 0xe0150100 0x02 0xfb011501 0x00 0x2b8ad15 0x1000000 0x2b586 0x15010000 0x2b6 0x77150100 0x02 0xffe01501 0x00 0x2fb0115 0x1000000 0x21000 0x15010000 0x2ff 0x24150100 0x02 0xfb011501 0x00 0x2c42415 0x1000000 0x2ff10 0x15010000 0x2fb 0x1150100 0x02 0x35003901 0x00 0x3440300 0x5010000 0x1e000111>;
				qcom,mdss-dsi-on-command = <0x5010000 0x129>;
				qcom,mdss-dsi-off-command = <0x5010000 0x14000128 0x5010000 0x64000110>;
				qcom,mdss-dsi-on-command-state = "dsi_hs_mode";
				qcom,mdss-dsi-off-command-state = "dsi_hs_mode";
				qcom,mdss-dsi-h-sync-pulse = <0x01>;
				qcom,mdss-dsi-traffic-mode = "non_burst_sync_event";
				qcom,mdss-dsi-bllp-eof-power-mode;
				qcom,mdss-dsi-bllp-power-mode;
				qcom,mdss-dsi-lane-0-state;
				qcom,mdss-dsi-lane-1-state;
				qcom,mdss-dsi-lane-2-state;
				qcom,mdss-dsi-lane-3-state;
				qcom,mdss-dsi-te-pin-select = <0x01>;
				qcom,mdss-dsi-wr-mem-start = <0x2c>;
				qcom,mdss-dsi-wr-mem-continue = <0x3c>;
				qcom,mdss-dsi-te-dcs-command = <0x01>;
				qcom,mdss-dsi-te-check-enable;
				qcom,mdss-dsi-te-using-te-pin;
				qcom,mdss-dsi-panel-timings = <0xe6382600 0x686e2a3c 0x2c030400>;
				qcom,mdss-dsi-lp11-init;
				qcom,mdss-dsi-t-clk-post = <0x21>;
				qcom,mdss-dsi-t-clk-pre = <0x2b>;
				qcom,mdss-dsi-bl-min-level = <0x01>;
				qcom,mdss-dsi-bl-max-level = <0xfff>;
				qcom,mdss-brightness-max-level = <0xfff>;
				qcom,mdss-dsi-dma-trigger = "trigger_sw";
				qcom,mdss-dsi-mdp-trigger = "none";
				qcom,mdss-dsi-bl-pmic-control-type = "bl_ctrl_wled";
				qcom,mdss-dsi-pan-enable-dynamic-fps;
				qcom,mdss-dsi-pan-fps-update = "dfps_suspend_resume_mode";
				qcom,cont-splash-enabled;
				qcom,mdss-dsi-tx-eot-append;
				somc,driver-ic = <0x00>;
				somc,dric-gpio = <0x05 0x1a 0x00>;
				somc,touch-reset-gpio = <0x05 0x55 0x00>;
				somc,mul-channel-scaling = <0x03>;
				somc,mdss-phy-size-mm = <0x40 0x72>;
				somc,mdss-dsi-lane-config = [00 c2 ef 00 00 00 00 01 ff 00 c2 ef 00 00 00 00 01 ff 00 c2 ef 00 00 00 00 01 ff 00 c2 ef 00 00 00 00 01 ff 00 02 45 00 00 00 00 01 97];
				somc,mdss-dsi-disp-on-in-hs = <0x00>;
				somc,mdss-dsi-wait-time-before-on-cmd = <0x64>;
				somc,lcd-id = <0x01>;
				somc,lcd-id-adc = <0x15aae0 0x185290>;
				somc,disp-en-on-pre = <0x01>;
				somc,pw-on-rst-seq = <0x00 0x14 0x01 0x0a 0x00 0x01 0x01 0x14>;
				somc,disp-en-off-post = <0x0a>;
				somc,pw-off-rst-seq = <0x00 0x01>;
				somc,pw-down-period = <0x64>;
				somc,mdss-dsi-uv-command = <0x6010000 0x1da 0x6010000 0x1db>;
				somc,mdss-dsi-uv-param-type = <0x04>;
				somc,mdss-dsi-pcc-table-size = <0xe1>;
				somc,mdss-dsi-pcc-table = <0x00 0x01 0x38 0x3b 0x38 0x3b 0x8000 0x8000 0x8000 0x00 0x02 0x34 0x37 0x38 0x3b 0x8000 0x8000 0x8000 0x00 0x03 0x30 0x33 0x38 0x3b 0x8000 0x8000 0x8000 0x00 0x04 0x2c 0x2f 0x38 0x3b 0x8000 0x8000 0x8000 0x00 0x05 0x28 0x2b 0x38 0x3b 0x8000 0x8000 0x8000 0x00 0x06 0x24 0x27 0x38 0x3b 0x8000 0x8000 0x8000 0x00 0x07 0x20 0x23 0x38 0x3b 0x8000 0x8000 0x8000 0x00 0x08 0x1c 0x1f 0x38 0x3b 0x8000 0x8000 0x8000 0x00 0x09 0x18 0x1b 0x38 0x3b 0x8000 0x8000 0x8000 0x00 0x0a 0x14 0x17 0x38 0x3b 0x8000 0x8000 0x8000 0x00 0x0b 0x10 0x13 0x38 0x3b 0x8000 0x8000 0x8000 0x00 0x0c 0x0c 0x0f 0x38 0x3b 0x8000 0x8000 0x8000 0x00 0x0d 0x08 0x0b 0x38 0x3b 0x8000 0x8000 0x8000 0x00 0x0e 0x04 0x07 0x38 0x3b 0x8000 0x8000 0x8000 0x00 0x0f 0x00 0x03 0x38 0x3b 0x8000 0x8000 0x8000 0x00 0x10 0x38 0x3b 0x34 0x37 0x8000 0x8000 0x8000 0x00 0x11 0x34 0x37 0x34 0x37 0x8000 0x8000 0x8000 0x00 0x12 0x30 0x33 0x34 0x37 0x8000 0x8000 0x8000 0x00 0x13 0x2c 0x2f 0x34 0x37 0x8000 0x8000 0x8000 0x00 0x14 0x28 0x2b 0x34 0x37 0x8000 0x8000 0x8000 0x00 0x15 0x24 0x27 0x34 0x37 0x8000 0x8000 0x8000 0x00 0x16 0x20 0x23 0x34 0x37 0x8000 0x8000 0x8000 0x00 0x17 0x1c 0x1f 0x34 0x37 0x8000 0x8000 0x8000 0x00 0x18 0x18 0x1b 0x34 0x37 0x8000 0x8000 0x8000 0x00 0x19 0x14 0x17 0x34 0x37 0x8000 0x8000 0x8000 0x00 0x1a 0x10 0x13 0x34 0x37 0x8000 0x8000 0x8000 0x00 0x1b 0x0c 0x0f 0x34 0x37 0x8000 0x8000 0x8000 0x00 0x1c 0x08 0x0b 0x34 0x37 0x8000 0x8000 0x8000 0x00 0x1d 0x04 0x07 0x34 0x37 0x8000 0x8000 0x8000 0x00 0x1e 0x00 0x03 0x34 0x37 0x8000 0x8000 0x8000 0x00 0x1f 0x38 0x3b 0x30 0x33 0x8000 0x8000 0x8000 0x00 0x20 0x34 0x37 0x30 0x33 0x8000 0x8000 0x8000 0x00 0x21 0x30 0x33 0x30 0x33 0x8000 0x8000 0x8000 0x00 0x22 0x2d 0x2f 0x30 0x33 0x8000 0x8000 0x8000 0x00 0x23 0x28 0x2c 0x30 0x33 0x7380 0x7880 0x8000 0x00 0x24 0x24 0x27 0x30 0x33 0x7380 0x7680 0x8000 0x00 0x25 0x20 0x23 0x30 0x33 0x7380 0x7380 0x8000 0x00 0x26 0x1c 0x1f 0x30 0x33 0x7500 0x7380 0x8000 0x00 0x27 0x18 0x1b 0x30 0x33 0x7680 0x7380 0x8000 0x00 0x28 0x14 0x17 0x30 0x33 0x7b00 0x7380 0x8000 0x00 0x29 0x10 0x13 0x30 0x33 0x7e80 0x7380 0x8000 0x00 0x2a 0x0c 0x0f 0x30 0x33 0x8000 0x8000 0x8000 0x00 0x2b 0x08 0x0b 0x30 0x33 0x8000 0x8000 0x8000 0x00 0x2c 0x04 0x07 0x30 0x33 0x8000 0x8000 0x8000 0x00 0x2d 0x00 0x03 0x30 0x33 0x8000 0x8000 0x8000 0x00 0x2e 0x38 0x3b 0x2c 0x2f 0x8000 0x8000 0x8000 0x00 0x2f 0x34 0x37 0x2c 0x2f 0x8000 0x8000 0x8000 0x00 0x30 0x30 0x33 0x2c 0x2f 0x8000 0x8000 0x8000 0x00 0x31 0x2d 0x2f 0x2c 0x2f 0x8000 0x8000 0x8000 0x00 0x32 0x28 0x2c 0x2c 0x2f 0x7380 0x7a00 0x8000 0x00 0x33 0x24 0x27 0x2c 0x2f 0x7380 0x7700 0x8000 0x00 0x34 0x20 0x23 0x2c 0x2f 0x7380 0x7580 0x8000 0x00 0x35 0x1c 0x1f 0x2c 0x2f 0x7600 0x7480 0x8000 0x00 0x36 0x18 0x1b 0x2c 0x2f 0x7980 0x7500 0x8000 0x00 0x37 0x14 0x17 0x2c 0x2f 0x7d80 0x7480 0x8000 0x00 0x38 0x10 0x13 0x2c 0x2f 0x8000 0x7380 0x8000 0x00 0x39 0x0c 0x0f 0x2c 0x2f 0x8000 0x8000 0x8000 0x00 0x3a 0x08 0x0b 0x2c 0x2f 0x8000 0x8000 0x8000 0x00 0x3b 0x04 0x07 0x2c 0x2f 0x8000 0x8000 0x8000 0x00 0x3c 0x00 0x03 0x2c 0x2f 0x8000 0x8000 0x8000 0x00 0x3d 0x38 0x3b 0x28 0x2b 0x8000 0x8000 0x8000 0x00 0x3e 0x34 0x37 0x28 0x2b 0x8000 0x8000 0x8000 0x00 0x3f 0x30 0x33 0x28 0x2b 0x8000 0x8000 0x8000 0x00 0x40 0x2d 0x2f 0x28 0x2b 0x8000 0x8000 0x8000 0x00 0x41 0x28 0x2c 0x28 0x2b 0x6f00 0x7900 0x8000 0x00 0x42 0x24 0x27 0x28 0x2b 0x7280 0x7980 0x8000 0x00 0x43 0x20 0x23 0x28 0x2b 0x7580 0x7900 0x8000 0x00 0x44 0x1c 0x1f 0x28 0x2b 0x7880 0x7880 0x8000 0x00 0x45 0x18 0x1b 0x28 0x2b 0x7c80 0x7800 0x7f80 0x00 0x46 0x14 0x17 0x28 0x2b 0x8000 0x7700 0x7f80 0x00 0x47 0x10 0x13 0x28 0x2b 0x8000 0x7200 0x7a80 0x00 0x48 0x0c 0x0f 0x28 0x2b 0x8000 0x8000 0x8000 0x00 0x49 0x08 0x0b 0x28 0x2b 0x8000 0x8000 0x8000 0x00 0x4a 0x04 0x07 0x28 0x2b 0x8000 0x8000 0x8000 0x00 0x4b 0x00 0x03 0x28 0x2b 0x8000 0x8000 0x8000 0x00 0x4c 0x38 0x3b 0x24 0x27 0x8000 0x8000 0x8000 0x00 0x4d 0x34 0x37 0x24 0x27 0x8000 0x8000 0x8000 0x00 0x4e 0x30 0x33 0x24 0x27 0x8000 0x8000 0x8000 0x00 0x4f 0x2d 0x2f 0x24 0x27 0x8000 0x8000 0x8000 0x00 0x50 0x28 0x2c 0x24 0x27 0x7200 0x7c80 0x8000 0x00 0x51 0x24 0x27 0x24 0x27 0x7500 0x7c00 0x7f80 0x00 0x52 0x20 0x23 0x24 0x27 0x7780 0x7b80 0x7f80 0x00 0x53 0x1c 0x1f 0x24 0x27 0x7b80 0x7b80 0x7f80 0x00 0x54 0x18 0x1b 0x24 0x27 0x7e00 0x7b00 0x7f80 0x00 0x55 0x14 0x17 0x24 0x27 0x8000 0x7800 0x7d80 0x00 0x56 0x10 0x13 0x24 0x27 0x8000 0x7200 0x7780 0x00 0x57 0x0c 0x0f 0x24 0x27 0x8000 0x8000 0x8000 0x00 0x58 0x08 0x0b 0x24 0x27 0x8000 0x8000 0x8000 0x00 0x59 0x04 0x07 0x24 0x27 0x8000 0x8000 0x8000 0x00 0x5a 0x00 0x03 0x24 0x27 0x8000 0x8000 0x8000 0x00 0x5b 0x38 0x3b 0x20 0x23 0x8000 0x8000 0x8000 0x00 0x5c 0x34 0x37 0x20 0x23 0x8000 0x8000 0x8000 0x00 0x5d 0x30 0x33 0x20 0x23 0x8000 0x8000 0x8000 0x00 0x5e 0x2d 0x2f 0x20 0x23 0x8000 0x8000 0x8000 0x00 0x5f 0x28 0x2c 0x20 0x23 0x7380 0x7e80 0x7f80 0x00 0x60 0x24 0x27 0x20 0x23 0x7700 0x7e80 0x7f00 0x00 0x61 0x20 0x23 0x20 0x23 0x7900 0x7d00 0x7e80 0x00 0x62 0x1c 0x1f 0x20 0x23 0x7d00 0x7d00 0x7e80 0x00 0x63 0x18 0x1b 0x20 0x23 0x8000 0x7b80 0x7e00 0x00 0x64 0x14 0x17 0x20 0x23 0x8000 0x7600 0x7880 0x00 0x65 0x10 0x13 0x20 0x23 0x8000 0x7200 0x7480 0x00 0x66 0x0c 0x0f 0x20 0x23 0x8000 0x8000 0x8000 0x00 0x67 0x08 0x0b 0x20 0x23 0x8000 0x8000 0x8000 0x00 0x68 0x04 0x07 0x20 0x23 0x8000 0x8000 0x8000 0x00 0x69 0x00 0x03 0x20 0x23 0x8000 0x8000 0x8000 0x00 0x6a 0x38 0x3b 0x1c 0x1f 0x8000 0x8000 0x8000 0x00 0x6b 0x34 0x37 0x1c 0x1f 0x8000 0x8000 0x8000 0x00 0x6c 0x30 0x33 0x1c 0x1f 0x8000 0x8000 0x8000 0x00 0x6d 0x2d 0x2f 0x1c 0x1f 0x8000 0x8000 0x8000 0x00 0x6e 0x28 0x2c 0x1c 0x1f 0x7580 0x8000 0x7e80 0x00 0x6f 0x24 0x27 0x1c 0x1f 0x7800 0x8000 0x7f00 0x00 0x70 0x20 0x23 0x1c 0x1f 0x7a00 0x7e80 0x7d80 0x00 0x71 0x18 0x1b 0x1c 0x1f 0x8000 0x7c00 0x7b80 0x00 0x72 0x14 0x17 0x1c 0x1f 0x8000 0x7700 0x7800 0x00 0x73 0x10 0x13 0x1c 0x1f 0x8000 0x7280 0x7380 0x00 0x74 0x0c 0x0f 0x1c 0x1f 0x8000 0x8000 0x8000 0x00 0x75 0x08 0x0b 0x1c 0x1f 0x8000 0x8000 0x8000 0x00 0x76 0x04 0x07 0x1c 0x1f 0x8000 0x8000 0x8000 0x00 0x77 0x00 0x03 0x1c 0x1f 0x8000 0x8000 0x8000 0x00 0x78 0x38 0x3b 0x18 0x1b 0x8000 0x8000 0x8000 0x00 0x79 0x34 0x37 0x18 0x1b 0x8000 0x8000 0x8000 0x00 0x7a 0x30 0x33 0x18 0x1b 0x8000 0x8000 0x8000 0x00 0x7b 0x2d 0x2f 0x18 0x1b 0x8000 0x8000 0x8000 0x00 0x7c 0x28 0x2c 0x18 0x1b 0x7500 0x8000 0x7c00 0x00 0x7d 0x24 0x27 0x18 0x1b 0x7800 0x8000 0x7c00 0x00 0x7e 0x20 0x23 0x18 0x1b 0x7c00 0x8000 0x7d00 0x00 0x7f 0x1c 0x1f 0x18 0x1b 0x7f80 0x8000 0x7e00 0x00 0x80 0x18 0x1b 0x18 0x1b 0x8000 0x7c00 0x7980 0x00 0x81 0x14 0x17 0x18 0x1b 0x8000 0x7800 0x7600 0x00 0x82 0x10 0x13 0x18 0x1b 0x8000 0x7280 0x7080 0x00 0x83 0x0c 0x0f 0x18 0x1b 0x8000 0x8000 0x8000 0x00 0x84 0x08 0x0b 0x18 0x1b 0x8000 0x8000 0x8000 0x00 0x85 0x04 0x07 0x18 0x1b 0x8000 0x8000 0x8000 0x00 0x86 0x00 0x03 0x18 0x1b 0x8000 0x8000 0x8000 0x00 0x87 0x38 0x3b 0x14 0x17 0x8000 0x8000 0x8000 0x00 0x88 0x34 0x37 0x14 0x17 0x8000 0x8000 0x8000 0x00 0x89 0x30 0x33 0x14 0x17 0x8000 0x8000 0x8000 0x00 0x8a 0x2d 0x2f 0x14 0x17 0x8000 0x8000 0x8000 0x00 0x8b 0x28 0x2c 0x14 0x17 0x7480 0x8000 0x7880 0x00 0x8c 0x24 0x27 0x14 0x17 0x7800 0x8000 0x7900 0x00 0x8d 0x20 0x23 0x14 0x17 0x7c80 0x8000 0x7a00 0x00 0x8e 0x1c 0x1f 0x14 0x17 0x7f00 0x8000 0x7b00 0x00 0x8f 0x18 0x1b 0x14 0x17 0x8000 0x7c00 0x7d00 0x00 0x90 0x14 0x17 0x14 0x17 0x8000 0x7700 0x7980 0x00 0x91 0x10 0x13 0x14 0x17 0x8000 0x7200 0x7500 0x00 0x92 0x0c 0x0f 0x14 0x17 0x8000 0x8000 0x8000 0x00 0x93 0x08 0x0b 0x14 0x17 0x8000 0x8000 0x8000 0x00 0x94 0x04 0x07 0x14 0x17 0x8000 0x8000 0x8000 0x00 0x95 0x00 0x03 0x14 0x17 0x8000 0x8000 0x8000 0x00 0x96 0x38 0x3b 0x10 0x13 0x8000 0x8000 0x8000 0x00 0x97 0x34 0x37 0x10 0x13 0x8000 0x8000 0x8000 0x00 0x98 0x30 0x33 0x10 0x13 0x8000 0x8000 0x8000 0x00 0x99 0x2d 0x2f 0x10 0x13 0x8000 0x8000 0x8000 0x00 0x9a 0x28 0x2c 0x10 0x13 0x7400 0x8000 0x7680 0x00 0x9b 0x24 0x27 0x10 0x13 0x7700 0x8000 0x7680 0x00 0x9c 0x20 0x23 0x10 0x13 0x7c00 0x8000 0x7700 0x00 0x9d 0x1c 0x1f 0x10 0x13 0x8000 0x8000 0x7800 0x00 0x9e 0x18 0x1b 0x10 0x13 0x8000 0x7c00 0x7380 0x00 0x9f 0x14 0x17 0x10 0x13 0x8000 0x7780 0x7100 0x00 0xa0 0x10 0x13 0x10 0x13 0x8000 0x7280 0x6c00 0x00 0xa1 0x0c 0x0f 0x10 0x13 0x8000 0x8000 0x8000 0x00 0xa2 0x08 0x0b 0x10 0x13 0x8000 0x8000 0x8000 0x00 0xa3 0x04 0x07 0x10 0x13 0x8000 0x8000 0x8000 0x00 0xa4 0x00 0x03 0x10 0x13 0x8000 0x8000 0x8000 0x00 0xa5 0x38 0x3b 0x0c 0x0f 0x8000 0x8000 0x8000 0x00 0xa6 0x34 0x37 0x0c 0x0f 0x8000 0x8000 0x8000 0x00 0xa7 0x30 0x33 0x0c 0x0f 0x8000 0x8000 0x8000 0x00 0xa8 0x2d 0x2f 0x0c 0x0f 0x8000 0x8000 0x8000 0x00 0xa9 0x28 0x2c 0x0c 0x0f 0x7580 0x8000 0x7480 0x00 0xaa 0x24 0x27 0x0c 0x0f 0x7780 0x8000 0x7400 0x00 0xab 0x20 0x23 0x0c 0x0f 0x7c00 0x8000 0x7500 0x00 0xac 0x1c 0x1f 0x0c 0x0f 0x7f00 0x8000 0x7600 0x00 0xad 0x18 0x1b 0x0c 0x0f 0x8000 0x8000 0x7380 0x00 0xae 0x14 0x17 0x0c 0x0f 0x8000 0x7a00 0x7380 0x00 0xaf 0x10 0x13 0x0c 0x0f 0x8000 0x7800 0x7380 0x00 0xb0 0x0c 0x0f 0x0c 0x0f 0x8000 0x8000 0x8000 0x00 0xb1 0x08 0x0b 0x0c 0x0f 0x8000 0x8000 0x8000 0x00 0xb2 0x04 0x07 0x0c 0x0f 0x8000 0x8000 0x8000 0x00 0xb3 0x00 0x03 0x0c 0x0f 0x8000 0x8000 0x8000 0x00 0xb4 0x38 0x3b 0x08 0x0b 0x8000 0x8000 0x8000 0x00 0xb5 0x34 0x37 0x08 0x0b 0x8000 0x8000 0x8000 0x00 0xb6 0x30 0x33 0x08 0x0b 0x8000 0x8000 0x8000 0x00 0xb7 0x2d 0x2f 0x08 0x0b 0x8000 0x8000 0x8000 0x00 0xb8 0x28 0x2c 0x08 0x0b 0x7500 0x8000 0x7380 0x00 0xb9 0x24 0x27 0x08 0x0b 0x7800 0x8000 0x7380 0x00 0xba 0x20 0x23 0x08 0x0b 0x7c80 0x8000 0x7380 0x00 0xbb 0x1c 0x1f 0x08 0x0b 0x8000 0x8000 0x7380 0x00 0xbc 0x18 0x1b 0x08 0x0b 0x8000 0x7f00 0x7380 0x00 0xbd 0x14 0x17 0x08 0x0b 0x8000 0x7c00 0x7380 0x00 0xbe 0x10 0x13 0x08 0x0b 0x8000 0x7a80 0x7380 0x00 0xbf 0x0c 0x0f 0x08 0x0b 0x8000 0x8000 0x8000 0x00 0xc0 0x08 0x0b 0x08 0x0b 0x8000 0x8000 0x8000 0x00 0xc1 0x04 0x07 0x08 0x0b 0x8000 0x8000 0x8000 0x00 0xc2 0x00 0x03 0x08 0x0b 0x8000 0x8000 0x8000 0x00 0xc3 0x38 0x3b 0x04 0x07 0x8000 0x8000 0x8000 0x00 0xc4 0x34 0x37 0x04 0x07 0x8000 0x8000 0x8000 0x00 0xc5 0x30 0x33 0x04 0x07 0x8000 0x8000 0x8000 0x00 0xc6 0x2c 0x2f 0x04 0x07 0x8000 0x8000 0x8000 0x00 0xc7 0x28 0x2b 0x04 0x07 0x8000 0x8000 0x8000 0x00 0xc8 0x24 0x27 0x04 0x07 0x8000 0x8000 0x8000 0x00 0xc9 0x20 0x23 0x04 0x07 0x8000 0x8000 0x8000 0x00 0xca 0x1c 0x1f 0x04 0x07 0x8000 0x8000 0x8000 0x00 0xcb 0x18 0x1b 0x04 0x07 0x8000 0x8000 0x8000 0x00 0xcc 0x14 0x17 0x04 0x07 0x8000 0x8000 0x8000 0x00 0xcd 0x10 0x13 0x04 0x07 0x8000 0x8000 0x8000 0x00 0xce 0x0c 0x0f 0x04 0x07 0x8000 0x8000 0x8000 0x00 0xcf 0x08 0x0b 0x04 0x07 0x8000 0x8000 0x8000 0x00 0xd0 0x04 0x07 0x04 0x07 0x8000 0x8000 0x8000 0x00 0xd1 0x00 0x03 0x04 0x07 0x8000 0x8000 0x8000 0x00 0xd2 0x38 0x3b 0x00 0x03 0x8000 0x8000 0x8000 0x00 0xd3 0x34 0x37 0x00 0x03 0x8000 0x8000 0x8000 0x00 0xd4 0x30 0x33 0x00 0x03 0x8000 0x8000 0x8000 0x00 0xd5 0x2c 0x2f 0x00 0x03 0x8000 0x8000 0x8000 0x00 0xd6 0x28 0x2b 0x00 0x03 0x8000 0x8000 0x8000 0x00 0xd7 0x24 0x27 0x00 0x03 0x8000 0x8000 0x8000 0x00 0xd8 0x20 0x23 0x00 0x03 0x8000 0x8000 0x8000 0x00 0xd9 0x1c 0x1f 0x00 0x03 0x8000 0x8000 0x8000 0x00 0xda 0x18 0x1b 0x00 0x03 0x8000 0x8000 0x8000 0x00 0xdb 0x14 0x17 0x00 0x03 0x8000 0x8000 0x8000 0x00 0xdc 0x10 0x13 0x00 0x03 0x8000 0x8000 0x8000 0x00 0xdd 0x0c 0x0f 0x00 0x03 0x8000 0x8000 0x8000 0x00 0xde 0x08 0x0b 0x00 0x03 0x8000 0x8000 0x8000 0x00 0xdf 0x04 0x07 0x00 0x03 0x8000 0x8000 0x8000 0x00 0xe0 0x00 0x03 0x00 0x03 0x8000 0x8000 0x8000 0xff 0x00 0x00 0x3b 0x00 0x3b 0x8000 0x8000 0x8000>;
				somc,change-fps-command = [15 01 00 00 00 00 02 ff 24 15 01 00 00 00 00 02 92 94 15 01 00 00 00 00 02 ff 10 39 01 00 00 00 00 03 44 03 00];
				somc,change-fps-default = <0x94>;
				somc,display-clock = <0x1086f50>;
				somc,driver-ic-vbp = <0x04>;
				somc,driver-ic-vfp = <0x0a>;
				somc,change-fps-cmds-num = <0x01>;
				somc,change-fps-payload-num = <0x01>;
				somc,change-wait-update = <0x00>;
				somc,change-wait-on = <0x00 0x00>;
				somc,change-wait-off = <0x00 0x00>;
				somc,change-wait-cmds-num = <0x00 0x00>;
				somc,fps-threshold = <0xb928>;
				somc,te-c-update = <0x01>;
				somc,te-c-mode-60fps = <0x03 0x00>;
				somc,te-c-mode-45fps = <0x04 0xff>;
				somc,te-c-cmds-num = <0x03>;
				somc,te-c-payload-num = <0x01>;
			};

			somc,default_panel_0 {
				qcom,mdss-dsi-panel-name = "default video 0";
				qcom,mdss-dsi-panel-controller = <0x23>;
				qcom,mdss-dsi-panel-type = "dsi_video_mode";
				qcom,mdss-dsi-panel-destination = "display_1";
				qcom,mdss-dsi-panel-framerate = <0x3c>;
				qcom,mdss-dsi-virtual-channel-id = <0x00>;
				qcom,mdss-dsi-stream = <0x00>;
				qcom,mdss-dsi-panel-width = <0x438>;
				qcom,mdss-dsi-panel-height = <0x780>;
				qcom,mdss-dsi-h-front-porch = <0x88>;
				qcom,mdss-dsi-h-back-porch = <0x14>;
				qcom,mdss-dsi-h-pulse-width = <0x3c>;
				qcom,mdss-dsi-h-sync-skew = <0x00>;
				qcom,mdss-dsi-v-back-porch = <0x03>;
				qcom,mdss-dsi-v-front-porch = <0x04>;
				qcom,mdss-dsi-v-pulse-width = <0x02>;
				qcom,mdss-dsi-h-left-border = <0x00>;
				qcom,mdss-dsi-h-right-border = <0x00>;
				qcom,mdss-dsi-v-top-border = <0x00>;
				qcom,mdss-dsi-v-bottom-border = <0x00>;
				qcom,mdss-dsi-bpp = <0x18>;
				qcom,mdss-dsi-underflow-color = <0x00>;
				qcom,mdss-dsi-border-color = <0x00>;
				somc,mdss-dsi-init-command = [15 01 00 00 00 00 02 bb 03 39 01 00 00 00 00 06 3b 03 05 04 50 88 15 01 00 00 00 00 02 ff 24 15 01 00 00 00 00 02 fb 01 15 01 00 00 00 00 02 c4 9a 15 01 00 00 00 00 02 ff 10];
				qcom,mdss-dsi-on-command = <0x5010000 0x96000111 0x5010000 0x28000129>;
				qcom,mdss-dsi-off-command = [15 01 00 00 00 00 02 ff 10 05 01 00 00 14 00 01 28 05 01 00 00 50 00 01 10];
				qcom,mdss-dsi-on-command-state = "dsi_lp_mode";
				qcom,mdss-dsi-off-command-state = "dsi_hs_mode";
				qcom,mdss-dsi-h-sync-pulse = <0x01>;
				qcom,mdss-dsi-traffic-mode = "non_burst_sync_event";
				qcom,mdss-dsi-bllp-eof-power-mode;
				qcom,mdss-dsi-bllp-power-mode;
				qcom,mdss-dsi-lane-0-state;
				qcom,mdss-dsi-lane-1-state;
				qcom,mdss-dsi-lane-2-state;
				qcom,mdss-dsi-lane-3-state;
				qcom,mdss-dsi-panel-timings = <0xe6382600 0x686e2a3c 0x2c030400>;
				qcom,mdss-dsi-lp11-init;
				qcom,mdss-dsi-t-clk-post = <0x02>;
				qcom,mdss-dsi-t-clk-pre = <0x2b>;
				qcom,mdss-dsi-bl-min-level = <0x01>;
				qcom,mdss-dsi-bl-max-level = <0xfff>;
				qcom,mdss-brightness-max-level = <0xfff>;
				qcom,mdss-dsi-dma-trigger = "trigger_sw";
				qcom,mdss-dsi-mdp-trigger = "none";
				qcom,mdss-dsi-bl-pmic-control-type = "bl_ctrl_wled";
				qcom,mdss-dsi-pan-enable-dynamic-fps;
				qcom,mdss-dsi-pan-fps-update = "dfps_suspend_resume_mode";
				qcom,cont-splash-enabled;
				qcom,mdss-dsi-tx-eot-append;
				somc,driver-ic = <0x00>;
				somc,dric-gpio = <0x05 0x1a 0x00>;
				somc,touch-reset-gpio = <0x05 0x55 0x00>;
				somc,mul-channel-scaling = <0x03>;
				somc,mdss-phy-size-mm = <0x40 0x72>;
				somc,mdss-dsi-lane-config = [00 c2 ef 00 00 00 00 01 ff 00 c2 ef 00 00 00 00 01 ff 00 c2 ef 00 00 00 00 01 ff 00 c2 ef 00 00 00 00 01 ff 00 02 45 00 00 00 00 01 97];
				somc,mdss-dsi-disp-on-in-hs = <0x01>;
				somc,mdss-dsi-wait-time-before-on-cmd = <0x96>;
				somc,lcd-id = <0x00>;
				somc,lcd-id-adc = <0x00 0x7fffffff>;
				somc,disp-en-on-pre = <0xc8>;
				somc,disp-en-on-post = <0x0a>;
				somc,pw-on-rst-seq = <0x01 0x01 0x00 0x01 0x01 0x14>;
				somc,disp-en-off-post = <0xc8>;
				somc,pw-off-rst-seq = <0x00 0x05>;
				somc,pw-down-period = <0x64>;
				linux,phandle = <0x29>;
				phandle = <0x29>;
			};

			somc,default_panel_1 {
				qcom,mdss-dsi-panel-name = "default video 1";
				qcom,mdss-dsi-panel-controller = <0x23>;
				qcom,mdss-dsi-panel-type = "dsi_video_mode";
				qcom,mdss-dsi-panel-destination = "display_1";
				qcom,mdss-dsi-panel-framerate = <0x3c>;
				qcom,mdss-dsi-virtual-channel-id = <0x00>;
				qcom,mdss-dsi-stream = <0x00>;
				qcom,mdss-dsi-panel-width = <0x438>;
				qcom,mdss-dsi-panel-height = <0x780>;
				qcom,mdss-dsi-h-front-porch = <0x88>;
				qcom,mdss-dsi-h-back-porch = <0x14>;
				qcom,mdss-dsi-h-pulse-width = <0x3c>;
				qcom,mdss-dsi-h-sync-skew = <0x00>;
				qcom,mdss-dsi-v-back-porch = <0x03>;
				qcom,mdss-dsi-v-front-porch = <0x04>;
				qcom,mdss-dsi-v-pulse-width = <0x02>;
				qcom,mdss-dsi-h-left-border = <0x00>;
				qcom,mdss-dsi-h-right-border = <0x00>;
				qcom,mdss-dsi-v-top-border = <0x00>;
				qcom,mdss-dsi-v-bottom-border = <0x00>;
				qcom,mdss-dsi-bpp = <0x18>;
				qcom,mdss-dsi-underflow-color = <0x00>;
				qcom,mdss-dsi-border-color = <0x00>;
				somc,mdss-dsi-init-command = [15 01 00 00 00 00 02 bb 03 39 01 00 00 00 00 06 3b 03 05 04 50 88 15 01 00 00 00 00 02 ff 24 15 01 00 00 00 00 02 fb 01 15 01 00 00 00 00 02 c4 9a 15 01 00 00 00 00 02 ff 10];
				qcom,mdss-dsi-on-command = <0x5010000 0x96000111 0x5010000 0x28000129>;
				qcom,mdss-dsi-off-command = [15 01 00 00 00 00 02 ff 10 05 01 00 00 14 00 01 28 05 01 00 00 50 00 01 10];
				qcom,mdss-dsi-on-command-state = "dsi_lp_mode";
				qcom,mdss-dsi-off-command-state = "dsi_hs_mode";
				qcom,mdss-dsi-h-sync-pulse = <0x01>;
				qcom,mdss-dsi-traffic-mode = "non_burst_sync_event";
				qcom,mdss-dsi-bllp-eof-power-mode;
				qcom,mdss-dsi-bllp-power-mode;
				qcom,mdss-dsi-lane-0-state;
				qcom,mdss-dsi-lane-1-state;
				qcom,mdss-dsi-lane-2-state;
				qcom,mdss-dsi-lane-3-state;
				qcom,mdss-dsi-panel-timings = <0xe6382600 0x686e2a3c 0x2c030400>;
				qcom,mdss-dsi-lp11-init;
				qcom,mdss-dsi-t-clk-post = <0x02>;
				qcom,mdss-dsi-t-clk-pre = <0x2b>;
				qcom,mdss-dsi-bl-min-level = <0x01>;
				qcom,mdss-dsi-bl-max-level = <0xfff>;
				qcom,mdss-brightness-max-level = <0xfff>;
				qcom,mdss-dsi-dma-trigger = "trigger_sw";
				qcom,mdss-dsi-mdp-trigger = "none";
				qcom,mdss-dsi-bl-pmic-control-type = "bl_ctrl_wled";
				qcom,mdss-dsi-pan-enable-dynamic-fps;
				qcom,mdss-dsi-pan-fps-update = "dfps_suspend_resume_mode";
				qcom,cont-splash-enabled;
				qcom,mdss-dsi-tx-eot-append;
				somc,driver-ic = <0x00>;
				somc,dric-gpio = <0x05 0x1a 0x00>;
				somc,touch-reset-gpio = <0x05 0x55 0x00>;
				somc,mul-channel-scaling = <0x03>;
				somc,mdss-phy-size-mm = <0x40 0x72>;
				somc,mdss-dsi-lane-config = [00 c2 ef 00 00 00 00 01 ff 00 c2 ef 00 00 00 00 01 ff 00 c2 ef 00 00 00 00 01 ff 00 c2 ef 00 00 00 00 01 ff 00 02 45 00 00 00 00 01 97];
				somc,mdss-dsi-disp-on-in-hs = <0x01>;
				somc,mdss-dsi-wait-time-before-on-cmd = <0x96>;
				somc,lcd-id = <0x01>;
				somc,lcd-id-adc = <0x00 0x7fffffff>;
				somc,disp-en-on-pre = <0xc8>;
				somc,disp-en-on-post = <0x0a>;
				somc,pw-on-rst-seq = <0x01 0x01 0x00 0x01 0x01 0x14>;
				somc,disp-en-off-post = <0xc8>;
				somc,pw-off-rst-seq = <0x00 0x05>;
				somc,pw-down-period = <0x64>;
			};
		};

		// FIXME something's needed here
		qcom,mdss_dsi@fd922800 {
			compatible = "qcom,mdss-dsi-ctrl";
			label = "MDSS DSI CTRL->0";
			cell-index = <0x00>;
			reg = <0xfd922800 0x1f8 0xfd922b00 0x2b0 0xfdf30000 0x108>;
			reg-names = "dsi_ctrl\0dsi_phy\0mmss_misc_phys";
			vdd-supply = <0x24>;
			vddio-supply = <0x02>;
			vdda-supply = <0x25>;
			qcom,mdss-fb-map = <0x26>;
			qcom,mdss-mdp = <0x27>;
			qcom,platform-reset-gpio = <0x28 0x13 0x00>;
			qcom,platform-enable-gpio = <0x28 0x14 0x00>;
			qcom,platform-te-gpio = <0x05 0x0c 0x00>;
			qcom,platform-strength-ctrl = [ff 06];
			qcom,platform-bist-ctrl = [00 00 b1 ff 00 00];
			qcom,platform-regulator-settings = [07 09 03 00 20 00 01];
			qcom,platform-lane-config;
			qcom,dsi-pref-prim-pan = <0x29>;
			linux,phandle = <0x23>;
			phandle = <0x23>;

			qcom,platform-supply-entry1 {
				qcom,supply-name = "vdd";
				qcom,supply-min-voltage = <0x00>;
				qcom,supply-max-voltage = <0x00>;
				qcom,supply-enable-load = <0x186a0>;
				qcom,supply-disable-load = <0x64>;
				qcom,supply-pre-on-sleep = <0x00>;
				qcom,supply-post-on-sleep = <0x00>;
				qcom,supply-pre-off-sleep = <0x00>;
				qcom,supply-post-off-sleep = <0x00>;
			};

			qcom,platform-supply-entry2 {
				qcom,supply-name = "vddio";
				qcom,supply-min-voltage = <0x1b7740>;
				qcom,supply-max-voltage = <0x1b7740>;
				qcom,supply-enable-load = <0x186a0>;
				qcom,supply-disable-load = <0x64>;
				qcom,supply-pre-on-sleep = <0x00>;
				qcom,supply-post-on-sleep = <0x00>;
				qcom,supply-pre-off-sleep = <0x00>;
				qcom,supply-post-off-sleep = <0x00>;
			};

			qcom,platform-supply-entry3 {
				qcom,supply-name = "vdda";
				qcom,supply-min-voltage = <0x124f80>;
				qcom,supply-max-voltage = <0x124f80>;
				qcom,supply-enable-load = <0x186a0>;
				qcom,supply-disable-load = <0x64>;
				qcom,supply-pre-on-sleep = <0x00>;
				qcom,supply-post-on-sleep = <0x00>;
				qcom,supply-pre-off-sleep = <0x00>;
				qcom,supply-post-off-sleep = <0x00>;
			};
		};

		qcom,spmi@fc4c0000 {
			cell-index = <0x00>;
			compatible = "qcom,spmi-pmic-arb";
			reg-names = "core\0intr\0cnfg";
			reg = <0xfc4cf000 0x1000 0xfc4cb000 0x1000 0xfc4ca000 0x1000>;
			interrupts = <0x00 0xbe 0x00 0x00 0xbb 0x00>;
			qcom,pmic-arb-ee = <0x00>;
			qcom,pmic-arb-channel = <0x00>;
			#address-cells = <0x01>;
			#size-cells = <0x00>;
			interrupt-controller;
			#interrupt-cells = <0x03>;
			linux,phandle = <0x60>;
			phandle = <0x60>;

			qcom,pm8941@0 {
				reg = <0x00>;
				spmi-slave-container;
				#address-cells = <0x01>;
				#size-cells = <0x01>;

				gpios {
					spmi-dev-container;
					compatible = "qcom,qpnp-pin";
					gpio-controller;
					#gpio-cells = <0x02>;
					#address-cells = <0x01>;
					#size-cells = <0x01>;
					label = "pm8941-gpio";
					linux,phandle = <0x28>;
					phandle = <0x28>;
				};
			};

			qcom,pm8941@1 {
				reg = <0x01>;
				spmi-slave-container;
				#address-cells = <0x01>;
				#size-cells = <0x01>;

				qcom,leds@d800 {
					compatible = "qcom,leds-qpnp";
					reg = <0xd800 0x100>;
					label = "wled";
					status = "okay";

					qcom,wled_0 {
						label = "wled";
						linux,name = "wled:backlight";
						linux,default-trigger = "bkl-trigger";
						qcom,cs-out-en = <0x01>;
						qcom,op-fdbck = <0x00>;
						qcom,default-state = "on";
						qcom,max-current = <0x18>;
						qcom,ctrl-delay-us = <0x00>;
						qcom,boost-curr-lim = <0x03>;
						qcom,cp-sel = <0x00>;
						qcom,switch-freq = <0x0b>;
						qcom,ovp-val = <0x02>;
						qcom,num-strings = <0x02>;
						qcom,id = <0x00>;
						qcom,cabc-en = <0x00>;
						qcom,init-br = <0x6aa>;
						somc-s1,br-power-save = <0x88>;

						qcom,full-scale-seg@0 {
							threshold = <0x3ff>;
							curr = <0x06>;
							coef = <0x04>;
						};

						qcom,full-scale-seg@1 {
							threshold = <0x7ff>;
							curr = <0x0c>;
							coef = <0x02>;
						};
					};
				};
			};
		};
	};
};
